VERSION "HNNBNNNYNNNNNNNNNNNNNNNNNNNNNNNNNNNNNNNNNN/4/%%%/4/'%**4NNN///"

NS_ :

BS_:

BU_: AFS_B8 Airbag_B8 Daempfer_B8 Gateway_B8 Getriebe_AL6000 Getriebe_DL5001 Getriebe_VL3002 LWR_B8 Motor_EDC17_003 Motor_EDC17_004 Motor_MED17_B8 Motor_MED9_B8 Motor_SIMOS8_B8 Motor_Slave_B8 Getriebe_AL1000 Motor_MED17_SIMOS8 Motor_EDC17 Gateway_Routing_PAG Gateway_VW EPB_D4 Motor_EDC17_D4 Motor_MED17_003 Hybrid_MSG Hybrid_DQ200 Motor_ME17_BY Motor_MED17_SIMOS8_D4 Motor_EDC17_B8 Getriebe_AL551_951_D4_C7 Getriebe_AL551_Hybrid_D4_C7 Getriebe_DL501_C7 Getriebe_VL381_C7 Motor_MED17_SIMOS8_D4_Hybrid SCU_D4 Gateway_D4C7 Motor_MED17_Q5_Hybrid Fahrwerk STH_D4 Airbag_D4 Gateway_PAG_002 Gateway_VW_T003 Gateway_D4 LEH_Hybrid SCR_C7 BMS_Hybrid Gateway_App_PAG Getriebe_AL1004 Motor_MED17_006 Getriebe_AL5000

BO_ 262 ESP_05: 8 Gateway_D4C7
 SG_ ESP_05_CHK : 0|8@1+ (1,0) [0|255] ""  EPB_D4,Getriebe_AL551_951_D4_C7,Getriebe_AL551_Hybrid_D4_C7,Getriebe_DL501_C7,Getriebe_VL381_C7,Motor_EDC17_D4,Motor_ME17_BY,Motor_MED17_SIMOS8_D4,Motor_MED17_SIMOS8_D4_Hybrid,SCU_D4
 SG_ ESP_05_BZ : 8|4@1+ (1,0) [0|15] ""  EPB_D4,Getriebe_AL551_951_D4_C7,Getriebe_AL551_Hybrid_D4_C7,Getriebe_DL501_C7,Getriebe_VL381_C7,Motor_EDC17_D4,Motor_ME17_BY,Motor_MED17_SIMOS8_D4,Motor_MED17_SIMOS8_D4_Hybrid,SCU_D4
 SG_ ESP_QBit_Bremsdruck : 12|1@1+ (1,0) [0|1] ""  EPB_D4,Getriebe_AL551_951_D4_C7,Getriebe_AL551_Hybrid_D4_C7,Getriebe_DL501_C7,Motor_EDC17_D4,Motor_ME17_BY,Motor_MED17_SIMOS8_D4,Motor_MED17_SIMOS8_D4_Hybrid
 SG_ ESP_QBit_Fahrer_bremst : 13|1@1+ (1,0) [0|1] ""  Motor_EDC17_D4,Motor_ME17_BY,Motor_MED17_SIMOS8_D4,Motor_MED17_SIMOS8_D4_Hybrid
 SG_ ESP_Schwelle_Unterdruck : 14|2@1+ (1,0) [0|3] "" Vector__XXX
 SG_ ESP_Bremsdruck : 16|10@1+ (0.3,-30) [-30|276.6] "Unit_Bar"  EPB_D4,Getriebe_AL551_951_D4_C7,Getriebe_AL551_Hybrid_D4_C7,Getriebe_DL501_C7,Motor_EDC17_D4,Motor_ME17_BY,Motor_MED17_SIMOS8_D4,Motor_MED17_SIMOS8_D4_Hybrid
 SG_ ESP_Fahrer_bremst : 26|1@1+ (1,0) [0|1] ""  Motor_EDC17_D4,Motor_ME17_BY,Motor_MED17_SIMOS8_D4,Motor_MED17_SIMOS8_D4_Hybrid
 SG_ ESP_Verz_TSK_aktiv : 27|1@1+ (1,0) [0|1] ""  Getriebe_AL551_951_D4_C7,Getriebe_AL551_Hybrid_D4_C7,Motor_EDC17_D4,Motor_ME17_BY,Motor_MED17_SIMOS8_D4,Motor_MED17_SIMOS8_D4_Hybrid
 SG_ ESP_Lenkeingriff_ADS : 28|1@1+ (1,0) [0|1] ""  Motor_EDC17_D4,Motor_ME17_BY,Motor_MED17_SIMOS8_D4,Motor_MED17_SIMOS8_D4_Hybrid,SCU_D4
 SG_ ESP_Konsistenz_TSK : 29|1@1+ (1,0) [0|1] ""  Motor_EDC17_D4,Motor_ME17_BY,Motor_MED17_SIMOS8_D4,Motor_MED17_SIMOS8_D4_Hybrid
 SG_ ESP_Bremsruck_AWV2 : 30|1@1+ (1,0) [0|1] "" Vector__XXX
 SG_ ESP_Konsistenz_AWV2 : 31|1@1+ (1,0) [0|1] "" Vector__XXX
 SG_ ECD_Fehler : 32|1@1+ (1,0) [0|1] ""  Motor_EDC17_D4,Motor_ME17_BY,Motor_MED17_SIMOS8_D4,Motor_MED17_SIMOS8_D4_Hybrid
 SG_ ECD_nicht_verfuegbar : 33|1@1+ (1,0) [0|1] ""  Motor_EDC17_D4,Motor_ME17_BY,Motor_MED17_SIMOS8_D4,Motor_MED17_SIMOS8_D4_Hybrid
 SG_ ESP_Status_Bremsentemp : 34|1@1+ (1,0) [0|1] ""  Motor_EDC17_D4,Motor_ME17_BY,Motor_MED17_SIMOS8_D4,Motor_MED17_SIMOS8_D4_Hybrid
 SG_ ESP_Autohold_Standby : 35|1@1+ (1,0) [0|1] ""  EPB_D4,Getriebe_AL551_951_D4_C7,Getriebe_AL551_Hybrid_D4_C7
 SG_ ESP_HDC_Standby : 36|1@1+ (1,0) [0|1] "" Vector__XXX
 SG_ ESP_HBA_aktiv : 37|1@1+ (1,0) [0|1] "" Vector__XXX
 SG_ ESP_Prefill_ausgeloest : 38|1@1+ (1,0) [0|1] "" Vector__XXX
 SG_ ESP_Rueckwaertsfahrt_erkannt : 39|1@1+ (1,0) [0|1] ""  Motor_EDC17_D4,Motor_ME17_BY,Motor_MED17_SIMOS8_D4,Motor_MED17_SIMOS8_D4_Hybrid
 SG_ ESP_Status_Anfahrhilfe : 40|1@1+ (1,0) [0|1] ""  Motor_EDC17_D4,Motor_MED17_SIMOS8_D4,Motor_MED17_SIMOS8_D4_Hybrid
 SG_ ESP_HDC_aktiv : 41|1@1+ (1,0) [0|1] "" Vector__XXX
 SG_ ESP_StartStopp_Info : 42|2@1+ (1,0) [0|3] ""  Motor_EDC17_D4,Motor_ME17_BY,Motor_MED17_SIMOS8_D4,Motor_MED17_SIMOS8_D4_Hybrid
 SG_ ESP_Eingr_HL : 44|1@1+ (1,0) [0|1] "" Vector__XXX
 SG_ ESP_Eingr_HR : 45|1@1+ (1,0) [0|1] "" Vector__XXX
 SG_ ESP_Eingr_VL : 46|1@1+ (1,0) [0|1] "" Vector__XXX
 SG_ ESP_Eingr_VR : 47|1@1+ (1,0) [0|1] "" Vector__XXX
 SG_ ESP_BKV_Unterdruck : 48|8@1+ (4,0) [0|1012] "Unit_MilliBar"  Motor_EDC17_D4,Motor_ME17_BY,Motor_MED17_SIMOS8_D4,Motor_MED17_SIMOS8_D4_Hybrid
 SG_ ESP_Autohold_aktiv : 56|1@1+ (1,0) [0|1] ""  EPB_D4,Getriebe_AL551_951_D4_C7,Getriebe_AL551_Hybrid_D4_C7,Getriebe_DL501_C7,Getriebe_VL381_C7,Motor_EDC17_D4,Motor_ME17_BY,Motor_MED17_SIMOS8_D4,Motor_MED17_SIMOS8_D4_Hybrid
 SG_ ESP_FStatus_Anfahrhilfe : 57|1@1+ (1,0) [0|1] "" Vector__XXX
 SG_ ESP_Verz_EPB_aktiv : 58|1@1+ (1,0) [0|1] ""  EPB_D4,Getriebe_AL551_951_D4_C7,Getriebe_AL551_Hybrid_D4_C7
 SG_ ECD_Bremslicht : 59|1@1+ (1,0) [0|1] ""  Motor_EDC17_D4,Motor_ME17_BY,Motor_MED17_SIMOS8_D4,Motor_MED17_SIMOS8_D4_Hybrid
 SG_ ESP_Verzoeg_EPB_verf : 60|1@1+ (1,0) [0|1] ""  EPB_D4
 SG_ ESP_Status_Bremsdruck : 61|1@1+ (1,0) [0|1] ""  EPB_D4,Motor_EDC17_D4,Motor_ME17_BY,Motor_MED17_SIMOS8_D4,Motor_MED17_SIMOS8_D4_Hybrid
 SG_ ESP_Anforderung_EPB : 62|2@1+ (1,0) [0|3] ""  EPB_D4

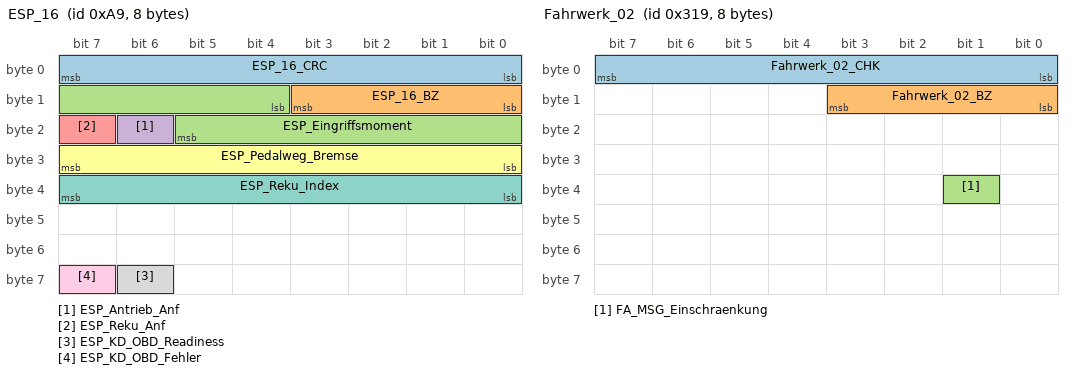
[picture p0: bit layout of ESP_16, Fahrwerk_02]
BO_ 169 ESP_16: 8 Gateway_B8
 SG_ ESP_16_CRC : 0|8@1+ (1,0) [0|255] ""  Motor_MED17_Q5_Hybrid
 SG_ ESP_16_BZ : 8|4@1+ (1,0) [0|15] ""  Motor_MED17_Q5_Hybrid
 SG_ ESP_Eingriffsmoment : 12|10@1+ (1,-509) [-509|509] "Unit_NewtoMeter"  Motor_MED17_Q5_Hybrid
 SG_ ESP_Antrieb_Anf : 22|1@1+ (1,0) [0|1] ""  Motor_MED17_Q5_Hybrid
 SG_ ESP_Reku_Anf : 23|1@1+ (1,0) [0|1] ""  Motor_MED17_Q5_Hybrid
 SG_ ESP_Pedalweg_Bremse : 24|8@1+ (0.2,0) [0|50] "Unit_DegreOfArc"  Motor_MED17_Q5_Hybrid
 SG_ ESP_Reku_Index : 32|8@1+ (0.0039526,0) [0|1] "-"  Motor_MED17_Q5_Hybrid
 SG_ ESP_KD_OBD_Readiness : 62|1@1+ (1,0) [0|1] ""  Motor_MED17_Q5_Hybrid
 SG_ ESP_KD_OBD_Fehler : 63|1@1+ (1,0) [0|1] ""  Motor_MED17_Q5_Hybrid

BO_ 914 ESP_07_FR: 8 Gateway_B8
 SG_ ESP_07_CHK : 0|8@1+ (1,0) [0|255] ""  Motor_MED17_Q5_Hybrid
 SG_ ESP_07_BZ : 8|4@1+ (1,0) [0|15] ""  Motor_MED17_Q5_Hybrid
 SG_ ESP_ACC_LDE : 12|1@1+ (1,0) [0|1] "" Vector__XXX
 SG_ ESP_Quattro_Antrieb : 13|1@1+ (1,0) [0|1] "" Vector__XXX
 SG_ ESP_Codierung_ADS : 14|2@1+ (1,0) [0|3] "" Vector__XXX
 SG_ ESP_RTA_HL : 16|8@1+ (0.048828125,-6.20117) [-6.20117|6.152345625] "Unit_PerCent" Vector__XXX
 SG_ ESP_RTA_HR : 24|8@1+ (0.048828125,-6.20117) [-6.20117|6.152345625] "Unit_PerCent" Vector__XXX
 SG_ ESP_RTA_VR : 32|8@1+ (0.048828125,-6.20117) [-6.20117|6.152345625] "Unit_PerCent" Vector__XXX
 SG_ OBD_Fehler_Radsensor_HL : 40|4@1+ (1,0) [0|15] ""  Motor_MED17_Q5_Hybrid
 SG_ OBD_Fehler_Radsensor_HR : 44|4@1+ (1,0) [0|15] ""  Motor_MED17_Q5_Hybrid
 SG_ OBD_Fehler_Radsensor_VL : 48|4@1+ (1,0) [0|15] ""  Motor_MED17_Q5_Hybrid
 SG_ OBD_Fehler_Radsensor_VR : 52|4@1+ (1,0) [0|15] ""  Motor_MED17_Q5_Hybrid
 SG_ ESP_Qualifizierung_Antriebsart : 56|1@1+ (1,0) [0|1] "" Vector__XXX
 SG_ ESP_Offroad_Modus : 57|1@1+ (1,0) [0|1] "" Vector__XXX
 SG_ ESP_MKB_ausloesbar : 58|1@1+ (1,0) [0|1] "" Vector__XXX
 SG_ ESP_MKB_Status : 59|1@1+ (1,0) [0|1] "" Vector__XXX
 SG_ ESP_CM_Variante : 60|1@1+ (1,0) [0|1] "" Vector__XXX
 SG_ ESP_OBD_Status : 61|1@1+ (1,0) [0|1] ""  Motor_MED17_Q5_Hybrid
 SG_ ESP_Rollenmodus_Deaktivieren : 62|1@1+ (1,0) [0|1] ""  Motor_MED17_Q5_Hybrid
 SG_ ESP_nachtr_Stopp_Anf : 63|1@1+ (1,0) [0|1] ""  Motor_MED17_Q5_Hybrid

BO_ 277 Allrad_02: 8 Gateway_Routing_PAG
 SG_ ALR_Sta_Laengssperre : 12|2@1+ (1,0) [0|3] "" Vector__XXX
 SG_ ALR_Sta_Quersperre : 14|2@1+ (1,0) [0|3] "" Vector__XXX
 SG_ ALR_Sta_Untersetzung : 16|3@1+ (1,0) [0|7] ""  Getriebe_AL1000,Motor_EDC17,Motor_MED17_SIMOS8
 SG_ ALR_Limiter : 20|1@1+ (1,0) [0|1] ""  Motor_EDC17,Motor_MED17_SIMOS8
 SG_ ALR_Schalten : 21|1@1+ (1,0) [0|1] ""  Getriebe_AL1000
 SG_ ALR_Vorwarnung : 22|1@1+ (1,0) [0|1] ""  Getriebe_AL1000
 SG_ ALR_ESP_akt : 23|1@1+ (1,0) [0|1] "" Vector__XXX
 SG_ ALR_Begrenzungsmoment : 24|10@1+ (1,0) [0|1021] ""  Motor_EDC17,Motor_MED17_SIMOS8
 SG_ ALR_Charisma_Umschaltung : 34|2@1+ (1,0) [0|3] "" Vector__XXX
 SG_ ALR_Temp_schutz : 36|1@1+ (1,0) [0|1] "" Vector__XXX
 SG_ ALR_Offroad : 37|1@1+ (1,0) [0|1] ""  Getriebe_AL1000,Motor_EDC17,Motor_MED17_SIMOS8
 SG_ ALR_Sta_Begrenzungsmom : 38|2@1+ (1,0) [0|3] "" Vector__XXX
 SG_ ALR_Charisma_FahrPr : 40|3@1+ (1,0) [0|7] "" Vector__XXX
 SG_ ALR_Charisma_Status : 43|2@1+ (1,0) [0|3] "" Vector__XXX
 SG_ ALR_Fahrerwunsch : 45|3@1+ (1,0) [0|7] "" Vector__XXX
 SG_ ALR_Symbol_Low : 48|1@1+ (1,0) [0|1] "" Vector__XXX
 SG_ ALR_Symbol_Lock : 49|1@1+ (1,0) [0|1] "" Vector__XXX
 SG_ ALR_Symbol_RearLock : 50|1@1+ (1,0) [0|1] "" Vector__XXX
 SG_ ALR_Texte : 51|5@1+ (1,0) [0|31] "" Vector__XXX
 SG_ ALR_Sta_PrioAnzeige : 56|1@1+ (1,0) [0|1] "" Vector__XXX
 SG_ ALR_LED_Auto_Diff : 58|1@1+ (1,0) [0|1] "" Vector__XXX
 SG_ ALR_LED_High : 59|1@1+ (1,0) [0|1] "" Vector__XXX
 SG_ ALR_LED_Low : 60|1@1+ (1,0) [0|1] "" Vector__XXX
 SG_ ALR_LED_Low_Lock : 61|1@1+ (1,0) [0|1] "" Vector__XXX
 SG_ ALR_LED_Rear_Lock : 62|1@1+ (1,0) [0|1] "" Vector__XXX
 SG_ ALR_KD_Fehler : 63|1@1+ (1,0) [0|1] "" Vector__XXX

BO_ 793 Fahrwerk_02: 8 Fahrwerk
 SG_ Fahrwerk_02_CHK : 0|8@1+ (1,0) [0|255] "" Vector__XXX
 SG_ Fahrwerk_02_BZ : 8|4@1+ (1,0) [0|15] "" Vector__XXX
 SG_ FA_MSG_Einschraenkung : 33|1@1+ (1,0) [0|1] "" Vector__XXX

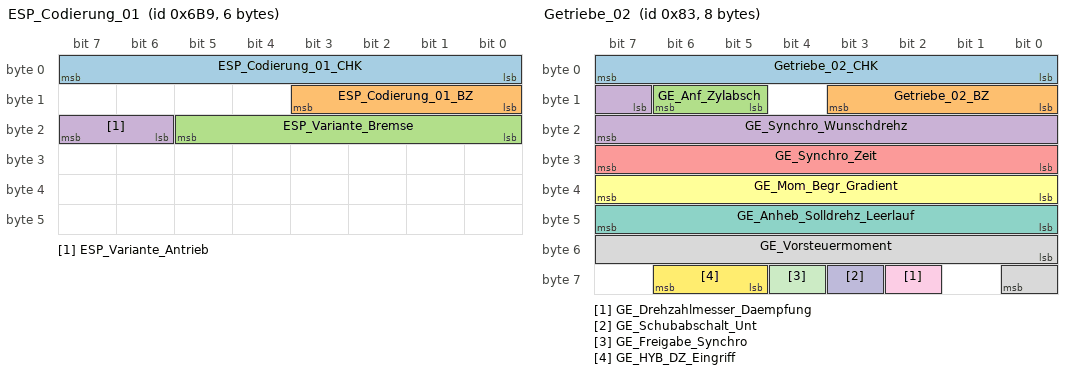
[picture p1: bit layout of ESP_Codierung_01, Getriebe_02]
BO_ 1721 ESP_Codierung_01: 6 Airbag_B8
 SG_ ESP_Codierung_01_CHK : 0|8@1+ (1,0) [0|255] ""  Gateway_B8
 SG_ ESP_Codierung_01_BZ : 8|4@1+ (1,0) [0|15] ""  Gateway_B8
 SG_ ESP_Variante_Bremse : 16|6@1+ (1,0) [0|63] ""  Gateway_B8
 SG_ ESP_Variante_Antrieb : 22|2@1+ (1,0) [0|3] ""  Gateway_B8

BO_ 264 Fahrwerk_01: 8 Daempfer_B8
 SG_ Fahrwerk_01_CHK : 0|8@1+ (1,0) [0|255] ""  Gateway_B8
 SG_ Fahrwerk_01_BZ : 8|4@1+ (1,0) [0|15] ""  Gateway_B8
 SG_ FA_Hoehenwerte_kalibriert M : 12|1@1+ (1,0) [0|1] ""  AFS_B8,Gateway_B8,LWR_B8
 SG_ FA_Hoehenwert_VL_00 m0 : 16|8@1+ (1,-127) [-127|126] "mm"  AFS_B8,Gateway_B8,LWR_B8
 SG_ FA_Hoehenwert_VL_01 m1 : 16|8@1+ (0.4,0) [0|100] "%"  AFS_B8,Gateway_B8,LWR_B8
 SG_ FA_Hoehenwert_VR_00 m0 : 24|8@1+ (1,-127) [-127|126] "mm"  AFS_B8,Gateway_B8,LWR_B8
 SG_ FA_Hoehenwert_VR_01 m1 : 24|8@1+ (0.4,0) [0|100] "%"  AFS_B8,Gateway_B8,LWR_B8
 SG_ FA_Hoehenwert_HL_00 m0 : 32|8@1+ (1,-127) [-127|126] "mm"  AFS_B8,Gateway_B8,LWR_B8
 SG_ FA_Hoehenwert_HL_01 m1 : 32|8@1+ (0.4,0) [0|100] "%"  AFS_B8,Gateway_B8,LWR_B8
 SG_ FA_Hoehenwert_HR_00 m0 : 40|8@1+ (1,-127) [-127|126] "mm"  AFS_B8,Gateway_B8,LWR_B8
 SG_ FA_Hoehenwert_HR_01 m1 : 40|8@1+ (0.4,0) [0|100] "%"  AFS_B8,Gateway_B8,LWR_B8

BO_ 924 Gateway_05: 8 Gateway_B8
 SG_ BCM1_Schalter_StartStopp : 55|1@1+ (1,0) [0|0] "" Vector__XXX
 SG_ PH_StartStopp_Info : 28|2@1+ (1,0) [0|0] "" Vector__XXX
 SG_ BCM1_02_alt : 0|1@1+ (1,0) [0|1] ""  Motor_EDC17_D4,Motor_MED17_003
 SG_ Wischer_01_alt : 1|1@1+ (1,0) [0|1] ""  Motor_EDC17_D4
 SG_ Klima_02_alt : 2|1@1+ (1,0) [0|1] ""  STH_D4
 SG_ BCM1_01_alt : 3|1@1+ (1,0) [0|1] ""  EPB_D4,Motor_EDC17_D4,Motor_MED17_003
 SG_ ESP_07_alt : 4|1@1+ (1,0) [0|1] ""  Airbag_D4,Motor_EDC17_D4,Motor_MED17_003
 SG_ TSG_BT_1_alt : 5|1@1+ (1,0) [0|1] "" Vector__XXX
 SG_ TSG_HL_1_alt : 6|1@1+ (1,0) [0|1] "" Vector__XXX
 SG_ TSG_HR_1_alt : 7|1@1+ (1,0) [0|1] "" Vector__XXX
 SG_ Motor_02_alt : 8|1@1+ (1,0) [0|1] ""  SCU_D4
 SG_ Klima_Sensor_02_alt : 9|1@1+ (1,0) [0|1] ""  Motor_EDC17_D4,Motor_MED17_003
 SG_ TSG_FT_1_alt : 10|1@1+ (1,0) [0|1] ""  Motor_EDC17_D4,Motor_MED17_003
 SG_ Motor_05_alt : 11|1@1+ (1,0) [0|1] ""  STH_D4
 SG_ QSP_01_alt : 12|1@1+ (1,0) [0|1] ""  Motor_EDC17_D4,Motor_MED17_003
 SG_ Parkhilfe_01_alt : 13|1@1+ (1,0) [0|1] ""  Motor_EDC17_D4,Motor_MED17_003
 SG_ Fahrwerk_02_alt : 14|1@1+ (1,0) [0|1] ""  Motor_EDC17_D4,Motor_MED17_003
 SG_ GW_05_va_27 : 15|1@1+ (1,0) [0|1] "" Vector__XXX
 SG_ BCM1_MH_WIV_Schalter : 16|1@1+ (1,0) [0|1] ""  Motor_EDC17_D4,Motor_MED17_003
 SG_ Wischer_vorne_aktiv : 17|1@1+ (1,0) [0|1] ""  Motor_EDC17_D4
 SG_ BCM1_Rueckfahrlicht_Schalter : 18|1@1+ (1,0) [0|1] ""  EPB_D4,Motor_EDC17_D4,Motor_MED17_003
 SG_ MO_Status_Normalbetrieb_01 : 19|1@1+ (1,0) [0|1] ""  SCU_D4
 SG_ KL_Zuheizer_Freigabe : 20|1@1+ (1,0) [0|1] ""  STH_D4
 SG_ BCM1_Vorwaertsgang_eingelegt : 21|1@1+ (1,0) [0|1] ""  EPB_D4
 SG_ ESP_Codierung_ADS : 22|2@1+ (1,0) [0|3] ""  Airbag_D4,Motor_EDC17_D4,Motor_MED17_003
 SG_ QSP_StartStopp_Info : 24|2@1+ (1,0) [0|3] ""  Motor_EDC17_D4,Motor_MED17_003
 SG_ FA_StartStopp_Info : 26|2@1+ (1,0) [0|3] ""  Motor_EDC17_D4,Motor_MED17_003
 SG_ PH_StartStopp_Info : 28|2@1+ (1,0) [0|3] ""  Motor_EDC17_D4,Motor_MED17_003
 SG_ BCM1_RFahrlicht_Fzg_Anf : 32|1@1+ (1,0) [0|1] "" Vector__XXX
 SG_ FT_Tuer_geoeffnet : 33|1@1+ (1,0) [0|1] ""  Motor_EDC17_D4,Motor_MED17_003
 SG_ MO_Handshake_STH : 34|1@1+ (1,0) [0|1] ""  STH_D4
 SG_ FT_Sperrklinke : 35|1@1+ (1,0) [0|1] "" Vector__XXX
 SG_ BCM1_OBD_FStatus_ATemp : 36|4@1+ (1,0) [0|15] ""  Airbag_D4,Motor_EDC17_D4,Motor_MED17_003
 SG_ BCM1_Aussen_Temp_ungef : 40|8@1+ (0.5,-50) [-50|76] "Unit_DegreCelsi"  Airbag_D4,Motor_EDC17_D4,Motor_MED17_003
 SG_ BCM1_Oeldruck_Schalter : 48|1@1+ (1,0) [0|1] ""  Motor_EDC17_D4,Motor_MED17_003
 SG_ BCM1_Oeldruck_Schalter_2 : 49|1@1+ (1,0) [0|1] "" Vector__XXX
 SG_ BT_Tuer_geoeffnet : 50|1@1+ (1,0) [0|1] "" Vector__XXX
 SG_ HL_Tuer_geoeffnet : 51|1@1+ (1,0) [0|1] "" Vector__XXX
 SG_ HR_Tuer_geoeffnet : 52|1@1+ (1,0) [0|1] "" Vector__XXX
 SG_ BCM1_Adaptive_Lichtvert_Anf : 53|1@1+ (1,0) [0|1] "" Vector__XXX
 SG_ BCM1_Gleitende_Leuchtw_Anf : 54|1@1+ (1,0) [0|1] "" Vector__XXX
 SG_ BCM1_Schalter_StartStopp : 55|1@1+ (1,0) [0|1] ""  Motor_EDC17_D4,Motor_MED17_003
 SG_ KL_HSH_ein_Soll : 59|1@1+ (1,0) [0|1] ""  Motor_EDC17_D4,Motor_MED17_003

BO_ 1604 Gateway_11: 8 Gateway_D4C7
 SG_ SMLS_01_alt : 0|1@1+ (1,0) [0|1] ""  Motor_EDC17_D4,Motor_ME17_BY,Motor_MED17_SIMOS8_D4
 SG_ HUD_01_alt : 1|1@1+ (1,0) [0|1] "" Vector__XXX
 SG_ BCM1_01_alt : 2|1@1+ (1,0) [0|1] "" Vector__XXX
 SG_ BCM1_02_alt : 3|1@1+ (1,0) [0|1] ""  Motor_EDC17_D4,Motor_ME17_BY,Motor_MED17_SIMOS8_D4
 SG_ BCM2_02_alt : 4|1@1+ (1,0) [0|1] ""  Getriebe_VL381_C7
 SG_ HYB_Anf_E_Mode_alt : 5|1@1+ (1,0) [0|1] "" Vector__XXX
 SG_ BCM1_04_alt : 6|1@1+ (1,0) [0|1] "" Vector__XXX
 SG_ ESP_04_alt : 7|1@1+ (1,0) [0|1] ""  SCU_D4
 SG_ GW_11_va_20 : 8|1@1+ (1,0) [0|1] "" Vector__XXX
 SG_ GW_11_va_21 : 9|1@1+ (1,0) [0|1] "" Vector__XXX
 SG_ GW_11_va_22 : 10|1@1+ (1,0) [0|1] "" Vector__XXX
 SG_ GW_11_va_23 : 11|1@1+ (1,0) [0|1] "" Vector__XXX
 SG_ GW_11_va_24 : 12|1@1+ (1,0) [0|1] "" Vector__XXX
 SG_ GW_11_va_25 : 13|1@1+ (1,0) [0|1] "" Vector__XXX
 SG_ GW_11_va_26 : 14|1@1+ (1,0) [0|1] "" Vector__XXX
 SG_ GW_11_va_27 : 15|1@1+ (1,0) [0|1] "" Vector__XXX
 SG_ BH_Blinker_li : 16|1@1+ (1,0) [0|1] ""  Motor_EDC17_D4,Motor_ME17_BY,Motor_MED17_SIMOS8_D4
 SG_ BH_Blinker_re : 17|1@1+ (1,0) [0|1] ""  Motor_EDC17_D4,Motor_ME17_BY,Motor_MED17_SIMOS8_D4
 SG_ BM_Autobahn : 18|1@1+ (1,0) [0|1] "" Vector__XXX
 SG_ BH_Fernlicht : 19|1@1+ (1,0) [0|1] "" Vector__XXX
 SG_ BH_Lichthupe : 20|1@1+ (1,0) [0|1] "" Vector__XXX
 SG_ BCM1_MH_Schalter : 21|1@1+ (1,0) [0|1] ""  Motor_EDC17_D4,Motor_ME17_BY,Motor_MED17_SIMOS8_D4
 SG_ HYB_Anf_E_Mode : 22|1@1+ (1,0) [0|1] "" Vector__XXX
 SG_ HUD_NV_in_Anzeige : 23|1@1+ (1,0) [0|1] "" Vector__XXX
 SG_ BCM1_Touristen_Licht_Anf : 24|1@1+ (1,0) [0|1] "" Vector__XXX
 SG_ LV_Abblendlicht_li_def : 25|1@1+ (1,0) [0|1] "" Vector__XXX
 SG_ LV_Abblendlicht_re_def : 26|1@1+ (1,0) [0|1] "" Vector__XXX
 SG_ LV_Abblendlicht_Anzeige : 27|1@1+ (1,0) [0|1] "" Vector__XXX
 SG_ LV_AFL_aktiv_Anzeige : 28|1@1+ (1,0) [0|1] "" Vector__XXX
 SG_ BCM1_Licht_Dunkelheit_aktiv : 29|1@1+ (1,0) [0|1] "" Vector__XXX
 SG_ LV_Nebelschlusslicht_Anzeige : 30|1@1+ (1,0) [0|1] "" Vector__XXX
 SG_ BCM1_Linksverkehr : 31|1@1+ (1,0) [0|1] "" Vector__XXX
 SG_ BCM2_P_verriegelt : 32|1@1+ (1,0) [0|1] ""  Getriebe_VL381_C7
 SG_ BCM1_LDS_Stellung : 33|3@1+ (1,0) [0|7] "" Vector__XXX
 SG_ BCM1_Allwetterlicht_Anf : 36|1@1+ (1,0) [0|1] "" Vector__XXX
 SG_ HUD_Anzeigefehler_NV : 37|1@1+ (1,0) [0|1] "" Vector__XXX
 SG_ ESP_Diagnose : 38|1@1+ (1,0) [0|1] ""  SCU_D4
 SG_ ZV_Tankklappenstatus : 39|1@1+ (1,0) [0|1] "" Vector__XXX
 SG_ BCM_Tankwunsch : 40|1@1+ (1,0) [0|1] "" Vector__XXX

BO_ 1138 Gateway_MED9_01: 8 Gateway_B8
 SG_ Anhaenger_01_alt : 0|1@1+ (1,0) [0|1] ""  Motor_MED9_B8
 SG_ GW_MED9_01_va_11 : 1|1@1+ (1,0) [0|1] "" Vector__XXX
 SG_ Kombi_01_alt : 2|1@1+ (1,0) [0|1] ""  Motor_MED9_B8
 SG_ STH_01_alt : 3|1@1+ (1,0) [0|1] ""  Motor_MED9_B8
 SG_ Licht_hinten_01_alt : 4|1@1+ (1,0) [0|1] ""  Motor_MED9_B8
 SG_ GW_MED9_01_va_15 : 5|1@1+ (1,0) [0|1] ""  Motor_MED9_B8
 SG_ GW_MED9_01_va_16 : 6|1@1+ (1,0) [0|1] ""  Motor_MED9_B8
 SG_ GW_MED9_01_va_17 : 7|1@1+ (1,0) [0|1] ""  Motor_MED9_B8
 SG_ AAG_BZ : 8|4@1+ (1,0) [0|15] ""  Motor_MED9_B8
 SG_ AAG_Bremsl_durch_ECD : 12|1@1+ (1,0) [0|1] ""  Motor_MED9_B8
 SG_ AAG_Anhaenger_erkannt : 13|1@1+ (1,0) [0|1] ""  Motor_MED9_B8
 SG_ AAG_Bremslicht_H_def : 14|1@1+ (1,0) [0|1] ""  Motor_MED9_B8
 SG_ KBI_Tankwarnung : 27|1@1+ (1,0) [0|1] ""  Motor_MED9_B8
 SG_ KBI_MFA_v_Einheit_01 : 28|1@1+ (1,0) [0|1] ""  Motor_MED9_B8
 SG_ KBI_Einheit_Tacho : 29|1@1+ (1,0) [0|1] ""  Motor_MED9_B8
 SG_ KBI_angez_Geschw : 30|10@1+ (0.32,0) [0|325.12] "km/h"  Motor_MED9_B8
 SG_ STH_Ventiloeffnungszeit : 40|6@1+ (1,0) [0|63] "min"  Motor_MED9_B8
 SG_ STH_EKP_Anst : 46|1@1+ (1,0) [0|1] ""  Motor_MED9_B8
 SG_ STH_Motorvorwaermung : 47|1@1+ (1,0) [0|1] ""  Motor_MED9_B8
 SG_ STH_Waermeeintrag : 48|6@1+ (1,0) [0|63] ""  Motor_MED9_B8
 SG_ STH_war_aktiv : 54|1@1+ (1,0) [0|1] ""  Motor_MED9_B8
 SG_ Licht_hinten_01_BZ : 56|4@1+ (1,0) [0|15] ""  Motor_MED9_B8
 SG_ BCM2_Bremsl_durch_ECD : 60|1@1+ (1,0) [0|1] ""  Motor_MED9_B8
 SG_ LH_3_Bremsl_def : 61|1@1+ (1,0) [0|1] ""  Motor_MED9_B8
 SG_ LH_Bremsl_li_ges_def : 62|1@1+ (1,0) [0|1] ""  Motor_MED9_B8
 SG_ LH_Bremsl_re_ges_def : 63|1@1+ (1,0) [0|1] ""  Motor_MED9_B8

BO_ 130 Getriebe_01: 8 Getriebe_AL6000
 SG_ Getriebe_01_CHK : 0|8@1+ (1,0) [0|255] ""  Gateway_B8,Motor_EDC17_003,Motor_EDC17_004,Motor_MED17_B8,Motor_MED9_B8,Motor_SIMOS8_B8
 SG_ Getriebe_01_BZ : 8|4@1+ (1,0) [0|15] ""  Gateway_B8,Motor_EDC17_003,Motor_EDC17_004,Motor_MED17_B8,Motor_MED9_B8,Motor_SIMOS8_B8
 SG_ GE_Schaltvorgang : 12|1@1+ (1,0) [0|1] ""  Gateway_B8,Motor_EDC17_003,Motor_EDC17_004,Motor_MED17_B8,Motor_MED9_B8,Motor_SIMOS8_B8
 SG_ GE_Status_Kupplung : 13|2@1+ (1,0) [0|3] ""  Gateway_B8,Motor_EDC17_003,Motor_EDC17_004,Motor_MED17_B8,Motor_MED9_B8,Motor_SIMOS8_B8
 SG_ GE_Verbot_Ausblendung : 15|1@1+ (1,0) [0|1] ""  Gateway_B8,Motor_EDC17_003,Motor_EDC17_004,Motor_MED17_B8,Motor_MED9_B8,Motor_SIMOS8_B8
 SG_ GE_MMom_Soll : 16|10@1+ (1,0) [0|1021] ""  Gateway_B8,Motor_EDC17_003,Motor_EDC17_004,Motor_MED17_B8,Motor_MED9_B8,Motor_SIMOS8_B8
 SG_ GE_MMom_Status : 26|2@1+ (1,0) [0|3] ""  Gateway_B8,Motor_EDC17_003,Motor_EDC17_004,Motor_MED17_B8,Motor_MED9_B8,Motor_SIMOS8_B8
 SG_ GE_Freig_Mmom_Soll : 28|1@1+ (1,0) [0|1] ""  Gateway_B8
 SG_ GE_Status_Schaltablauf : 29|3@1+ (1,0) [0|7] ""  Gateway_B8,Motor_EDC17_003,Motor_EDC17_004,Motor_MED17_B8,Motor_MED9_B8,Motor_SIMOS8_B8
 SG_ GE_Zeit_MZP : 32|8@1+ (10,0) [0|2550] "ms"  Gateway_B8,Motor_EDC17_003,Motor_EDC17_004,Motor_MED17_B8,Motor_MED9_B8,Motor_SIMOS8_B8
 SG_ GE_MMom_Vorhalt : 32|10@1+ (1,0) [0|1021] ""  Gateway_B8,Motor_EDC17_003,Motor_EDC17_004,Motor_MED17_B8,Motor_MED9_B8,Motor_SIMOS8_B8
 SG_ GE_Freig_MMom_Vorhalt : 42|1@1+ (1,0) [0|1] ""  Gateway_B8,Motor_EDC17_003,Motor_EDC17_004,Motor_MED17_B8,Motor_MED9_B8,Motor_SIMOS8_B8
 SG_ GE_Mom_MZP : 48|10@1+ (1,0) [0|1021] ""  Gateway_B8,Motor_EDC17_003,Motor_EDC17_004,Motor_MED17_B8,Motor_MED9_B8,Motor_SIMOS8_B8
 SG_ GE_Freig_Mom_Eingriff : 58|1@1+ (1,0) [0|1] ""  Gateway_B8,Motor_EDC17_003,Motor_EDC17_004,Motor_MED17_B8,Motor_MED9_B8,Motor_SIMOS8_B8
 SG_ GE_Mom_Ident : 59|4@1+ (1,0) [1|14] ""  Gateway_B8,Motor_EDC17_003,Motor_EDC17_004,Motor_MED17_B8,Motor_MED9_B8,Motor_SIMOS8_B8
 SG_ GE_KD_Fehler : 63|1@1+ (1,0) [0|1] ""  Gateway_B8

BO_ 131 Getriebe_02: 8 Getriebe_AL551_951_D4_C7
 SG_ Getriebe_02_CHK : 0|8@1+ (1,0) [0|255] ""  Motor_EDC17_D4,Motor_ME17_BY,Motor_MED17_SIMOS8_D4,Motor_MED17_SIMOS8_D4_Hybrid
 SG_ Getriebe_02_BZ : 8|4@1+ (1,0) [0|15] ""  Motor_EDC17_D4,Motor_ME17_BY,Motor_MED17_SIMOS8_D4,Motor_MED17_SIMOS8_D4_Hybrid
 SG_ GE_Anf_Zylabsch : 13|2@1+ (1,0) [0|3] ""  Motor_ME17_BY,Motor_MED17_SIMOS8_D4,Motor_MED17_SIMOS8_D4_Hybrid
 SG_ GE_Synchro_Wunschdrehz : 15|9@1+ (25,0) [0|12750] "Unit_MinutInver"  Motor_EDC17_D4,Motor_ME17_BY,Motor_MED17_SIMOS8_D4,Motor_MED17_SIMOS8_D4_Hybrid
 SG_ GE_Synchro_Zeit : 24|8@1+ (20,0) [0|5080] "Unit_MilliSecon"  Motor_EDC17_D4,Motor_ME17_BY,Motor_MED17_SIMOS8_D4,Motor_MED17_SIMOS8_D4_Hybrid
 SG_ GE_Mom_Begr_Gradient : 32|8@1+ (10,0) [0|2540] "Unit_NewtoMeterPerSecon"  Motor_EDC17_D4,Motor_ME17_BY,Motor_MED17_SIMOS8_D4,Motor_MED17_SIMOS8_D4_Hybrid
 SG_ GE_Anheb_Solldrehz_Leerlauf : 40|8@1+ (10,0) [0|2540] "Unit_MinutInver"  Motor_EDC17_D4,Motor_ME17_BY,Motor_MED17_SIMOS8_D4,Motor_MED17_SIMOS8_D4_Hybrid
 SG_ GE_Vorsteuermoment : 48|9@1+ (1,0) [0|509] ""  Motor_EDC17_D4,Motor_ME17_BY,Motor_MED17_SIMOS8_D4,Motor_MED17_SIMOS8_D4_Hybrid
 SG_ GE_Drehzahlmesser_Daempfung : 58|1@1+ (1,0) [0|1] ""  Motor_EDC17_D4,Motor_ME17_BY,Motor_MED17_SIMOS8_D4,Motor_MED17_SIMOS8_D4_Hybrid
 SG_ GE_Schubabschalt_Unt : 59|1@1+ (1,0) [0|1] ""  Motor_EDC17_D4,Motor_ME17_BY,Motor_MED17_SIMOS8_D4,Motor_MED17_SIMOS8_D4_Hybrid
 SG_ GE_Freigabe_Synchro : 60|1@1+ (1,0) [0|1] ""  Motor_EDC17_D4,Motor_ME17_BY,Motor_MED17_SIMOS8_D4,Motor_MED17_SIMOS8_D4_Hybrid
 SG_ GE_HYB_DZ_Eingriff : 61|2@1+ (1,0) [0|3] "" Vector__XXX

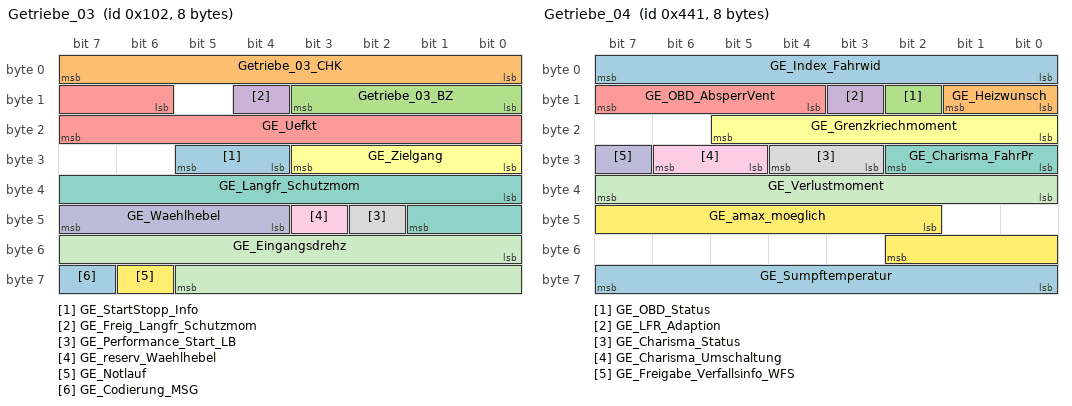
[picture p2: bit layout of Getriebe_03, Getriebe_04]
BO_ 258 Getriebe_03: 8 Getriebe_AL6000
 SG_ GE_StartStopp_Info : 28|2@1+ (1,0) [0|0] "" Vector__XXX
 SG_ Getriebe_03_CHK : 0|8@1+ (1,0) [0|255] ""  Gateway_B8,Motor_EDC17_003,Motor_EDC17_004,Motor_MED17_B8,Motor_MED9_B8,Motor_SIMOS8_B8
 SG_ Getriebe_03_BZ : 8|4@1+ (1,0) [0|15] ""  Gateway_B8,Motor_EDC17_003,Motor_EDC17_004,Motor_MED17_B8,Motor_MED9_B8,Motor_SIMOS8_B8
 SG_ GE_Freig_Langfr_Schutzmom : 12|1@1+ (1,0) [0|1] ""  Gateway_B8,Motor_EDC17_003,Motor_EDC17_004,Motor_MED17_B8,Motor_MED9_B8,Motor_SIMOS8_B8
 SG_ GE_Uefkt : 14|10@1+ (0.1,0) [0|102.2] ""  Gateway_B8,Motor_EDC17_003,Motor_EDC17_004,Motor_MED17_B8,Motor_MED9_B8,Motor_SIMOS8_B8
 SG_ GE_Zielgang : 24|4@1+ (1,0) [0|15] ""  Gateway_B8,Motor_EDC17_003,Motor_EDC17_004,Motor_MED17_B8,Motor_MED9_B8,Motor_SIMOS8_B8
 SG_ GE_Langfr_Schutzmom : 32|10@1+ (1,0) [0|1021] ""  Gateway_B8,Motor_EDC17_003,Motor_EDC17_004,Motor_MED17_B8,Motor_MED9_B8,Motor_SIMOS8_B8
 SG_ GE_Performance_Start_LB : 42|1@1+ (1,0) [0|1] ""  Gateway_B8
 SG_ GE_reserv_Waehlhebel : 43|1@1+ (1,0) [0|1] ""  Gateway_B8
 SG_ GE_Waehlhebel : 44|4@1+ (1,0) [0|15] ""  Gateway_B8,Motor_EDC17_003,Motor_EDC17_004,Motor_MED17_B8,Motor_MED9_B8,Motor_SIMOS8_B8
 SG_ GE_Eingangsdrehz : 48|14@1+ (1,0) [0|16381] "1/min"  Gateway_B8,Motor_EDC17_003,Motor_EDC17_004,Motor_MED17_B8,Motor_MED9_B8,Motor_SIMOS8_B8
 SG_ GE_Notlauf : 62|1@1+ (1,0) [0|1] ""  Gateway_B8,Motor_EDC17_003,Motor_EDC17_004,Motor_MED17_B8,Motor_MED9_B8,Motor_SIMOS8_B8
 SG_ GE_Codierung_MSG : 63|1@1+ (1,0) [0|1] ""  Gateway_B8

BO_ 1089 Getriebe_04: 8 Getriebe_AL551_951_D4_C7
 SG_ GE_Index_Fahrwid : 0|8@1+ (0.249,-31.623) [-31.623|31.623] ""  Gateway_D4C7,Motor_EDC17_D4,Motor_ME17_BY,Motor_MED17_SIMOS8_D4
 SG_ GE_Heizwunsch : 8|2@1+ (1,0) [0|3] ""  Gateway_D4C7,Motor_EDC17_D4,Motor_ME17_BY,Motor_MED17_SIMOS8_D4
 SG_ GE_OBD_Status : 10|1@1+ (1,0) [0|1] ""  Gateway_D4C7,Motor_EDC17_D4,Motor_ME17_BY,Motor_MED17_SIMOS8_D4
 SG_ GE_LFR_Adaption : 11|1@1+ (1,0) [0|1] ""  Gateway_D4C7,Motor_EDC17_D4,Motor_ME17_BY,Motor_MED17_SIMOS8_D4
 SG_ GE_OBD_AbsperrVent : 12|4@1+ (1,0) [0|15] ""  Gateway_D4C7
 SG_ GE_Grenzkriechmoment : 16|6@1+ (2,0) [0|122] ""  Gateway_D4C7
 SG_ GE_Charisma_FahrPr : 24|3@1+ (1,0) [0|7] ""  Gateway_D4C7
 SG_ GE_Charisma_Status : 27|2@1+ (1,0) [0|3] ""  Gateway_D4C7
 SG_ GE_Charisma_Umschaltung : 29|2@1+ (1,0) [0|3] ""  Gateway_D4C7
 SG_ GE_Freigabe_Verfallsinfo_WFS : 31|1@1+ (1,0) [0|1] ""  Gateway_D4C7,Motor_EDC17_D4,Motor_ME17_BY,Motor_MED17_SIMOS8_D4
 SG_ GE_Verlustmoment : 32|8@1+ (1,0) [0|254] ""  EPB_D4,Gateway_D4C7,Motor_EDC17_D4,Motor_ME17_BY,Motor_MED17_SIMOS8_D4
 SG_ GE_amax_moeglich : 42|9@1+ (0.024,-2.016) [-2.016|10.224] "Unit_MeterPerSeconSquar"  Gateway_D4C7,Motor_EDC17_D4,Motor_ME17_BY,Motor_MED17_SIMOS8_D4
 SG_ GE_Sumpftemperatur : 56|8@1+ (1,-58) [-58|196] "Unit_DegreCelsi"  Gateway_D4C7,Motor_EDC17_D4,Motor_ME17_BY,Motor_MED17_SIMOS8_D4

BO_ 1813 ISO_Airbag_01_Req: 8 Gateway_B8
 SG_ ISO_Airbag_01_Req_Data : 0|64@1+ (1,0) [0|1] ""  Airbag_B8

BO_ 1919 ISO_Airbag_01_Resp: 8 Airbag_B8
 SG_ ISO_Airbag_01_Resp_Data : 0|64@1+ (1,0) [0|1] ""  Gateway_B8

BO_ 2022 ISO_EMotor_01_Req: 8 Gateway_B8
 SG_ ISO_EMotor_01_Req_Data : 0|64@1+ (1,0) [0|1] "" Vector__XXX

BO_ 2030 ISO_EMotor_01_Resp: 8 Vector__XXX
 SG_ ISO_EMotor_01_Resp_Data : 0|64@1+ (1,0) [0|1] ""  Gateway_B8

BO_ 1792 ISO_Funktionaler_Req_All: 8 Gateway_B8
 SG_ ISO_ALL_01_Req_Data : 0|64@1+ (1,0) [0|1] ""  Airbag_B8,Getriebe_AL6000,Getriebe_DL5001,Getriebe_VL3002,Motor_EDC17_003,Motor_EDC17_004,Motor_MED17_B8,Motor_MED9_B8,Motor_SIMOS8_B8,Motor_Slave_B8

BO_ 2015 ISO_Funktionaler_Req_OBD: 8 Gateway_B8
 SG_ ISO_OBD_Funktionaler_Req_Data : 0|64@1+ (1,0) [0|1] ""  Airbag_B8,Getriebe_AL6000,Getriebe_DL5001,Getriebe_VL3002,Motor_EDC17_003,Motor_EDC17_004,Motor_MED17_B8,Motor_MED9_B8,Motor_SIMOS8_B8,Motor_Slave_B8

BO_ 2017 ISO_Getriebe_01_Req: 8 Gateway_B8
 SG_ ISO_Getriebe_01_Req_Data : 0|64@1+ (1,0) [0|1] ""  Getriebe_AL6000,Getriebe_DL5001,Getriebe_VL3002

BO_ 2025 ISO_Getriebe_01_Resp: 8 Getriebe_AL6000
 SG_ ISO_Getriebe_01_Resp_Data : 0|64@1+ (1,0) [0|1] ""  Gateway_B8

BO_ 2021 ISO_Hybrid_01_Req: 8 Gateway_B8
 SG_ ISO_Hybrid_01_Req_Data : 0|64@1+ (1,0) [0|1] "" Vector__XXX

BO_ 2029 ISO_Hybrid_01_Resp: 8 Vector__XXX
 SG_ ISO_Hybrid_01_Resp_Data : 0|64@1+ (1,0) [0|1] ""  Gateway_B8

BO_ 2016 ISO_MO_01_Req: 8 Gateway_B8
 SG_ ISO_MO_01_Req_Data : 0|64@1+ (1,0) [0|1] ""  Motor_EDC17_003,Motor_EDC17_004,Motor_MED17_B8,Motor_MED9_B8,Motor_SIMOS8_B8

BO_ 2024 ISO_MO_01_Resp: 8 Motor_EDC17_003
 SG_ ISO_MO_01_Resp_Data : 0|64@1+ (1,0) [0|1] ""  Gateway_B8

BO_ 2018 ISO_MOS_01_Req: 8 Gateway_B8
 SG_ ISO_MOS_01_Req_Data : 0|64@1+ (1,0) [0|1] ""  Motor_Slave_B8

BO_ 2026 ISO_MOS_01_Resp: 8 Motor_Slave_B8
 SG_ ISO_MOS_01_Resp_Data : 0|64@1+ (1,0) [0|1] ""  Gateway_B8

BO_ 2019 ISO_MOS_02_Req: 8 Gateway_B8
 SG_ ISO_MOS_02_Req_Data : 0|64@1+ (1,0) [0|1] "" Vector__XXX

BO_ 2027 ISO_MOS_02_Resp: 8 Vector__XXX
 SG_ ISO_MOS_02_Resp_Data : 0|64@1+ (1,0) [0|1] ""  Gateway_B8

BO_ 2023 ISO_OBD_reserv3_Req: 8 Gateway_B8
 SG_ ISO_OBD_reserv3_Req_Data : 0|64@1+ (1,0) [0|1] "" Vector__XXX

BO_ 2031 ISO_OBD_reserv3_Resp: 8 Vector__XXX
 SG_ ISO_OBD_reserv3_Resp_Data : 0|64@1+ (1,0) [0|1] ""  Gateway_B8

BO_ 2020 ISO_OBD_reserv4_Req: 8 Gateway_B8
 SG_ ISO_OBD_reserv4_Req_Data : 0|64@1+ (1,0) [0|1] "" Vector__XXX

BO_ 2028 ISO_OBD_reserv4_Resp: 8 Vector__XXX
 SG_ ISO_OBD_reserv4_Resp_Data : 0|64@1+ (1,0) [0|1] ""  Gateway_B8

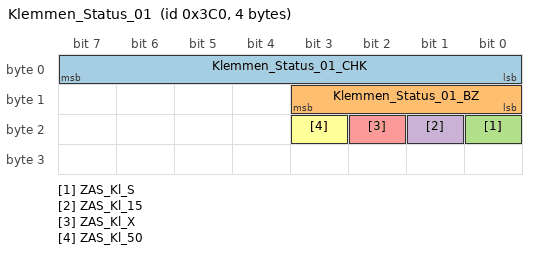
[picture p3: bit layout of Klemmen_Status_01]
BO_ 960 Klemmen_Status_01: 4 Gateway_B8
 SG_ Klemmen_Status_01_CHK : 0|8@1+ (1,0) [0|255] ""  Daempfer_B8,Getriebe_AL6000,Motor_EDC17_003,Motor_EDC17_004,Motor_MED17_B8,Motor_MED9_B8,Motor_SIMOS8_B8
 SG_ Klemmen_Status_01_BZ : 8|4@1+ (1,0) [0|15] ""  Daempfer_B8,Getriebe_AL6000,Motor_EDC17_003,Motor_EDC17_004,Motor_MED17_B8,Motor_MED9_B8,Motor_SIMOS8_B8
 SG_ ZAS_Kl_S : 16|1@1+ (1,0) [0|1] "" Vector__XXX
 SG_ ZAS_Kl_15 : 17|1@1+ (1,0) [0|1] ""  Daempfer_B8,Getriebe_AL6000,Getriebe_DL5001,Motor_EDC17_003,Motor_EDC17_004,Motor_MED17_B8,Motor_MED9_B8,Motor_SIMOS8_B8
 SG_ ZAS_Kl_X : 18|1@1+ (1,0) [0|1] ""  AFS_B8,Daempfer_B8
 SG_ ZAS_Kl_50 : 19|1@1+ (1,0) [0|1] ""  AFS_B8,Daempfer_B8,Motor_EDC17_003,Motor_EDC17_004,Motor_MED17_B8,Motor_MED9_B8,Motor_SIMOS8_B8

BO_ 959 Klima_01: 8 Gateway_D4C7
 SG_ KL_Drehz_Anh : 0|1@1+ (1,0) [0|1] ""  Motor_EDC17_D4,Motor_ME17_BY,Motor_MED17_SIMOS8_D4
 SG_ KL_Vorwarn_Komp_ein : 1|1@1+ (1,0) [0|1] ""  Motor_EDC17_D4,Motor_ME17_BY,Motor_MED17_SIMOS8_D4
 SG_ KL_Handshake_BEM : 2|1@1+ (1,0) [0|1] "" Vector__XXX
 SG_ KL_Komp_Moment_alt : 3|1@1+ (1,0) [0|1] "" Vector__XXX
 SG_ KL_Vorwarn_HHS_ein : 4|1@1+ (1,0) [0|1] ""  Motor_EDC17_D4,Motor_ME17_BY,Motor_MED17_SIMOS8_D4
 SG_ KL_Vorwarn_HFS_ein : 5|1@1+ (1,0) [0|1] ""  Motor_EDC17_D4,Motor_ME17_BY,Motor_MED17_SIMOS8_D4
 SG_ KL_Vorwarn_Zuheizer_ein : 6|1@1+ (1,0) [0|1] "" Vector__XXX
 SG_ KL_KD_Fehler : 7|1@1+ (1,0) [0|1] "" Vector__XXX
 SG_ KL_Comp_rev_rq : 8|8@1+ (50,0) [0|8600] "Unit_MinutInver" Vector__XXX
 SG_ KL_Charisma_FahrPr : 16|3@1+ (1,0) [0|7] "" Vector__XXX
 SG_ KL_Charisma_Status : 19|2@1+ (1,0) [0|3] "" Vector__XXX
 SG_ KL_Charisma_Umschaltung : 21|2@1+ (1,0) [0|3] "" Vector__XXX
 SG_ KL_Last_Kompr : 24|8@1+ (0.25,0) [0|63.5] "Unit_NewtoMeter"  Motor_EDC17_D4,Motor_ME17_BY,Motor_MED17_SIMOS8_D4
 SG_ KL_Leistung_Hzg_Soll : 32|8@1+ (11,0) [0|2805] "Unit_Watt" Vector__XXX
 SG_ KL_Anf_KL : 40|8@1+ (0.4,0) [0|101.6] "Unit_PerCent"  Motor_EDC17_D4,Motor_ME17_BY,Motor_MED17_SIMOS8_D4
 SG_ KL_4_Zonen : 48|1@1+ (1,0) [0|1] ""  Motor_EDC17_D4,Motor_ME17_BY,Motor_MED17_SIMOS8_D4
 SG_ KL_AC_Schalter : 49|1@1+ (1,0) [0|1] ""  Getriebe_AL551_951_D4_C7
 SG_ KL_Zustand : 50|1@1+ (1,0) [0|1] ""  Getriebe_AL551_951_D4_C7,Motor_EDC17_D4,Motor_ME17_BY,Motor_MED17_SIMOS8_D4
 SG_ KL_Thermomanagement : 51|2@1+ (1,0) [0|3] ""  Motor_EDC17_D4,Motor_ME17_BY,Motor_MED17_SIMOS8_D4
 SG_ KL_Comp_enable : 53|1@1+ (1,0) [0|1] "" Vector__XXX
 SG_ KL_StartStopp_Info : 54|2@1+ (1,0) [0|3] ""  Motor_EDC17_D4,Motor_ME17_BY,Motor_MED17_SIMOS8_D4
 SG_ KL_el_Zuheizer_Stufe : 56|3@1+ (1,0) [0|7] ""  Motor_EDC17_D4
 SG_ KL_Diag_Absperrvent : 59|4@1+ (1,0) [0|15] "" Vector__XXX

BO_TX_BU_ 130 : Getriebe_AL6000,Getriebe_DL5001,Getriebe_VL3002;
BO_TX_BU_ 131 : Getriebe_AL6000,Getriebe_DL5001,Getriebe_VL3002;
BO_TX_BU_ 258 : Getriebe_AL6000,Getriebe_DL5001,Getriebe_VL3002;
BO_TX_BU_ 1089 : Getriebe_AL6000,Getriebe_DL5001,Getriebe_VL3002;
BO_TX_BU_ 2025 : Getriebe_AL6000,Getriebe_DL5001,Getriebe_VL3002;
BO_TX_BU_ 2024 : Motor_EDC17_003,Motor_EDC17_004,Motor_MED17_B8,Motor_MED9_B8,Motor_SIMOS8_B8;
CM_ SG_ 262 ESP_05_CHK "Bildung der CHK:

XOR Byte2 XOR Byte 3 ... XOR Byte n  XOR CHK-Endwert  = CHK

Ab B8 ist CHK-Endwert abhängig vom CAN-ID: CHK-Endwert = MSB XOR LSB
MSB: High-Byte des Identifiers der CAN-Botschaft
LSB: Low-Byte des Identifiers der CAN-Botschaft";
CM_ SG_ 262 ESP_QBit_Bremsdruck "QBit des Bremsdrucks";
CM_ SG_ 262 ESP_QBit_Fahrer_bremst "Gültigkeit der redundanten Bremspedalinformation vom ESP SG

0x1 = eingeschränkte Signalgüte

Im B8 gilt die Signalspezifikation LAH8K0907AF: 05-08-23_Lastenheft_Bremslichtinfo_B8_V6.4_yellow.pdf - Bremslichtinfo";
CM_ SG_ 262 ESP_Schwelle_Unterdruck "Vorhalt VW für HBV-Projekte";
CM_ SG_ 262 ESP_Bremsdruck "Bremsdruck / Vordruck durch Fahrervorgabe (Pvor). Bei aktivem Druckaufbau (Stabilisierungseingriffe) kein Pvor
";
CM_ SG_ 262 ESP_Fahrer_bremst "Bit gibt die Information aus, ob der Fahrer gebremst hat oder nicht. Redundante Bremsinformation vom ESP, wird bei Audi im B8 bedient!

Schwelle außerhalb Regelung 12bar, in Regelung 30bar

Im B8 gilt die Signalspezifikation LAH8K0907AF: 05-08-23_Last";
CM_ SG_ 262 ESP_Verz_TSK_aktiv "Rückmeldeinformation an den Triebsstrangkoordinator, dass die Verzögerungsanforderung aktuell umgesetzt wird";
CM_ SG_ 262 ESP_Lenkeingriff_ADS "Im Falle eines fahrzeugstabilisierenden Lenkeingriffs des ADS-Systems soll ACC/GRA deaktiviert werden.";
CM_ SG_ 262 ESP_Konsistenz_TSK "Rückmeldung zum Sender einer Verzögerungsanforderung (Triebstrangskoordinator) bezüglich Prüfung der Checksumme, des Botschaftszählers, des langen Timeout und DLC. Wird auch gesetzt bei Verzögerungsanforderung größer einer applizierbaren Schwelle.
";
CM_ SG_ 262 ESP_Bremsruck_AWV2 "Das Signal dient als Rückmeldung zum ACC, dass ein angeforderter AWV2-Bremsruck durchgeführt wird. Die positive Rückmeldung löst u.a. eine entsprechende Fahrerinformation im Kombiinstrument aus";
CM_ SG_ 262 ESP_Konsistenz_AWV2 "Rückmeldung zum Sender einer AWV-Anforderung (ACC-Steuergerät) bezüglich Prüfung der Checksumme, des Botschaftszählers, des langen Timeout und DLC.
";
CM_ SG_ 262 ECD_Fehler "ESP kann die Verzögerungsregelung/Bremsenregelung aufgrund eines internen Fehlers nicht ausführen, mit Fehlereintrag im ESP.
";
CM_ SG_ 262 ECD_nicht_verfuegbar "ESP kann die Verzögerungsregelung/Bremsenregelung temporär nicht ausführen (z.B. Netzwerkmanagement-Betriebe - KL15 Aus; v<18km/h; ESP in Diagnose, ...), ohne Fehlereintrag im ESP.

";
CM_ SG_ 262 ESP_Status_Bremsentemp "ECD-Bremsscheibentemperaturmodell. Rückmeldung für Sender einer ECD Verzögerungsanforderung, ohne Fehlereintrag im ESP";
CM_ SG_ 262 ESP_Autohold_Standby "Rückmeldung an EPB, dass der Fahrer die Funktion Autohold mindestens einmal angefordert hat. Im Fall eines ESP-Ausfalles oder einer Übernahmeaufforderung erfolgt die EPB-Zuschaltung nur nach Setzen dieses Bits. Bit wird gesetzt nach Betätigung des Autohol";
CM_ SG_ 262 ESP_HDC_Standby "Vorhalt AUDI Q5:
Flag wird vom ESP gesetzt, wenn über den HDC-Taster die HDC-Funktion eingeschalten wurde";
CM_ SG_ 262 ESP_Eingr_HL "Flag wird vom ESP gesetzt, sobald aufgrund eines ESP-Eingriffs am Rad aktiv Druck aufgebaut wird.
Frühestens mit öffnen des Ventils und spätestens bei einem Bremsmoment von 100Nm. Flag bleibt solange gesetzt wie ein Bremsmoment von mehr als 100Nm anliegt";
CM_ SG_ 262 ESP_Eingr_HR "Flag wird vom ESP gesetzt, sobald aufgrund eines ESP-Eingriffs am Rad aktiv Druck aufgebaut wird.
Frühestens mit öffnen des Ventils und spätestens bei einem Bremsmoment von 100Nm. Flag bleibt solange gesetzt wie ein Bremsmoment von mehr als 100Nm anliegt";
CM_ SG_ 262 ESP_Eingr_VL "Flag wird vom ESP gesetzt, sobald aufgrund eines ESP-Eingriffs am Rad aktiv Druck aufgebaut wird.
Frühestens mit öffnen des Ventils und spätestens bei einem Bremsmoment von 100Nm. Flag bleibt solange gesetzt wie ein Bremsmoment von mehr als 100Nm anliegt";
CM_ SG_ 262 ESP_Eingr_VR "Flag wird vom ESP gesetzt, sobald aufgrund eines ESP-Eingriffs am Rad aktiv Druck aufgebaut wird.
Frühestens mit öffnen des Ventils und spätestens bei einem Bremsmoment von 100Nm. Flag bleibt solange gesetzt wie ein Bremsmoment von mehr als 100Nm anliegt";
CM_ SG_ 262 ESP_BKV_Unterdruck "Der maximale Wert wird auf 1016 mbar begrenzr (Vorhalt für HBV-Projekte VW)";
CM_ SG_ 262 ESP_Autohold_aktiv "Rückmeldung an EPB, dass Autohold aktiv ist. Einführung mit Hillholder-Konzept im B8.";
CM_ SG_ 262 ESP_FStatus_Anfahrhilfe "Bei gesetztem Fehler steht die Hillhold-Funktion nicht zur Verfügung
Bit wird nur im Fehlerfall HHC in VL300-Fzg. gesetzt";
CM_ SG_ 262 ESP_Verz_EPB_aktiv "Bei gesetztem Bit wird die Verzögerungsanforderung von EPB umgesetzt.";
CM_ SG_ 262 ECD_Bremslicht "Bremslichtansteuerung durch ECD-Funktion.

Im B8 gilt die Signalspezifikation LAH8K0907AF: 05-08-23_Lastenheft_Bremslichtinfo_B8_V6.4_yellow.pdf - Bremslichtinfo";
CM_ SG_ 262 ESP_Verzoeg_EPB_verf "Bei gesetztem Bit ist der Verzögerungsregeler für EPB verfügbar.";
CM_ SG_ 262 ESP_Status_Bremsdruck "Bei gesetztem Bit liegt p > ca. 2 bar an, hervorgerufen durch Fahrer, ASR, FZR, ECD, Bremsregler ... bei Abfall des Bits ist p < X bar, bei aktivem ECD-Eingriff Ende des Eingriffs
";
CM_ SG_ 262 ESP_Anforderung_EPB "ESP fordert von der EPB Öffnen bzw. Schliessen an. Notwendig wegen Hillholder-Funktion im ESP.
";
CM_ SG_ 1721 ESP_Codierung_01_CHK "Bildung der CHK:

XOR Byte2 XOR Byte 3 ... XOR Byte n  XOR CHK-Endwert  = CHK

Ab B8 ist CHK-Endwert abhängig vom CAN-ID: CHK-Endwert = MSB XOR LSB
MSB: High-Byte des Identifiers der CAN-Botschaft
LSB: Low-Byte des Identifiers der CAN-Botschaft";
CM_ SG_ 264 Fahrwerk_01_CHK "Bildung der CHK:

XOR Byte2 XOR Byte 3 ... XOR Byte n  XOR CHK-Endwert  = CHK

Ab B8 ist CHK-Endwert abhängig vom CAN-ID: CHK-Endwert = MSB XOR LSB
MSB: High-Byte des Identifiers der CAN-Botschaft
LSB: Low-Byte des Identifiers der CAN-Botschaft";
CM_ SG_ 264 FA_Hoehenwerte_kalibriert "Legt fest, wie die Höhensensorwerte interpretiert werden müssen. Umschaltung kalibrierte Höhenwerte / Rohsignale in Byte 3-6

Achtung:
Im AUDI B8 Konstante: 0x1. D.h. es werden nur Rohwerte bient!";
CM_ SG_ 264 FA_Hoehenwert_VL_00 "Aktueller Höhenwert (kalibriert) Vorne Links; ungefiltertes Signal
Einheit, Offset und Faktor sind abhänig von 'FA_Hoehenwert_kalibriert'

Achtung:
Wird im AUDI B8 nicht bedient";
CM_ SG_ 264 FA_Hoehenwert_VL_01 "Aktueller Höhenwert (Rohwerte) Vorne Links; ungefiltertes Signal
Einheit, Offset und Faktor sind abhänig von 'FA_Hoehenwert_kalibriert'";
CM_ SG_ 264 FA_Hoehenwert_VR_00 "Aktueller Höhenwert (kalibriert) Vorne Rechts; ungefiltertes Signal
Einheit, Offset und Faktor sind abhänig von 'FA_Hoehenwert_kalibriert'

Achtung:
Wird im AUDI B8 nicht bedient";
CM_ SG_ 264 FA_Hoehenwert_VR_01 "Aktueller Höhenwert (Rohwerte) Vorne Rechts; ungefiltertes Signal
Einheit, Offset und Faktor sind abhänig von 'FA_Hoehenwert_kalibriert'";
CM_ SG_ 264 FA_Hoehenwert_HL_00 "Aktueller Höhenwert (kalibriert) Hinten Links; ungefiltertes Signal
Einheit, Offset und Faktor sind abhänig von 'FA_Hoehenwert_kalibriert'

Achtung:
Wird im AUDI B8 nicht bedient";
CM_ SG_ 264 FA_Hoehenwert_HL_01 "Aktueller Höhenwert (Rohwerte) Hinten Links; ungefiltertes Signal
Einheit, Offset und Faktor sind abhänig von 'FA_Hoehenwert_kalibriert'";
CM_ SG_ 264 FA_Hoehenwert_HR_00 "Aktueller Höhenwert (kalibriert) Hinten Rechts; ungefiltertes Signal
Einheit, Offset und Faktor sind abhänig von 'FA_Hoehenwert_kalibriert'

Achtung:
Wird im AUDI B8 nicht bedient";
CM_ SG_ 264 FA_Hoehenwert_HR_01 "Aktueller Höhenwert (Rohwerte) Hinten Rechts; ungefiltertes Signal
Einheit, Offset und Faktor sind abhänig von 'FA_Hoehenwert_kalibriert'";
CM_ BO_ 924 "
Botschaft für Antriebs- und Fahrwerks-/Kombi-CAN";
CM_ SG_ 924 BCM1_02_alt "Veraltet Bit für die Signale:

Botschaft Gateway_05:
BCM1_MH_WIV_Schalter
BCM1_Oeldruck_Schalter
BCM1_Oeldruck_Schalter_2

Botschaft Gateway_11:
LV_Abblendlicht_Anzeige
LV_Abblendlicht_li_def
LV_Abblendlicht_re_def

Botschaft Gateway_07:
LV_F";
CM_ SG_ 924 Wischer_01_alt "Veraltet Bit für die Signale:

Botschaft Gateway_04:
Wischer_vorne_defekt

Botschaft Gateway_05:
Wischer_vorne_aktiv

Botschaft Gateway_07:
Wischer_vorne_aktiv";
CM_ SG_ 924 Klima_02_alt "Veraltet Bit für die Signale:

Botschaft Gateway_05:
KL_Zuheizer_Freigabe

Botschaft Gateway_09:
KL_I_Geblaese";
CM_ SG_ 924 BCM1_01_alt "Veraltet Bit für die Signale:

Botschaft Gateway_04:
BCM1_Charisma_Text_1
BCM1_Charisma_Text_2

Botschaft Gateway_05:
BCM1_Rueckfahrlicht_Schalter
BCM1_Vorwaertsgang_eingelegt
BCM1_RFahrlicht_Fzg_Anf

Botschaft Gateway_07:
BCM1_Rueckfahrlicht_";
CM_ SG_ 924 ESP_07_alt "Veraltet Bit für die Signale:

Botschaft Gateway_05:
ESP_Codierung_ADS

Botschaft Gateway_06:
ESP_Codierung_ADS
";
CM_ SG_ 924 TSG_BT_1_alt "
Platzhalter für veraltet Bit in Gatewaybotschaften

GWxx_va_yz

xx: Index der Gatewaybotschaft
y: Byteposition des veraltet Bits
z: Bitposition des veraltet Bits";
CM_ SG_ 924 TSG_HL_1_alt "
Platzhalter für veraltet Bit in Gatewaybotschaften

GWxx_va_yz

xx: Index der Gatewaybotschaft
y: Byteposition des veraltet Bits
z: Bitposition des veraltet Bits";
CM_ SG_ 924 TSG_HR_1_alt "
Platzhalter für veraltet Bit in Gatewaybotschaften

GWxx_va_yz

xx: Index der Gatewaybotschaft
y: Byteposition des veraltet Bits
z: Bitposition des veraltet Bits";
CM_ SG_ 924 Motor_02_alt "
Platzhalter für veraltet Bit in Gatewaybotschaften

GWxx_va_yz

xx: Index der Gatewaybotschaft
y: Byteposition des veraltet Bits
z: Bitposition des veraltet Bits";
CM_ SG_ 924 Klima_Sensor_02_alt "Veraltet Bit für die Signale:

Botschaft Gateway_04:
BCM1_FStatus_Aussentemp_ungef
BCM1_Aussen_Temp_ungef

Botschaft Gateway_05:
BCM1_OBD_FStatus_ATemp
BCM1_Aussen_Temp_ungef

Botschaft Gateway_07:
BCM1_Aussen_Temp_ungef
BCM1_FStatus_Aussentem";
CM_ SG_ 924 TSG_FT_1_alt "Veraltet Bit für die Signale:

Botschaft Gateway_04:
FT_Kisi_Fehler

Botschaft Gateway_05:
FT_Tuer_geoeffnet

Botschaft Gateway_09:
FT_Tuer_geoeffnet";
CM_ SG_ 924 Motor_05_alt "Veraltet-Bit für die Signale:

Botschaft Gateway_01:
MO_Anf_KL75
MO_Verbot_EKP
MO_Anf_Pruefimpuls
MO_Klima_Eingr
MO_Aussp_Anlass
MO_Freig_Anlass

Botschaft Gateway_05:
MO_Handshake_STH

Botschaft Charisma_02:
MO_Charisma_FahrPr
MO_Charisma_";
CM_ SG_ 924 QSP_01_alt "
Platzhalter für veraltet Bit in Gatewaybotschaften

GWxx_va_yz

xx: Index der Gatewaybotschaft
y: Byteposition des veraltet Bits
z: Bitposition des veraltet Bits";
CM_ SG_ 924 Parkhilfe_01_alt "
Platzhalter für veraltet Bit in Gatewaybotschaften

GWxx_va_yz

xx: Index der Gatewaybotschaft
y: Byteposition des veraltet Bits
z: Bitposition des veraltet Bits";
CM_ SG_ 924 Fahrwerk_02_alt "
Platzhalter für veraltet Bit in Gatewaybotschaften

GWxx_va_yz

xx: Index der Gatewaybotschaft
y: Byteposition des veraltet Bits
z: Bitposition des veraltet Bits";
CM_ SG_ 924 GW_05_va_27 "
Platzhalter für veraltet Bit in Gatewaybotschaften

GWxx_va_yz

xx: Index der Gatewaybotschaft
y: Byteposition des veraltet Bits
z: Bitposition des veraltet Bits";
CM_ SG_ 924 BCM1_MH_WIV_Schalter "Bewerteter Motorhaubenkontakt fuer WIV";
CM_ SG_ 924 Wischer_vorne_aktiv "Status: Wischer vorne ";
CM_ SG_ 924 BCM1_Rueckfahrlicht_Schalter "Rückfahrlichtschalter
";
CM_ SG_ 924 KL_Zuheizer_Freigabe "Freigabe Zuheizer
";
CM_ SG_ 924 BCM1_Vorwaertsgang_eingelegt "Erkennung Vorwärtsgang eingelegt (1. / 2. Gang)";
CM_ SG_ 924 ESP_Codierung_ADS "ESP gibt für Empfänger im Fahrzeug aus, ob ADS verbaut/nicht verbaut ist.
";
CM_ SG_ 924 BCM1_RFahrlicht_Fzg_Anf "Anforderung: Rückfahrlicht Fahrzeug (Sollzustand)";
CM_ SG_ 924 MO_Handshake_STH "Es gilt: Signalspec MO_Handshake v1.0

Handshake zwischen MSG und STH. Wenn das MSG die EKP aufgrund einer STH-Anforderung ansteuert und kein Fehlereintrag bzgl. EKP/KPE/NDR vorliegt, wird das Bit gesetzt.";
CM_ SG_ 924 BCM1_OBD_FStatus_ATemp "Fehlerstatus Umgebungstemperatursensor (OBD relevanter Sensor)
";
CM_ SG_ 924 BCM1_Aussen_Temp_ungef "ungefilterter Wert des Aussentemperatursensors
";
CM_ SG_ 924 BCM1_Oeldruck_Schalter "Schalter Oeldruck vorhanden


";
CM_ SG_ 924 BCM1_Oeldruck_Schalter_2 "Schalter Oeldruck vorhanden


";
CM_ BO_ 1604 "
langsame Gatewaybotschaft für den ACAN";
CM_ SG_ 1604 SMLS_01_alt "Veraltet Bit für die Signale:

Botschaft Gateway_07:
BH_Blinker_li
BH_Blinker_re
LDW_Taster
LDW_Taster_Fehler
LDW_Vib_Lenkrad_Fehler
BH_Fernlicht

Botschaft Gateway_11:
BH_Blinker_li
BH_Blinker_re
";
CM_ SG_ 1604 BCM1_01_alt "Veraltet Bit für die Signale:

Botschaft Gateway_04:
BCM1_Charisma_Text_1
BCM1_Charisma_Text_2

Botschaft Gateway_05:
BCM1_Rueckfahrlicht_Schalter
BCM1_Vorwaertsgang_eingelegt
BCM1_RFahrlicht_Fzg_Anf

Botschaft Gateway_07:
BCM1_Rueckfahrlicht_";
CM_ SG_ 1604 BCM1_02_alt "Veraltet Bit für die Signale:

Botschaft Gateway_05:
BCM1_MH_WIV_Schalter
BCM1_Oeldruck_Schalter
BCM1_Oeldruck_Schalter_2

Botschaft Gateway_11:
LV_Abblendlicht_Anzeige
LV_Abblendlicht_li_def
LV_Abblendlicht_re_def

Botschaft Gateway_07:
LV_F";
CM_ SG_ 1604 BCM2_02_alt "Veraltet Bit für die Signale:

Botschaft Gateway_11:
BCM2_P_verriegelt";
CM_ SG_ 1604 HYB_Anf_E_Mode_alt "
Platzhalter für veraltet Bit in Gatewaybotschaften

GWxx_va_yz

xx: Index der Gatewaybotschaft
y: Byteposition des veraltet Bits
z: Bitposition des veraltet Bits";
CM_ SG_ 1604 GW_11_va_20 "
Platzhalter für veraltet Bit in Gatewaybotschaften

GWxx_va_yz

xx: Index der Gatewaybotschaft
y: Byteposition des veraltet Bits
z: Bitposition des veraltet Bits";
CM_ SG_ 1604 GW_11_va_21 "
Platzhalter für veraltet Bit in Gatewaybotschaften

GWxx_va_yz

xx: Index der Gatewaybotschaft
y: Byteposition des veraltet Bits
z: Bitposition des veraltet Bits";
CM_ SG_ 1604 GW_11_va_22 "
Platzhalter für veraltet Bit in Gatewaybotschaften

GWxx_va_yz

xx: Index der Gatewaybotschaft
y: Byteposition des veraltet Bits
z: Bitposition des veraltet Bits";
CM_ SG_ 1604 GW_11_va_23 "
Platzhalter für veraltet Bit in Gatewaybotschaften

GWxx_va_yz

xx: Index der Gatewaybotschaft
y: Byteposition des veraltet Bits
z: Bitposition des veraltet Bits";
CM_ SG_ 1604 GW_11_va_24 "
Platzhalter für veraltet Bit in Gatewaybotschaften

GWxx_va_yz

xx: Index der Gatewaybotschaft
y: Byteposition des veraltet Bits
z: Bitposition des veraltet Bits";
CM_ SG_ 1604 GW_11_va_25 "
Platzhalter für veraltet Bit in Gatewaybotschaften

GWxx_va_yz

xx: Index der Gatewaybotschaft
y: Byteposition des veraltet Bits
z: Bitposition des veraltet Bits";
CM_ SG_ 1604 GW_11_va_26 "
Platzhalter für veraltet Bit in Gatewaybotschaften

GWxx_va_yz

xx: Index der Gatewaybotschaft
y: Byteposition des veraltet Bits
z: Bitposition des veraltet Bits";
CM_ SG_ 1604 GW_11_va_27 "
Platzhalter für veraltet Bit in Gatewaybotschaften

GWxx_va_yz

xx: Index der Gatewaybotschaft
y: Byteposition des veraltet Bits
z: Bitposition des veraltet Bits";
CM_ SG_ 1604 BH_Blinker_li "Blinkerhebel Richtung links
";
CM_ SG_ 1604 BH_Blinker_re "Blinkerhebel Richtung rechts
";
CM_ SG_ 1604 BM_Autobahn "Status Autobahnblinken
";
CM_ SG_ 1604 BCM1_Touristen_Licht_Anf "Anforderung: Touristenlicht (Sollzustand)";
CM_ SG_ 1604 LV_Abblendlicht_li_def "Fehlerstatus Abblendlicht vorne links
";
CM_ SG_ 1604 LV_Abblendlicht_re_def "Fehlerstatus Abblendlicht vorne rechts
";
CM_ SG_ 1604 LV_Abblendlicht_Anzeige "Abblendlicht aktiv";
CM_ SG_ 1604 BCM2_P_verriegelt "Nicht plausibilisiertes Rohsignal des P-Verriegeltschalters vom Wählhebel zur exklusiven Nutzung für Getriebesteuergeräte:
";
CM_ BO_ 1138 "Gatewaybotschaft ausschließlich für Anlaufmotorisierung B8 (MED9)";
CM_ SG_ 1138 Anhaenger_01_alt "Veraltet Bit für die Signale:

Botschaft Gateway_MED9_01:
AAG_Botschaftszaehler
AAG_Bremsl_durch_ECD
AAG_Bremslicht_H_def

MOST Botschaft K_Gateway_01:
AAG_Anhaenger_erkannt";
CM_ SG_ 1138 GW_MED9_01_va_11 "
Platzhalter für veraltet Bit in Gatewaybotschaften

GWxx_va_yz

xx: Index der Gatewaybotschaft
y: Byteposition des veraltet Bits
z: Bitposition des veraltet ";
CM_ SG_ 1138 Kombi_01_alt "Veraltet Bit für die Signale:

Botschaft Gateway_MED9_01:
KBI_Tankwarnung
KBI_MFA_v_Einheit_01
KBI_angez_Geschw
KBI_Einheit_Tacho";
CM_ SG_ 1138 STH_01_alt "Veraltet Bit für die Signale:

Botschaft Gateway_MED9_01:
STH_EKP_Anst
STH_Ventiloeffnungszeit
STH_Waermeeintrag
STH_Motorvorwaermung
STH_war_aktiv";
CM_ SG_ 1138 Licht_hinten_01_alt "Veraltet Bit für die Signale:

Botschaft Gateway_05:
LH_Rueckfahrlicht_aktiv

Gateway_MED9_01:
Licht_hinten_01_BZ
BCM2_Bremsl_durch_ECD
LH_3_Bremsl_def
LH_Bremsl_li_ges_def
LH_Bremsl_re_ges_def
";
CM_ SG_ 1138 GW_MED9_01_va_15 "
Platzhalter für veraltet Bit in Gatewaybotschaften

GWxx_va_yz

xx: Index der Gatewaybotschaft
y: Byteposition des veraltet Bits
z: Bitposition des veraltet ";
CM_ SG_ 1138 GW_MED9_01_va_16 "
Platzhalter für veraltet Bit in Gatewaybotschaften

GWxx_va_yz

xx: Index der Gatewaybotschaft
y: Byteposition des veraltet Bits
z: Bitposition des veraltet ";
CM_ SG_ 1138 GW_MED9_01_va_17 "
Platzhalter für veraltet Bit in Gatewaybotschaften

GWxx_va_yz

xx: Index der Gatewaybotschaft
y: Byteposition des veraltet Bits
z: Bitposition des veraltet ";
CM_ SG_ 1138 AAG_BZ "4bit-Botschaftszaehler, wird in jeder Sendebotschaft inkrementiert

";
CM_ SG_ 1138 AAG_Bremsl_durch_ECD "Bremslicht durch ECD aktiv";
CM_ SG_ 1138 AAG_Anhaenger_erkannt "Erkennung Anhaenger ";
CM_ SG_ 1138 AAG_Bremslicht_H_def "Anhaenger Bremslicht defekt";
CM_ SG_ 1138 KBI_Tankwarnung "Fahrer wird gewarnt, z.Zt. liegt die Warnschwelle bei 7 Liter.";
CM_ SG_ 1138 KBI_MFA_v_Einheit_01 "Einheit der Geschwindigkeit, die vom Fahrer im Car-Menü gewählt wurde. Veränderliche Grösse, im Gegensatz zur Einheit des Tachokranzes.";
CM_ SG_ 1138 KBI_Einheit_Tacho "Information, ob es sich um Meilen- oder Kmh-Kombi handelt, Einheit des Tachos entspricht dem Zifferblatt, Grösse ist nicht veränderlich";
CM_ SG_ 1138 KBI_angez_Geschw "Im Tacho angezeigte Geschwindigkeit inklusive der Voreilung

";
CM_ SG_ 1138 STH_Ventiloeffnungszeit "Die Standheizung sendet an den Motor die Information darüber wie lange das Magnetventil die Wasserkreisläufe von 'klein' aus 'gross' geschaltet hat. ";
CM_ SG_ 1138 STH_EKP_Anst "STH sendet die Anforderung zur Ansteuerung der EKP an den Motor, um Kraftstoffbehälter der STH zu befüllen.";
CM_ SG_ 1138 STH_Motorvorwaermung "Info an der Motor, dass der Aufheizvorgang mit Motorvorwärmung erfolgt ist";
CM_ SG_ 1138 STH_Waermeeintrag "Signal enthält die Brenndauer in 1min-Schritten, über welche die Standheizung gelaufen ist";
CM_ SG_ 1138 STH_war_aktiv "Bit beeinhaltet die Info, dass die Standheizung während der letzten halbe Stunde aktiv war.";
CM_ SG_ 1138 Licht_hinten_01_BZ "überlaufender 4bit Botschaftszaehler; wird in jeder Sendebotschaft inkrementiert";
CM_ SG_ 1138 BCM2_Bremsl_durch_ECD "Bremslicht (ECD-Bremsung)
";
CM_ SG_ 1138 LH_3_Bremsl_def "Fehlerstatus 3. Bremsleuchte
";
CM_ SG_ 1138 LH_Bremsl_li_ges_def "Fehlerstatus Bremslicht hinten links (Detektion Totalausfall)
";
CM_ SG_ 1138 LH_Bremsl_re_ges_def "Fehlerstatus Bremslicht hinten links (Detektion Totalausfall)
";
CM_ SG_ 130 Getriebe_01_CHK "Bildung der CHK:

XOR Byte2 XOR Byte 3 ... XOR Byte n  XOR CHK-Endwert  = CHK

Ab B8 ist CHK-Endwert abhängig vom CAN-ID: CHK-Endwert = MSB XOR LSB
MSB: High-Byte des Identifiers der CAN-Botschaft
LSB: Low-Byte des Identifiers der CAN-Botschaft";
CM_ SG_ 130 GE_Status_Kupplung "Auch für Anfahrkupplung beim VL30 und Kupplung beim Ecodrive (geregelt bedeutet in diesem Fall die Kupplung ist nicht vollständig getrennt bzw. hat Schlupf) genutzt; bei starken Verstellwegen wird 'geöffnet' gesendet (VQ250)";
CM_ SG_ 130 GE_MMom_Soll "Achtung:
Einheitenloser CAN-Wert.
Faktor in MO_Faktor_Momente in Motor_Code_01 beachten!

Getriebeeingriff an den Motor. Indiziertes Moment.";
CM_ SG_ 130 GE_MMom_Status "Qualifiziert GE_MMom_Soll";
CM_ SG_ 130 GE_Freig_Mmom_Soll "Entfall des Signals in v698, da nicht mehr benötigt";
CM_ SG_ 130 GE_Zeit_MZP "Zeit des Momenten-Zeit-Paares (ehemals Getriebe_3_Momente)";
CM_ SG_ 130 GE_Mom_MZP "Achtung:
Einheitenloser CAN-Wert.
Faktor in MO_Faktor_Momente in Motor_Code_01 beachten!

Moment des Momenten-Zeit-Paares (ehemals Getriebe_3_Momente)";
CM_ SG_ 130 GE_Mom_Ident "Momenten Identifier (ehemals Getriebe_3_Momente)";
CM_ SG_ 131 Getriebe_02_CHK "Bildung der CHK:

XOR Byte2 XOR Byte 3 ... XOR Byte n  XOR CHK-Endwert  = CHK

Ab B8 ist CHK-Endwert abhängig vom CAN-ID: CHK-Endwert = MSB XOR LSB
MSB: High-Byte des Identifiers der CAN-Botschaft
LSB: Low-Byte des Identifiers der CAN-Botschaft";
CM_ SG_ 131 GE_Mom_Begr_Gradient "Drehmomenten-Gradientenbegrenzung für Teillastanfahrten mit dem VL30-Getriebe und Standabkopplung beim 5HPx, 6HPx. Wird auch während Schaltungen verwendet.";
CM_ SG_ 131 GE_Anheb_Solldrehz_Leerlauf "Wunschvorgabewert des Getriebes an den Motor, die Leerlaufdrehzahl auf den gesendeten Betrag x anzuheben (Vorgabe des Absolutwertes)";
CM_ SG_ 131 GE_Vorsteuermoment "Achtung:
Einheitenloser CAN-Wert.
Faktor in MO_Faktor_Momente in Motor_Code_01 beachten!

Vorsteuermoment für Leerlaufdrehzahlregler im Motor";
CM_ SG_ 131 GE_Drehzahlmesser_Daempfung "Beim DQ-Getriebe kann die Anzeigedämpfung des Drehzahlmessers beim Schalten geändert werden.

Entfall zur nächsten K-Matrix. Neu: GE_Anzeigedrehz in Getriebe_05";
CM_ SG_ 131 GE_Schubabschalt_Unt "Wenn die Schubabschalt-Unterstützung aktiv ist, wird vom VL300-Steuergerät sichergestellt, daß die Kupplung nicht schlagartig geöffnet wird.";
CM_ SG_ 131 GE_Freigabe_Synchro "Freigabe Synchronisations-Wunschdrehzahl und Synchronisationszeit";
CM_ SG_ 258 Getriebe_03_CHK "Bildung der CHK:

XOR Byte2 XOR Byte 3 ... XOR Byte n  XOR CHK-Endwert  = CHK

Ab B8 ist CHK-Endwert abhängig vom CAN-ID: CHK-Endwert = MSB XOR LSB
MSB: High-Byte des Identifiers der CAN-Botschaft
LSB: Low-Byte des Identifiers der CAN-Botschaft";
CM_ SG_ 258 GE_Freig_Langfr_Schutzmom "Freigabeflag für das langfristige Schutzmoment";
CM_ SG_ 258 GE_Uefkt "Übertragungsfunktion vom Getriebe

Wandlerverstärkung x Drehzahlverhältnis

Beim Kupplungsautomat (VL, DL) ist der Faktor 1";
CM_ SG_ 258 GE_Zielgang "Zielgang, wenn Schaltung aktiv ist. Ansonsten wird der aktuell eingelegte Gang ausgegeben.

0x9 - 0xA = tbd
0xD = tbd.

Weiter sind Empfängerseitig mit nächstem SW-Release zu bedienen:
0xB = Gang 8
0xC = Gang 9
Der Sender stellt noch nicht um.
";
CM_ SG_ 258 GE_Langfr_Schutzmom "Achtung:
Einheitenloser CAN-Wert.
Faktor in MO_Faktor_Momente in Motor_Code_01 beachten!

geführter Getriebeschutz";
CM_ SG_ 258 GE_reserv_Waehlhebel "reserviert falls künftig Erweiterung von GE_Waehlhebel nötig";
CM_ SG_ 258 GE_Waehlhebel "0x2 - 0x4 = tbd.
0xA - 0xD = tbd.";
CM_ SG_ 258 GE_Eingangsdrehz "Wird gesendet, um das Lastschlagverhalten bei Schaltvorgängen zu verbessern.";
CM_ SG_ 258 GE_Codierung_MSG "Wenn das Getriebe bei der Codierplausibilisierung zum Motor einen Fehler erkennt wird das Bit auf 0x1 gesetzt. ESP wirft daraufhin die Funktion ab.";
CM_ SG_ 1089 GE_Index_Fahrwid "Auf % Steigung am Berg normiert";
CM_ SG_ 1089 GE_OBD_Status "Dieses Bit steuert die MIL-Lampe an (Motorsteuergerät reicht diese Info an Kombi weiter).";
CM_ SG_ 1089 GE_LFR_Adaption "Da das VL30-Getriebe im Stillstand unter gewissen Randbedingungen wechselnde Kupplungsmomente einstellt (z.B. Hillholder), sollte die Leerlaufauffüllungsadaption im Motorsteuergerät für diese Zustände gesperrt werden.

";
CM_ SG_ 1089 GE_Grenzkriechmoment "Achtung:
Einheitenloser CAN-Wert.
Faktor in MO_Faktor_Momente in Motor_Code_01 beachten!

Es gilt: Signalspec GE_Grenzkriechmoment v1.0

Maximales Kupplungs-/Wandlermoment im Leerlauf. Darin sind motorische Umwelteinflüsse enthalten. CAN-Wert = 0,5 ";
CM_ SG_ 1089 GE_Charisma_FahrPr "Aktuelles Fahrprogramm des Charisma-Teilnehmers";
CM_ SG_ 1089 GE_Charisma_Status "Charisma Systemstatus des Charisma-Teilnehmers";
CM_ SG_ 1089 GE_Charisma_Umschaltung "Erkennung  Umschaltaufforderung des Charisma-Teilnehmers";
CM_ SG_ 1089 GE_Verlustmoment "Achtung:
Einheitenloser CAN-Wert.
Faktor in MO_Faktor_Momente in Motor_Code_01 beachten!

Es gilt: Signalspec GE_Verlustmoment v1.0

Verlustmoment inklusive Pumpenaufnahmemoment (Rechenwert aus CAN-Werten und Kennfeldern ermittelt). Inhalt wird alle";
CM_ SG_ 1089 GE_amax_moeglich "Fzg mit Stufenautomat: Maximale mögliche Beschleunigung bei der jetzigen Übersetzung (Übertragungsfunktion), bezogen auf Begrenzungsmoment, Fahrzeugmasse, Fahrwiderstandsindex und Motor Stressfaktor

Fzg mit stufenlosem Getriebe: Maximale mögliche Besch";
CM_ SG_ 1089 GE_Sumpftemperatur "Getriebesumpftemperatur wird über den Temperatursensor auf der Getriebeplatine ermittelt. Die absolute Sumpftemperatur wird vom Motor empfangen, um entsprechende Kühlleistung für das Getriebe einzustellen.";
CM_ SG_ 960 Klemmen_Status_01_CHK "XOR-Checksumme
Bildung der CHK: XOR Byte2 XOR Byte 3 ... XOR Byte n  XOR CHK-Endwert  = CHK

Ab B8 ist CHK-Endwert abhängig vom CAN-ID: CHK-Endwert = MSB XOR LSB
MSB: High-Byte des Identifiers der CAN-Botschaft
LSB: Low-Byte des Identifiers der CAN-B";
CM_ SG_ 960 Klemmen_Status_01_BZ "4bit Botschaftszaehler; wird in jeder Sendebotschaft inkrementiert";
CM_ SG_ 960 ZAS_Kl_S "Klemme S: S-Kontakt (Schluessel steckt)
";
CM_ SG_ 960 ZAS_Kl_15 "Klemme 15: Zuendung (SW-Kl.15)
";
CM_ SG_ 960 ZAS_Kl_X "Klemme 75
";
CM_ SG_ 960 ZAS_Kl_50 "Klemme 50: Startwunsch Fahrer
";
CM_ SG_ 959 KL_Drehz_Anh "Drehzahlanhebung vom Motor angefordert

";
CM_ SG_ 959 KL_Vorwarn_Komp_ein "Vorwarnung Kompressor ein; 140ms vorher; Information für Motor zum Aufbau Momentenreserve";
CM_ SG_ 959 KL_Handshake_BEM "Handshake Klima / BEM (Heizleistungsänderung)
";
CM_ SG_ 959 KL_Komp_Moment_alt "Veraltet-Bit für Kompressor-Moment
";
CM_ SG_ 959 KL_Vorwarn_HHS_ein "Vorwarnung Heckscheibenheizung ein; Information für Motor zum Aufbau Momentenreserve";
CM_ SG_ 959 KL_Vorwarn_HFS_ein "Vorwarnung Frontscheibenheizung ein (Info für Motor zum Aufbau Momentenreserve), aktuell keine HFS für B8 geplant
";
CM_ SG_ 959 KL_Vorwarn_Zuheizer_ein "Vorwarnung Zuheizerbetrieb
";
CM_ SG_ 959 KL_KD_Fehler "Status Kundendienstfehlerspeichereinträge

";
CM_ SG_ 959 KL_Last_Kompr "Verlustmoment der Klimaanlage

";
CM_ SG_ 959 KL_Leistung_Hzg_Soll "Ansteuerung intelligentes 1600 W PTC oder Schnellheizung
";
CM_ SG_ 959 KL_Anf_KL "Anforderung Kühlerlüfter der Klimaanlage in Prozent

";
CM_ SG_ 959 KL_4_Zonen "Vorhalt für D4:
Information, ob 4-Zonen-Klimaanlage verbaut

";
CM_ SG_ 959 KL_AC_Schalter "AC Schalter
";
CM_ SG_ 959 KL_Zustand "Betrieb Klimaanlage
";
CM_ SG_ 959 KL_el_Zuheizer_Stufe "Vorgabe für Motorsteuergeraet PTC-Stufe; im B8 nur Stufe 0...3
";
BA_DEF_ BO_  "GenMsgAutoGenDsp" ENUM  "No","Yes";
BA_DEF_ BO_  "GenMsgAutoGenSnd" ENUM  "No","Yes";
BA_DEF_ BO_  "GenMsgCycleTime" INT 0 65535;
BA_DEF_ BO_  "GenMsgCycleTimeFast" INT 0 65535;
BA_DEF_ BO_  "GenMsgDelayTime" INT 0 100000;
BA_DEF_ BO_  "GenMsgILSupport" ENUM  "No","Yes";
BA_DEF_ BO_  "GenMsgNrOfRepetition" INT 0 100;
BA_DEF_ BO_  "GenMsgSendType" ENUM  "cyclicX","spontanX","cyclicIfActiveX","spontanWithDelay","cyclicAndSpontanX","cyclicAndSpontanWithDelay","spontanWithRepetition","cyclicIfActiveAndSpontanWD","cyclicIfActiveFast","cyclicWithRepeatOnDemand";
BA_DEF_ BO_  "GenMsgStartDelayTime" INT 0 100000;
BA_DEF_ BO_  "NmMessage" ENUM  "No","Yes";
BA_DEF_ BO_  "NmhMessage" ENUM  "No","Yes";
BA_DEF_ BO_  "NWM-Botschaft" ENUM  "No","Yes";
BA_DEF_ BO_  "VAGTP20_API" HEX 0 255;
BA_DEF_ BO_  "VAGTP20_DynConnection" ENUM  "No","Yes";
BA_DEF_ BO_  "VAGTP20_DynSetup" ENUM  "No","Yes";
BA_DEF_ BO_  "VAGTP20_StatConnection" ENUM  "No","Yes";
BA_DEF_ BO_  "Timeoutzeit" INT 0 1000000;
BA_DEF_ BO_  "akt_Dateninh_NM_Betr" ENUM  "No","Yes";
BA_DEF_ SG_  "GenSigAltSetting" STRING ;
BA_DEF_ SG_  "GenSigAssignSetting" STRING ;
BA_DEF_ SG_  "GenSigAutoGenDsp" ENUM  "No","Yes";
BA_DEF_ SG_  "GenSigAutoGenSnd" ENUM  "No","Yes";
BA_DEF_ SG_  "GenSigConditionalSend" STRING ;
BA_DEF_ SG_  "GenSigEnvVarType" ENUM  "int","float","undef";
BA_DEF_ SG_  "GenSigEVName" STRING ;
BA_DEF_ SG_  "GenSigInactiveValue" INT -2147483648 2147483647;
BA_DEF_ SG_  "GenSigPostIfSetting" STRING ;
BA_DEF_ SG_  "GenSigPostSetting" STRING ;
BA_DEF_ SG_  "GenSigPreIfSetting" STRING ;
BA_DEF_ SG_  "GenSigPreSetting" STRING ;
BA_DEF_ SG_  "GenSigSendType" ENUM  "Cyclic","OnWrite","OnWriteWithRepetition","OnChange","OnChangeWithRepetition","IfActive","IfActiveWithRepetition","NoSigSendType";
BA_DEF_ SG_  "GenSigStartValue" INT -2147483648 2147483647;
BA_DEF_ SG_  "NWM-WakeupAllowed" ENUM  "No","Yes";
BA_DEF_ SG_  "NMH-WakeupAllowed" ENUM  "No","Yes";
BA_DEF_ SG_  "GenSigTimeoutMsg_Motor_EDC17_003" HEX 0 2047;
BA_DEF_ SG_  "GenSigTimeoutMsg_Motor_EDC17_004" HEX 0 2047;
BA_DEF_ SG_  "GenSigTimeoutMsg_Motor_MED17_B8" HEX 0 2047;
BA_DEF_ SG_  "GenSigTimeoutMsg_Motor_MED9_B8" HEX 0 2047;
BA_DEF_ SG_  "GenSigTimeoutMsg_Motor_SIMOS8_B8" HEX 0 2047;
BA_DEF_ SG_  "GenSigTimeoutMsg_Daempfer_B8" HEX 0 2047;
BA_DEF_ SG_  "GenSigTimeoutMsg_Gateway_B8" HEX 0 2047;
BA_DEF_ SG_  "GenSigTimeoutMsg_Getriebe_AL6000" HEX 0 2047;
BA_DEF_ SG_  "GenSigTimeoutMsg_Getriebe_DL5001" HEX 0 2047;
BA_DEF_ SG_  "GenSigTimeoutMsg_Getriebe_VL3002" HEX 0 2047;
BA_DEF_ SG_  "GenSigTimeoutMsg_AFS_B8" HEX 0 2047;
BA_DEF_ SG_  "GenSigTimeoutMsg_Motor_Slave_B8" HEX 0 2047;
BA_DEF_ SG_  "GenSigTimeoutMsg_Airbag_B8" HEX 0 2047;
BA_DEF_ SG_  "GenSigTimeoutMsg_LWR_B8" HEX 0 2047;
BA_DEF_ SG_  "GenSigFuncType" ENUM  "NoFunction","MsgCounter","CRC-8","XOR","XOR-2","DatedBit","SW-Kl15","CHK","Constant","Protocol";
BA_DEF_ SG_  "GenSigSwitchedByIgnition" ENUM  "No","Yes";
BA_DEF_ SG_  "Fehlerwert" HEX 0 2147483647;
BA_DEF_ SG_  "GenSigMissingSourceValue" HEX 0 2147483647;
BA_DEF_ SG_  "SystemSignalLongSymbol" STRING ;
BA_DEF_DEF_  "GenMsgAutoGenDsp" "Yes";
BA_DEF_DEF_  "GenMsgAutoGenSnd" "Yes";
BA_DEF_DEF_  "GenMsgCycleTime" 0;
BA_DEF_DEF_  "GenMsgCycleTimeFast" 0;
BA_DEF_DEF_  "GenMsgDelayTime" 0;
BA_DEF_DEF_  "GenMsgILSupport" "";
BA_DEF_DEF_  "GenMsgNrOfRepetition" 0;
BA_DEF_DEF_  "GenMsgSendType" "cyclicX";
BA_DEF_DEF_  "GenMsgStartDelayTime" 0;
BA_DEF_DEF_  "NmMessage" "No";
BA_DEF_DEF_  "NmhMessage" "No";
BA_DEF_DEF_  "NWM-Botschaft" "No";
BA_DEF_DEF_  "VAGTP20_API" 0;
BA_DEF_DEF_  "VAGTP20_DynConnection" "No";
BA_DEF_DEF_  "VAGTP20_DynSetup" "No";
BA_DEF_DEF_  "VAGTP20_StatConnection" "No";
BA_DEF_DEF_  "Timeoutzeit" 0;
BA_DEF_DEF_  "akt_Dateninh_NM_Betr" "";
BA_DEF_DEF_  "GenSigAltSetting" "";
BA_DEF_DEF_  "GenSigAssignSetting" "";
BA_DEF_DEF_  "GenSigAutoGenDsp" "";
BA_DEF_DEF_  "GenSigAutoGenSnd" "";
BA_DEF_DEF_  "GenSigConditionalSend" "";
BA_DEF_DEF_  "GenSigEnvVarType" "undef";
BA_DEF_DEF_  "GenSigEVName" "";
BA_DEF_DEF_  "GenSigInactiveValue" 0;
BA_DEF_DEF_  "GenSigPostIfSetting" "";
BA_DEF_DEF_  "GenSigPostSetting" "";
BA_DEF_DEF_  "GenSigPreIfSetting" "";
BA_DEF_DEF_  "GenSigPreSetting" "";
BA_DEF_DEF_  "GenSigSendType" "Cyclic";
BA_DEF_DEF_  "GenSigStartValue" 0;
BA_DEF_DEF_  "NWM-WakeupAllowed" "";
BA_DEF_DEF_  "NMH-WakeupAllowed" "";
BA_DEF_DEF_  "GenSigTimeoutMsg_Motor_EDC17_003" 0;
BA_DEF_DEF_  "GenSigTimeoutMsg_Motor_EDC17_004" 0;
BA_DEF_DEF_  "GenSigTimeoutMsg_Motor_MED17_B8" 0;
BA_DEF_DEF_  "GenSigTimeoutMsg_Motor_MED9_B8" 0;
BA_DEF_DEF_  "GenSigTimeoutMsg_Motor_SIMOS8_B8" 0;
BA_DEF_DEF_  "GenSigTimeoutMsg_Daempfer_B8" 0;
BA_DEF_DEF_  "GenSigTimeoutMsg_Gateway_B8" 0;
BA_DEF_DEF_  "GenSigTimeoutMsg_Getriebe_AL6000" 0;
BA_DEF_DEF_  "GenSigTimeoutMsg_Getriebe_DL5001" 0;
BA_DEF_DEF_  "GenSigTimeoutMsg_Getriebe_VL3002" 0;
BA_DEF_DEF_  "GenSigTimeoutMsg_AFS_B8" 0;
BA_DEF_DEF_  "GenSigTimeoutMsg_Motor_Slave_B8" 0;
BA_DEF_DEF_  "GenSigTimeoutMsg_Airbag_B8" 0;
BA_DEF_DEF_  "GenSigTimeoutMsg_LWR_B8" 0;
BA_DEF_DEF_  "GenSigFuncType" "";
BA_DEF_DEF_  "GenSigSwitchedByIgnition" "";
BA_DEF_DEF_  "Fehlerwert" 0;
BA_DEF_DEF_  "GenSigMissingSourceValue" 0;
BA_DEF_DEF_  "SystemSignalLongSymbol" "";
BA_ "GenMsgCycleTime" BO_ 262 20;
BA_ "GenMsgILSupport" BO_ 262 1;
BA_ "akt_Dateninh_NM_Betr" BO_ 262 1;
BA_ "GenMsgCycleTime" BO_ 1721 2000;
BA_ "GenMsgILSupport" BO_ 1721 1;
BA_ "akt_Dateninh_NM_Betr" BO_ 1721 0;
BA_ "GenMsgCycleTime" BO_ 264 25;
BA_ "GenMsgILSupport" BO_ 264 1;
BA_ "akt_Dateninh_NM_Betr" BO_ 264 1;
BA_ "GenMsgCycleTime" BO_ 924 100;
BA_ "GenMsgILSupport" BO_ 924 1;
BA_ "akt_Dateninh_NM_Betr" BO_ 924 1;
BA_ "GenMsgCycleTime" BO_ 1604 500;
BA_ "GenMsgILSupport" BO_ 1604 1;
BA_ "GenMsgSendType" BO_ 1604 5;
BA_ "akt_Dateninh_NM_Betr" BO_ 1604 1;
BA_ "GenMsgCycleTime" BO_ 1138 100;
BA_ "GenMsgILSupport" BO_ 1138 1;
BA_ "akt_Dateninh_NM_Betr" BO_ 1138 1;
BA_ "GenMsgCycleTime" BO_ 130 10;
BA_ "GenMsgILSupport" BO_ 130 1;
BA_ "akt_Dateninh_NM_Betr" BO_ 130 1;
BA_ "GenMsgCycleTime" BO_ 131 10;
BA_ "GenMsgILSupport" BO_ 131 1;
BA_ "akt_Dateninh_NM_Betr" BO_ 131 1;
BA_ "GenMsgCycleTime" BO_ 258 20;
BA_ "GenMsgILSupport" BO_ 258 1;
BA_ "akt_Dateninh_NM_Betr" BO_ 258 1;
BA_ "GenMsgCycleTime" BO_ 1089 100;
BA_ "GenMsgILSupport" BO_ 1089 1;
BA_ "akt_Dateninh_NM_Betr" BO_ 1089 1;
BA_ "GenMsgILSupport" BO_ 1813 0;
BA_ "GenMsgSendType" BO_ 1813 2;
BA_ "akt_Dateninh_NM_Betr" BO_ 1813 1;
BA_ "GenMsgILSupport" BO_ 1919 0;
BA_ "GenMsgSendType" BO_ 1919 2;
BA_ "akt_Dateninh_NM_Betr" BO_ 1919 1;
BA_ "GenMsgILSupport" BO_ 2022 0;
BA_ "GenMsgSendType" BO_ 2022 2;
BA_ "akt_Dateninh_NM_Betr" BO_ 2022 1;
BA_ "GenMsgILSupport" BO_ 2030 0;
BA_ "GenMsgSendType" BO_ 2030 2;
BA_ "akt_Dateninh_NM_Betr" BO_ 2030 1;
BA_ "GenMsgILSupport" BO_ 1792 0;
BA_ "GenMsgSendType" BO_ 1792 2;
BA_ "akt_Dateninh_NM_Betr" BO_ 1792 1;
BA_ "GenMsgILSupport" BO_ 2015 0;
BA_ "GenMsgSendType" BO_ 2015 2;
BA_ "akt_Dateninh_NM_Betr" BO_ 2015 1;
BA_ "GenMsgILSupport" BO_ 2017 0;
BA_ "GenMsgSendType" BO_ 2017 2;
BA_ "akt_Dateninh_NM_Betr" BO_ 2017 1;
BA_ "GenMsgILSupport" BO_ 2025 0;
BA_ "GenMsgSendType" BO_ 2025 2;
BA_ "akt_Dateninh_NM_Betr" BO_ 2025 1;
BA_ "GenMsgILSupport" BO_ 2021 0;
BA_ "GenMsgSendType" BO_ 2021 2;
BA_ "akt_Dateninh_NM_Betr" BO_ 2021 1;
BA_ "GenMsgILSupport" BO_ 2029 0;
BA_ "GenMsgSendType" BO_ 2029 2;
BA_ "akt_Dateninh_NM_Betr" BO_ 2029 1;
BA_ "GenMsgILSupport" BO_ 2016 0;
BA_ "GenMsgSendType" BO_ 2016 2;
BA_ "akt_Dateninh_NM_Betr" BO_ 2016 1;
BA_ "GenMsgILSupport" BO_ 2024 0;
BA_ "GenMsgSendType" BO_ 2024 2;
BA_ "akt_Dateninh_NM_Betr" BO_ 2024 1;
BA_ "GenMsgILSupport" BO_ 2018 0;
BA_ "GenMsgSendType" BO_ 2018 2;
BA_ "akt_Dateninh_NM_Betr" BO_ 2018 1;
BA_ "GenMsgILSupport" BO_ 2026 0;
BA_ "GenMsgSendType" BO_ 2026 2;
BA_ "akt_Dateninh_NM_Betr" BO_ 2026 1;
BA_ "GenMsgILSupport" BO_ 2019 0;
BA_ "GenMsgSendType" BO_ 2019 2;
BA_ "akt_Dateninh_NM_Betr" BO_ 2019 1;
BA_ "GenMsgILSupport" BO_ 2027 0;
BA_ "GenMsgSendType" BO_ 2027 2;
BA_ "akt_Dateninh_NM_Betr" BO_ 2027 1;
BA_ "GenMsgILSupport" BO_ 2023 0;
BA_ "GenMsgSendType" BO_ 2023 2;
BA_ "akt_Dateninh_NM_Betr" BO_ 2023 1;
BA_ "GenMsgILSupport" BO_ 2031 0;
BA_ "GenMsgSendType" BO_ 2031 2;
BA_ "akt_Dateninh_NM_Betr" BO_ 2031 1;
BA_ "GenMsgILSupport" BO_ 2020 0;
BA_ "GenMsgSendType" BO_ 2020 2;
BA_ "akt_Dateninh_NM_Betr" BO_ 2020 1;
BA_ "GenMsgILSupport" BO_ 2028 0;
BA_ "GenMsgSendType" BO_ 2028 2;
BA_ "akt_Dateninh_NM_Betr" BO_ 2028 1;
BA_ "GenMsgCycleTime" BO_ 960 100;
BA_ "GenMsgDelayTime" BO_ 960 10;
BA_ "GenMsgILSupport" BO_ 960 1;
BA_ "GenMsgSendType" BO_ 960 5;
BA_ "akt_Dateninh_NM_Betr" BO_ 960 1;
BA_ "GenMsgCycleTime" BO_ 959 100;
BA_ "GenMsgILSupport" BO_ 959 1;
BA_ "akt_Dateninh_NM_Betr" BO_ 959 1;
BA_ "GenSigAutoGenDsp" SG_ 262 ESP_05_CHK 1;
BA_ "GenSigAutoGenSnd" SG_ 262 ESP_05_CHK 1;
BA_ "GenSigEnvVarType" SG_ 262 ESP_05_CHK 0;
BA_ "GenSigSendType" SG_ 262 ESP_05_CHK 7;
BA_ "NWM-WakeupAllowed" SG_ 262 ESP_05_CHK 0;
BA_ "NMH-WakeupAllowed" SG_ 262 ESP_05_CHK 0;
BA_ "GenSigTimeoutMsg_Daempfer_B8" SG_ 262 ESP_05_CHK 262;
BA_ "GenSigTimeoutMsg_Getriebe_AL6000" SG_ 262 ESP_05_CHK 262;
BA_ "GenSigTimeoutMsg_Getriebe_DL5001" SG_ 262 ESP_05_CHK 262;
BA_ "GenSigTimeoutMsg_Getriebe_VL3002" SG_ 262 ESP_05_CHK 262;
BA_ "GenSigTimeoutMsg_Motor_EDC17_003" SG_ 262 ESP_05_CHK 262;
BA_ "GenSigTimeoutMsg_Motor_EDC17_004" SG_ 262 ESP_05_CHK 262;
BA_ "GenSigTimeoutMsg_Motor_MED17_B8" SG_ 262 ESP_05_CHK 262;
BA_ "GenSigTimeoutMsg_Motor_MED9_B8" SG_ 262 ESP_05_CHK 262;
BA_ "GenSigTimeoutMsg_Motor_SIMOS8_B8" SG_ 262 ESP_05_CHK 262;
BA_ "GenSigAutoGenDsp" SG_ 262 ESP_05_BZ 1;
BA_ "GenSigAutoGenSnd" SG_ 262 ESP_05_BZ 1;
BA_ "GenSigEnvVarType" SG_ 262 ESP_05_BZ 0;
BA_ "GenSigSendType" SG_ 262 ESP_05_BZ 7;
BA_ "NWM-WakeupAllowed" SG_ 262 ESP_05_BZ 0;
BA_ "NMH-WakeupAllowed" SG_ 262 ESP_05_BZ 0;
BA_ "GenSigTimeoutMsg_Daempfer_B8" SG_ 262 ESP_05_BZ 262;
BA_ "GenSigTimeoutMsg_Getriebe_AL6000" SG_ 262 ESP_05_BZ 262;
BA_ "GenSigTimeoutMsg_Getriebe_DL5001" SG_ 262 ESP_05_BZ 262;
BA_ "GenSigTimeoutMsg_Getriebe_VL3002" SG_ 262 ESP_05_BZ 262;
BA_ "GenSigTimeoutMsg_Motor_EDC17_003" SG_ 262 ESP_05_BZ 262;
BA_ "GenSigTimeoutMsg_Motor_EDC17_004" SG_ 262 ESP_05_BZ 262;
BA_ "GenSigTimeoutMsg_Motor_MED17_B8" SG_ 262 ESP_05_BZ 262;
BA_ "GenSigTimeoutMsg_Motor_MED9_B8" SG_ 262 ESP_05_BZ 262;
BA_ "GenSigTimeoutMsg_Motor_SIMOS8_B8" SG_ 262 ESP_05_BZ 262;
BA_ "GenSigAutoGenDsp" SG_ 262 ESP_QBit_Bremsdruck 1;
BA_ "GenSigAutoGenSnd" SG_ 262 ESP_QBit_Bremsdruck 1;
BA_ "GenSigEnvVarType" SG_ 262 ESP_QBit_Bremsdruck 0;
BA_ "GenSigSendType" SG_ 262 ESP_QBit_Bremsdruck 7;
BA_ "GenSigStartValue" SG_ 262 ESP_QBit_Bremsdruck 1;
BA_ "NWM-WakeupAllowed" SG_ 262 ESP_QBit_Bremsdruck 0;
BA_ "NMH-WakeupAllowed" SG_ 262 ESP_QBit_Bremsdruck 0;
BA_ "GenSigTimeoutMsg_Daempfer_B8" SG_ 262 ESP_QBit_Bremsdruck 262;
BA_ "GenSigTimeoutMsg_Getriebe_AL6000" SG_ 262 ESP_QBit_Bremsdruck 262;
BA_ "GenSigTimeoutMsg_Getriebe_DL5001" SG_ 262 ESP_QBit_Bremsdruck 262;
BA_ "GenSigTimeoutMsg_Motor_EDC17_003" SG_ 262 ESP_QBit_Bremsdruck 262;
BA_ "GenSigTimeoutMsg_Motor_EDC17_004" SG_ 262 ESP_QBit_Bremsdruck 262;
BA_ "GenSigTimeoutMsg_Motor_MED17_B8" SG_ 262 ESP_QBit_Bremsdruck 262;
BA_ "GenSigTimeoutMsg_Motor_MED9_B8" SG_ 262 ESP_QBit_Bremsdruck 262;
BA_ "GenSigTimeoutMsg_Motor_SIMOS8_B8" SG_ 262 ESP_QBit_Bremsdruck 262;
BA_ "GenSigAutoGenDsp" SG_ 262 ESP_QBit_Fahrer_bremst 1;
BA_ "GenSigAutoGenSnd" SG_ 262 ESP_QBit_Fahrer_bremst 1;
BA_ "GenSigSendType" SG_ 262 ESP_QBit_Fahrer_bremst 7;
BA_ "GenSigStartValue" SG_ 262 ESP_QBit_Fahrer_bremst 1;
BA_ "NWM-WakeupAllowed" SG_ 262 ESP_QBit_Fahrer_bremst 0;
BA_ "NMH-WakeupAllowed" SG_ 262 ESP_QBit_Fahrer_bremst 0;
BA_ "GenSigTimeoutMsg_Motor_EDC17_003" SG_ 262 ESP_QBit_Fahrer_bremst 262;
BA_ "GenSigTimeoutMsg_Motor_EDC17_004" SG_ 262 ESP_QBit_Fahrer_bremst 262;
BA_ "GenSigTimeoutMsg_Motor_MED17_B8" SG_ 262 ESP_QBit_Fahrer_bremst 262;
BA_ "GenSigTimeoutMsg_Motor_MED9_B8" SG_ 262 ESP_QBit_Fahrer_bremst 262;
BA_ "GenSigTimeoutMsg_Motor_SIMOS8_B8" SG_ 262 ESP_QBit_Fahrer_bremst 262;
BA_ "GenSigAutoGenDsp" SG_ 262 ESP_Schwelle_Unterdruck 1;
BA_ "GenSigAutoGenSnd" SG_ 262 ESP_Schwelle_Unterdruck 1;
BA_ "GenSigSendType" SG_ 262 ESP_Schwelle_Unterdruck 7;
BA_ "NWM-WakeupAllowed" SG_ 262 ESP_Schwelle_Unterdruck 0;
BA_ "NMH-WakeupAllowed" SG_ 262 ESP_Schwelle_Unterdruck 0;
BA_ "GenSigAutoGenDsp" SG_ 262 ESP_Bremsdruck 1;
BA_ "GenSigAutoGenSnd" SG_ 262 ESP_Bremsdruck 1;
BA_ "GenSigEnvVarType" SG_ 262 ESP_Bremsdruck 1;
BA_ "GenSigSendType" SG_ 262 ESP_Bremsdruck 7;
BA_ "GenSigStartValue" SG_ 262 ESP_Bremsdruck 100;
BA_ "NWM-WakeupAllowed" SG_ 262 ESP_Bremsdruck 0;
BA_ "NMH-WakeupAllowed" SG_ 262 ESP_Bremsdruck 0;
BA_ "GenSigTimeoutMsg_Daempfer_B8" SG_ 262 ESP_Bremsdruck 262;
BA_ "GenSigTimeoutMsg_Getriebe_AL6000" SG_ 262 ESP_Bremsdruck 262;
BA_ "GenSigTimeoutMsg_Getriebe_DL5001" SG_ 262 ESP_Bremsdruck 262;
BA_ "GenSigTimeoutMsg_Motor_EDC17_003" SG_ 262 ESP_Bremsdruck 262;
BA_ "GenSigTimeoutMsg_Motor_EDC17_004" SG_ 262 ESP_Bremsdruck 262;
BA_ "GenSigTimeoutMsg_Motor_MED17_B8" SG_ 262 ESP_Bremsdruck 262;
BA_ "GenSigTimeoutMsg_Motor_MED9_B8" SG_ 262 ESP_Bremsdruck 262;
BA_ "GenSigTimeoutMsg_Motor_SIMOS8_B8" SG_ 262 ESP_Bremsdruck 262;
BA_ "GenSigAutoGenDsp" SG_ 262 ESP_Fahrer_bremst 1;
BA_ "GenSigAutoGenSnd" SG_ 262 ESP_Fahrer_bremst 1;
BA_ "GenSigEnvVarType" SG_ 262 ESP_Fahrer_bremst 0;
BA_ "GenSigSendType" SG_ 262 ESP_Fahrer_bremst 7;
BA_ "NWM-WakeupAllowed" SG_ 262 ESP_Fahrer_bremst 0;
BA_ "NMH-WakeupAllowed" SG_ 262 ESP_Fahrer_bremst 0;
BA_ "GenSigTimeoutMsg_Motor_EDC17_003" SG_ 262 ESP_Fahrer_bremst 262;
BA_ "GenSigTimeoutMsg_Motor_EDC17_004" SG_ 262 ESP_Fahrer_bremst 262;
BA_ "GenSigTimeoutMsg_Motor_MED17_B8" SG_ 262 ESP_Fahrer_bremst 262;
BA_ "GenSigTimeoutMsg_Motor_MED9_B8" SG_ 262 ESP_Fahrer_bremst 262;
BA_ "GenSigTimeoutMsg_Motor_SIMOS8_B8" SG_ 262 ESP_Fahrer_bremst 262;
BA_ "GenSigAutoGenDsp" SG_ 262 ESP_Verz_TSK_aktiv 0;
BA_ "GenSigAutoGenSnd" SG_ 262 ESP_Verz_TSK_aktiv 0;
BA_ "GenSigSendType" SG_ 262 ESP_Verz_TSK_aktiv 7;
BA_ "NWM-WakeupAllowed" SG_ 262 ESP_Verz_TSK_aktiv 0;
BA_ "NMH-WakeupAllowed" SG_ 262 ESP_Verz_TSK_aktiv 0;
BA_ "GenSigTimeoutMsg_Getriebe_AL6000" SG_ 262 ESP_Verz_TSK_aktiv 262;
BA_ "GenSigTimeoutMsg_Motor_EDC17_003" SG_ 262 ESP_Verz_TSK_aktiv 262;
BA_ "GenSigTimeoutMsg_Motor_EDC17_004" SG_ 262 ESP_Verz_TSK_aktiv 262;
BA_ "GenSigTimeoutMsg_Motor_MED17_B8" SG_ 262 ESP_Verz_TSK_aktiv 262;
BA_ "GenSigTimeoutMsg_Motor_MED9_B8" SG_ 262 ESP_Verz_TSK_aktiv 262;
BA_ "GenSigTimeoutMsg_Motor_SIMOS8_B8" SG_ 262 ESP_Verz_TSK_aktiv 262;
BA_ "GenSigAutoGenDsp" SG_ 262 ESP_Lenkeingriff_ADS 1;
BA_ "GenSigAutoGenSnd" SG_ 262 ESP_Lenkeingriff_ADS 1;
BA_ "GenSigSendType" SG_ 262 ESP_Lenkeingriff_ADS 7;
BA_ "NWM-WakeupAllowed" SG_ 262 ESP_Lenkeingriff_ADS 0;
BA_ "NMH-WakeupAllowed" SG_ 262 ESP_Lenkeingriff_ADS 0;
BA_ "GenSigAutoGenDsp" SG_ 262 ESP_Konsistenz_TSK 1;
BA_ "GenSigAutoGenSnd" SG_ 262 ESP_Konsistenz_TSK 1;
BA_ "GenSigSendType" SG_ 262 ESP_Konsistenz_TSK 7;
BA_ "NWM-WakeupAllowed" SG_ 262 ESP_Konsistenz_TSK 0;
BA_ "NMH-WakeupAllowed" SG_ 262 ESP_Konsistenz_TSK 0;
BA_ "GenSigTimeoutMsg_Motor_EDC17_003" SG_ 262 ESP_Konsistenz_TSK 262;
BA_ "GenSigTimeoutMsg_Motor_EDC17_004" SG_ 262 ESP_Konsistenz_TSK 262;
BA_ "GenSigTimeoutMsg_Motor_MED17_B8" SG_ 262 ESP_Konsistenz_TSK 262;
BA_ "GenSigTimeoutMsg_Motor_MED9_B8" SG_ 262 ESP_Konsistenz_TSK 262;
BA_ "GenSigTimeoutMsg_Motor_SIMOS8_B8" SG_ 262 ESP_Konsistenz_TSK 262;
BA_ "GenSigAutoGenDsp" SG_ 262 ESP_Bremsruck_AWV2 1;
BA_ "GenSigAutoGenSnd" SG_ 262 ESP_Bremsruck_AWV2 1;
BA_ "GenSigSendType" SG_ 262 ESP_Bremsruck_AWV2 7;
BA_ "NWM-WakeupAllowed" SG_ 262 ESP_Bremsruck_AWV2 0;
BA_ "NMH-WakeupAllowed" SG_ 262 ESP_Bremsruck_AWV2 0;
BA_ "GenSigAutoGenDsp" SG_ 262 ESP_Konsistenz_AWV2 1;
BA_ "GenSigAutoGenSnd" SG_ 262 ESP_Konsistenz_AWV2 1;
BA_ "GenSigSendType" SG_ 262 ESP_Konsistenz_AWV2 7;
BA_ "NWM-WakeupAllowed" SG_ 262 ESP_Konsistenz_AWV2 0;
BA_ "NMH-WakeupAllowed" SG_ 262 ESP_Konsistenz_AWV2 0;
BA_ "GenSigAutoGenDsp" SG_ 262 ECD_Fehler 1;
BA_ "GenSigAutoGenSnd" SG_ 262 ECD_Fehler 1;
BA_ "GenSigSendType" SG_ 262 ECD_Fehler 7;
BA_ "NWM-WakeupAllowed" SG_ 262 ECD_Fehler 0;
BA_ "NMH-WakeupAllowed" SG_ 262 ECD_Fehler 0;
BA_ "GenSigTimeoutMsg_Motor_EDC17_003" SG_ 262 ECD_Fehler 262;
BA_ "GenSigTimeoutMsg_Motor_EDC17_004" SG_ 262 ECD_Fehler 262;
BA_ "GenSigTimeoutMsg_Motor_MED17_B8" SG_ 262 ECD_Fehler 262;
BA_ "GenSigTimeoutMsg_Motor_MED9_B8" SG_ 262 ECD_Fehler 262;
BA_ "GenSigTimeoutMsg_Motor_SIMOS8_B8" SG_ 262 ECD_Fehler 262;
BA_ "GenSigAutoGenDsp" SG_ 262 ECD_nicht_verfuegbar 1;
BA_ "GenSigAutoGenSnd" SG_ 262 ECD_nicht_verfuegbar 1;
BA_ "GenSigSendType" SG_ 262 ECD_nicht_verfuegbar 7;
BA_ "GenSigStartValue" SG_ 262 ECD_nicht_verfuegbar 1;
BA_ "NWM-WakeupAllowed" SG_ 262 ECD_nicht_verfuegbar 0;
BA_ "NMH-WakeupAllowed" SG_ 262 ECD_nicht_verfuegbar 0;
BA_ "GenSigTimeoutMsg_Motor_EDC17_003" SG_ 262 ECD_nicht_verfuegbar 262;
BA_ "GenSigTimeoutMsg_Motor_EDC17_004" SG_ 262 ECD_nicht_verfuegbar 262;
BA_ "GenSigTimeoutMsg_Motor_MED17_B8" SG_ 262 ECD_nicht_verfuegbar 262;
BA_ "GenSigTimeoutMsg_Motor_MED9_B8" SG_ 262 ECD_nicht_verfuegbar 262;
BA_ "GenSigTimeoutMsg_Motor_SIMOS8_B8" SG_ 262 ECD_nicht_verfuegbar 262;
BA_ "GenSigAutoGenDsp" SG_ 262 ESP_Status_Bremsentemp 1;
BA_ "GenSigAutoGenSnd" SG_ 262 ESP_Status_Bremsentemp 1;
BA_ "GenSigSendType" SG_ 262 ESP_Status_Bremsentemp 7;
BA_ "NWM-WakeupAllowed" SG_ 262 ESP_Status_Bremsentemp 0;
BA_ "NMH-WakeupAllowed" SG_ 262 ESP_Status_Bremsentemp 0;
BA_ "GenSigTimeoutMsg_Motor_EDC17_003" SG_ 262 ESP_Status_Bremsentemp 262;
BA_ "GenSigTimeoutMsg_Motor_EDC17_004" SG_ 262 ESP_Status_Bremsentemp 262;
BA_ "GenSigTimeoutMsg_Motor_MED17_B8" SG_ 262 ESP_Status_Bremsentemp 262;
BA_ "GenSigTimeoutMsg_Motor_MED9_B8" SG_ 262 ESP_Status_Bremsentemp 262;
BA_ "GenSigTimeoutMsg_Motor_SIMOS8_B8" SG_ 262 ESP_Status_Bremsentemp 262;
BA_ "GenSigAutoGenDsp" SG_ 262 ESP_Autohold_Standby 1;
BA_ "GenSigAutoGenSnd" SG_ 262 ESP_Autohold_Standby 1;
BA_ "GenSigSendType" SG_ 262 ESP_Autohold_Standby 7;
BA_ "NWM-WakeupAllowed" SG_ 262 ESP_Autohold_Standby 0;
BA_ "NMH-WakeupAllowed" SG_ 262 ESP_Autohold_Standby 0;
BA_ "GenSigAutoGenDsp" SG_ 262 ESP_HDC_Standby 1;
BA_ "GenSigAutoGenSnd" SG_ 262 ESP_HDC_Standby 1;
BA_ "GenSigSendType" SG_ 262 ESP_HDC_Standby 7;
BA_ "NWM-WakeupAllowed" SG_ 262 ESP_HDC_Standby 0;
BA_ "NMH-WakeupAllowed" SG_ 262 ESP_HDC_Standby 0;
BA_ "GenSigTimeoutMsg_Motor_EDC17_003" SG_ 262 ESP_HDC_Standby 262;
BA_ "GenSigTimeoutMsg_Motor_EDC17_004" SG_ 262 ESP_HDC_Standby 262;
BA_ "GenSigTimeoutMsg_Motor_MED17_B8" SG_ 262 ESP_HDC_Standby 262;
BA_ "GenSigTimeoutMsg_Motor_MED9_B8" SG_ 262 ESP_HDC_Standby 262;
BA_ "GenSigTimeoutMsg_Motor_SIMOS8_B8" SG_ 262 ESP_HDC_Standby 262;
BA_ "GenSigAutoGenDsp" SG_ 262 ESP_Eingr_HL 1;
BA_ "GenSigAutoGenSnd" SG_ 262 ESP_Eingr_HL 1;
BA_ "GenSigSendType" SG_ 262 ESP_Eingr_HL 7;
BA_ "NWM-WakeupAllowed" SG_ 262 ESP_Eingr_HL 0;
BA_ "NMH-WakeupAllowed" SG_ 262 ESP_Eingr_HL 0;
BA_ "GenSigAutoGenDsp" SG_ 262 ESP_Eingr_HR 1;
BA_ "GenSigAutoGenSnd" SG_ 262 ESP_Eingr_HR 1;
BA_ "GenSigSendType" SG_ 262 ESP_Eingr_HR 7;
BA_ "NWM-WakeupAllowed" SG_ 262 ESP_Eingr_HR 0;
BA_ "NMH-WakeupAllowed" SG_ 262 ESP_Eingr_HR 0;
BA_ "GenSigAutoGenDsp" SG_ 262 ESP_Eingr_VL 1;
BA_ "GenSigAutoGenSnd" SG_ 262 ESP_Eingr_VL 1;
BA_ "GenSigSendType" SG_ 262 ESP_Eingr_VL 7;
BA_ "NWM-WakeupAllowed" SG_ 262 ESP_Eingr_VL 0;
BA_ "NMH-WakeupAllowed" SG_ 262 ESP_Eingr_VL 0;
BA_ "GenSigAutoGenDsp" SG_ 262 ESP_Eingr_VR 1;
BA_ "GenSigAutoGenSnd" SG_ 262 ESP_Eingr_VR 1;
BA_ "GenSigSendType" SG_ 262 ESP_Eingr_VR 7;
BA_ "NWM-WakeupAllowed" SG_ 262 ESP_Eingr_VR 0;
BA_ "NMH-WakeupAllowed" SG_ 262 ESP_Eingr_VR 0;
BA_ "GenSigAutoGenDsp" SG_ 262 ESP_BKV_Unterdruck 1;
BA_ "GenSigAutoGenSnd" SG_ 262 ESP_BKV_Unterdruck 1;
BA_ "GenSigSendType" SG_ 262 ESP_BKV_Unterdruck 7;
BA_ "NWM-WakeupAllowed" SG_ 262 ESP_BKV_Unterdruck 0;
BA_ "NMH-WakeupAllowed" SG_ 262 ESP_BKV_Unterdruck 0;
BA_ "GenSigAutoGenDsp" SG_ 262 ESP_Autohold_aktiv 1;
BA_ "GenSigAutoGenSnd" SG_ 262 ESP_Autohold_aktiv 1;
BA_ "GenSigEnvVarType" SG_ 262 ESP_Autohold_aktiv 0;
BA_ "GenSigSendType" SG_ 262 ESP_Autohold_aktiv 7;
BA_ "NWM-WakeupAllowed" SG_ 262 ESP_Autohold_aktiv 0;
BA_ "NMH-WakeupAllowed" SG_ 262 ESP_Autohold_aktiv 0;
BA_ "GenSigTimeoutMsg_Getriebe_VL3002" SG_ 262 ESP_Autohold_aktiv 262;
BA_ "GenSigAutoGenDsp" SG_ 262 ESP_FStatus_Anfahrhilfe 1;
BA_ "GenSigAutoGenSnd" SG_ 262 ESP_FStatus_Anfahrhilfe 1;
BA_ "GenSigEnvVarType" SG_ 262 ESP_FStatus_Anfahrhilfe 0;
BA_ "GenSigSendType" SG_ 262 ESP_FStatus_Anfahrhilfe 7;
BA_ "NWM-WakeupAllowed" SG_ 262 ESP_FStatus_Anfahrhilfe 0;
BA_ "NMH-WakeupAllowed" SG_ 262 ESP_FStatus_Anfahrhilfe 0;
BA_ "GenSigAutoGenDsp" SG_ 262 ESP_Verz_EPB_aktiv 1;
BA_ "GenSigAutoGenSnd" SG_ 262 ESP_Verz_EPB_aktiv 1;
BA_ "GenSigEnvVarType" SG_ 262 ESP_Verz_EPB_aktiv 0;
BA_ "GenSigSendType" SG_ 262 ESP_Verz_EPB_aktiv 7;
BA_ "NWM-WakeupAllowed" SG_ 262 ESP_Verz_EPB_aktiv 0;
BA_ "NMH-WakeupAllowed" SG_ 262 ESP_Verz_EPB_aktiv 0;
BA_ "GenSigTimeoutMsg_Getriebe_AL6000" SG_ 262 ESP_Verz_EPB_aktiv 262;
BA_ "GenSigAutoGenDsp" SG_ 262 ECD_Bremslicht 1;
BA_ "GenSigAutoGenSnd" SG_ 262 ECD_Bremslicht 1;
BA_ "GenSigEnvVarType" SG_ 262 ECD_Bremslicht 0;
BA_ "GenSigSendType" SG_ 262 ECD_Bremslicht 7;
BA_ "NWM-WakeupAllowed" SG_ 262 ECD_Bremslicht 0;
BA_ "NMH-WakeupAllowed" SG_ 262 ECD_Bremslicht 0;
BA_ "GenSigTimeoutMsg_Motor_EDC17_003" SG_ 262 ECD_Bremslicht 262;
BA_ "GenSigTimeoutMsg_Motor_EDC17_004" SG_ 262 ECD_Bremslicht 262;
BA_ "GenSigTimeoutMsg_Motor_MED17_B8" SG_ 262 ECD_Bremslicht 262;
BA_ "GenSigTimeoutMsg_Motor_MED9_B8" SG_ 262 ECD_Bremslicht 262;
BA_ "GenSigTimeoutMsg_Motor_SIMOS8_B8" SG_ 262 ECD_Bremslicht 262;
BA_ "GenSigAutoGenDsp" SG_ 262 ESP_Verzoeg_EPB_verf 1;
BA_ "GenSigAutoGenSnd" SG_ 262 ESP_Verzoeg_EPB_verf 1;
BA_ "GenSigEnvVarType" SG_ 262 ESP_Verzoeg_EPB_verf 0;
BA_ "GenSigSendType" SG_ 262 ESP_Verzoeg_EPB_verf 7;
BA_ "NWM-WakeupAllowed" SG_ 262 ESP_Verzoeg_EPB_verf 0;
BA_ "NMH-WakeupAllowed" SG_ 262 ESP_Verzoeg_EPB_verf 0;
BA_ "GenSigAutoGenDsp" SG_ 262 ESP_Status_Bremsdruck 1;
BA_ "GenSigAutoGenSnd" SG_ 262 ESP_Status_Bremsdruck 1;
BA_ "GenSigEnvVarType" SG_ 262 ESP_Status_Bremsdruck 0;
BA_ "GenSigSendType" SG_ 262 ESP_Status_Bremsdruck 7;
BA_ "NWM-WakeupAllowed" SG_ 262 ESP_Status_Bremsdruck 0;
BA_ "NMH-WakeupAllowed" SG_ 262 ESP_Status_Bremsdruck 0;
BA_ "GenSigTimeoutMsg_Daempfer_B8" SG_ 262 ESP_Status_Bremsdruck 262;
BA_ "GenSigTimeoutMsg_Motor_EDC17_003" SG_ 262 ESP_Status_Bremsdruck 262;
BA_ "GenSigTimeoutMsg_Motor_EDC17_004" SG_ 262 ESP_Status_Bremsdruck 262;
BA_ "GenSigTimeoutMsg_Motor_MED17_B8" SG_ 262 ESP_Status_Bremsdruck 262;
BA_ "GenSigTimeoutMsg_Motor_MED9_B8" SG_ 262 ESP_Status_Bremsdruck 262;
BA_ "GenSigTimeoutMsg_Motor_SIMOS8_B8" SG_ 262 ESP_Status_Bremsdruck 262;
BA_ "GenSigAutoGenDsp" SG_ 262 ESP_Anforderung_EPB 1;
BA_ "GenSigAutoGenSnd" SG_ 262 ESP_Anforderung_EPB 1;
BA_ "GenSigEnvVarType" SG_ 262 ESP_Anforderung_EPB 0;
BA_ "GenSigSendType" SG_ 262 ESP_Anforderung_EPB 7;
BA_ "NWM-WakeupAllowed" SG_ 262 ESP_Anforderung_EPB 0;
BA_ "NMH-WakeupAllowed" SG_ 262 ESP_Anforderung_EPB 0;
BA_ "GenSigAutoGenDsp" SG_ 1721 ESP_Codierung_01_CHK 1;
BA_ "GenSigAutoGenSnd" SG_ 1721 ESP_Codierung_01_CHK 1;
BA_ "GenSigEnvVarType" SG_ 1721 ESP_Codierung_01_CHK 0;
BA_ "GenSigSendType" SG_ 1721 ESP_Codierung_01_CHK 7;
BA_ "NWM-WakeupAllowed" SG_ 1721 ESP_Codierung_01_CHK 0;
BA_ "NMH-WakeupAllowed" SG_ 1721 ESP_Codierung_01_CHK 0;
BA_ "GenSigTimeoutMsg_Gateway_B8" SG_ 1721 ESP_Codierung_01_CHK 1721;
BA_ "GenSigAutoGenDsp" SG_ 1721 ESP_Codierung_01_BZ 1;
BA_ "GenSigAutoGenSnd" SG_ 1721 ESP_Codierung_01_BZ 1;
BA_ "GenSigEnvVarType" SG_ 1721 ESP_Codierung_01_BZ 0;
BA_ "GenSigSendType" SG_ 1721 ESP_Codierung_01_BZ 7;
BA_ "NWM-WakeupAllowed" SG_ 1721 ESP_Codierung_01_BZ 0;
BA_ "NMH-WakeupAllowed" SG_ 1721 ESP_Codierung_01_BZ 0;
BA_ "GenSigTimeoutMsg_Gateway_B8" SG_ 1721 ESP_Codierung_01_BZ 1721;
BA_ "GenSigAutoGenDsp" SG_ 1721 ESP_Variante_Bremse 1;
BA_ "GenSigAutoGenSnd" SG_ 1721 ESP_Variante_Bremse 1;
BA_ "GenSigEnvVarType" SG_ 1721 ESP_Variante_Bremse 0;
BA_ "GenSigSendType" SG_ 1721 ESP_Variante_Bremse 7;
BA_ "NWM-WakeupAllowed" SG_ 1721 ESP_Variante_Bremse 0;
BA_ "NMH-WakeupAllowed" SG_ 1721 ESP_Variante_Bremse 0;
BA_ "GenSigTimeoutMsg_Gateway_B8" SG_ 1721 ESP_Variante_Bremse 1721;
BA_ "GenSigAutoGenDsp" SG_ 1721 ESP_Variante_Antrieb 1;
BA_ "GenSigAutoGenSnd" SG_ 1721 ESP_Variante_Antrieb 1;
BA_ "GenSigEnvVarType" SG_ 1721 ESP_Variante_Antrieb 0;
BA_ "GenSigSendType" SG_ 1721 ESP_Variante_Antrieb 7;
BA_ "NWM-WakeupAllowed" SG_ 1721 ESP_Variante_Antrieb 0;
BA_ "NMH-WakeupAllowed" SG_ 1721 ESP_Variante_Antrieb 0;
BA_ "GenSigTimeoutMsg_Gateway_B8" SG_ 1721 ESP_Variante_Antrieb 1721;
BA_ "GenSigAutoGenDsp" SG_ 264 Fahrwerk_01_CHK 1;
BA_ "GenSigAutoGenSnd" SG_ 264 Fahrwerk_01_CHK 1;
BA_ "GenSigSendType" SG_ 264 Fahrwerk_01_CHK 7;
BA_ "NWM-WakeupAllowed" SG_ 264 Fahrwerk_01_CHK 0;
BA_ "NMH-WakeupAllowed" SG_ 264 Fahrwerk_01_CHK 0;
BA_ "GenSigTimeoutMsg_Gateway_B8" SG_ 264 Fahrwerk_01_CHK 264;
BA_ "GenSigAutoGenDsp" SG_ 264 Fahrwerk_01_BZ 1;
BA_ "GenSigAutoGenSnd" SG_ 264 Fahrwerk_01_BZ 1;
BA_ "GenSigSendType" SG_ 264 Fahrwerk_01_BZ 7;
BA_ "NWM-WakeupAllowed" SG_ 264 Fahrwerk_01_BZ 0;
BA_ "NMH-WakeupAllowed" SG_ 264 Fahrwerk_01_BZ 0;
BA_ "GenSigTimeoutMsg_Gateway_B8" SG_ 264 Fahrwerk_01_BZ 264;
BA_ "GenSigAutoGenDsp" SG_ 264 FA_Hoehenwerte_kalibriert 1;
BA_ "GenSigAutoGenSnd" SG_ 264 FA_Hoehenwerte_kalibriert 1;
BA_ "GenSigSendType" SG_ 264 FA_Hoehenwerte_kalibriert 7;
BA_ "NWM-WakeupAllowed" SG_ 264 FA_Hoehenwerte_kalibriert 0;
BA_ "NMH-WakeupAllowed" SG_ 264 FA_Hoehenwerte_kalibriert 0;
BA_ "GenSigTimeoutMsg_AFS_B8" SG_ 264 FA_Hoehenwerte_kalibriert 264;
BA_ "GenSigTimeoutMsg_Gateway_B8" SG_ 264 FA_Hoehenwerte_kalibriert 264;
BA_ "GenSigTimeoutMsg_LWR_B8" SG_ 264 FA_Hoehenwerte_kalibriert 264;
BA_ "GenSigAutoGenDsp" SG_ 264 FA_Hoehenwert_VL_00 0;
BA_ "GenSigAutoGenSnd" SG_ 264 FA_Hoehenwert_VL_00 0;
BA_ "GenSigSendType" SG_ 264 FA_Hoehenwert_VL_00 7;
BA_ "GenSigStartValue" SG_ 264 FA_Hoehenwert_VL_00 254;
BA_ "NWM-WakeupAllowed" SG_ 264 FA_Hoehenwert_VL_00 0;
BA_ "NMH-WakeupAllowed" SG_ 264 FA_Hoehenwert_VL_00 0;
BA_ "GenSigTimeoutMsg_AFS_B8" SG_ 264 FA_Hoehenwert_VL_00 264;
BA_ "GenSigTimeoutMsg_Gateway_B8" SG_ 264 FA_Hoehenwert_VL_00 264;
BA_ "GenSigTimeoutMsg_LWR_B8" SG_ 264 FA_Hoehenwert_VL_00 264;
BA_ "GenSigAutoGenDsp" SG_ 264 FA_Hoehenwert_VL_01 0;
BA_ "GenSigAutoGenSnd" SG_ 264 FA_Hoehenwert_VL_01 0;
BA_ "GenSigSendType" SG_ 264 FA_Hoehenwert_VL_01 7;
BA_ "GenSigStartValue" SG_ 264 FA_Hoehenwert_VL_01 254;
BA_ "NWM-WakeupAllowed" SG_ 264 FA_Hoehenwert_VL_01 0;
BA_ "NMH-WakeupAllowed" SG_ 264 FA_Hoehenwert_VL_01 0;
BA_ "GenSigTimeoutMsg_AFS_B8" SG_ 264 FA_Hoehenwert_VL_01 264;
BA_ "GenSigTimeoutMsg_Gateway_B8" SG_ 264 FA_Hoehenwert_VL_01 264;
BA_ "GenSigTimeoutMsg_LWR_B8" SG_ 264 FA_Hoehenwert_VL_01 264;
BA_ "GenSigAutoGenDsp" SG_ 264 FA_Hoehenwert_VR_00 0;
BA_ "GenSigAutoGenSnd" SG_ 264 FA_Hoehenwert_VR_00 0;
BA_ "GenSigSendType" SG_ 264 FA_Hoehenwert_VR_00 7;
BA_ "GenSigStartValue" SG_ 264 FA_Hoehenwert_VR_00 254;
BA_ "NWM-WakeupAllowed" SG_ 264 FA_Hoehenwert_VR_00 0;
BA_ "NMH-WakeupAllowed" SG_ 264 FA_Hoehenwert_VR_00 0;
BA_ "GenSigTimeoutMsg_AFS_B8" SG_ 264 FA_Hoehenwert_VR_00 264;
BA_ "GenSigTimeoutMsg_Gateway_B8" SG_ 264 FA_Hoehenwert_VR_00 264;
BA_ "GenSigTimeoutMsg_LWR_B8" SG_ 264 FA_Hoehenwert_VR_00 264;
BA_ "GenSigAutoGenDsp" SG_ 264 FA_Hoehenwert_VR_01 0;
BA_ "GenSigAutoGenSnd" SG_ 264 FA_Hoehenwert_VR_01 0;
BA_ "GenSigSendType" SG_ 264 FA_Hoehenwert_VR_01 7;
BA_ "GenSigStartValue" SG_ 264 FA_Hoehenwert_VR_01 254;
BA_ "NWM-WakeupAllowed" SG_ 264 FA_Hoehenwert_VR_01 0;
BA_ "NMH-WakeupAllowed" SG_ 264 FA_Hoehenwert_VR_01 0;
BA_ "GenSigTimeoutMsg_AFS_B8" SG_ 264 FA_Hoehenwert_VR_01 264;
BA_ "GenSigTimeoutMsg_Gateway_B8" SG_ 264 FA_Hoehenwert_VR_01 264;
BA_ "GenSigTimeoutMsg_LWR_B8" SG_ 264 FA_Hoehenwert_VR_01 264;
BA_ "GenSigAutoGenDsp" SG_ 264 FA_Hoehenwert_HL_00 0;
BA_ "GenSigAutoGenSnd" SG_ 264 FA_Hoehenwert_HL_00 0;
BA_ "GenSigSendType" SG_ 264 FA_Hoehenwert_HL_00 7;
BA_ "GenSigStartValue" SG_ 264 FA_Hoehenwert_HL_00 254;
BA_ "NWM-WakeupAllowed" SG_ 264 FA_Hoehenwert_HL_00 0;
BA_ "NMH-WakeupAllowed" SG_ 264 FA_Hoehenwert_HL_00 0;
BA_ "GenSigTimeoutMsg_AFS_B8" SG_ 264 FA_Hoehenwert_HL_00 264;
BA_ "GenSigTimeoutMsg_Gateway_B8" SG_ 264 FA_Hoehenwert_HL_00 264;
BA_ "GenSigTimeoutMsg_LWR_B8" SG_ 264 FA_Hoehenwert_HL_00 264;
BA_ "GenSigAutoGenDsp" SG_ 264 FA_Hoehenwert_HL_01 0;
BA_ "GenSigAutoGenSnd" SG_ 264 FA_Hoehenwert_HL_01 0;
BA_ "GenSigSendType" SG_ 264 FA_Hoehenwert_HL_01 7;
BA_ "GenSigStartValue" SG_ 264 FA_Hoehenwert_HL_01 254;
BA_ "NWM-WakeupAllowed" SG_ 264 FA_Hoehenwert_HL_01 0;
BA_ "NMH-WakeupAllowed" SG_ 264 FA_Hoehenwert_HL_01 0;
BA_ "GenSigTimeoutMsg_AFS_B8" SG_ 264 FA_Hoehenwert_HL_01 264;
BA_ "GenSigTimeoutMsg_Gateway_B8" SG_ 264 FA_Hoehenwert_HL_01 264;
BA_ "GenSigTimeoutMsg_LWR_B8" SG_ 264 FA_Hoehenwert_HL_01 264;
BA_ "GenSigAutoGenDsp" SG_ 264 FA_Hoehenwert_HR_00 0;
BA_ "GenSigAutoGenSnd" SG_ 264 FA_Hoehenwert_HR_00 0;
BA_ "GenSigSendType" SG_ 264 FA_Hoehenwert_HR_00 7;
BA_ "GenSigStartValue" SG_ 264 FA_Hoehenwert_HR_00 254;
BA_ "NWM-WakeupAllowed" SG_ 264 FA_Hoehenwert_HR_00 0;
BA_ "NMH-WakeupAllowed" SG_ 264 FA_Hoehenwert_HR_00 0;
BA_ "GenSigTimeoutMsg_AFS_B8" SG_ 264 FA_Hoehenwert_HR_00 264;
BA_ "GenSigTimeoutMsg_Gateway_B8" SG_ 264 FA_Hoehenwert_HR_00 264;
BA_ "GenSigTimeoutMsg_LWR_B8" SG_ 264 FA_Hoehenwert_HR_00 264;
BA_ "GenSigAutoGenDsp" SG_ 264 FA_Hoehenwert_HR_01 0;
BA_ "GenSigAutoGenSnd" SG_ 264 FA_Hoehenwert_HR_01 0;
BA_ "GenSigSendType" SG_ 264 FA_Hoehenwert_HR_01 7;
BA_ "GenSigStartValue" SG_ 264 FA_Hoehenwert_HR_01 254;
BA_ "NWM-WakeupAllowed" SG_ 264 FA_Hoehenwert_HR_01 0;
BA_ "NMH-WakeupAllowed" SG_ 264 FA_Hoehenwert_HR_01 0;
BA_ "GenSigTimeoutMsg_AFS_B8" SG_ 264 FA_Hoehenwert_HR_01 264;
BA_ "GenSigTimeoutMsg_Gateway_B8" SG_ 264 FA_Hoehenwert_HR_01 264;
BA_ "GenSigTimeoutMsg_LWR_B8" SG_ 264 FA_Hoehenwert_HR_01 264;
BA_ "GenSigAutoGenDsp" SG_ 924 BCM1_02_alt 1;
BA_ "GenSigAutoGenSnd" SG_ 924 BCM1_02_alt 1;
BA_ "GenSigEnvVarType" SG_ 924 BCM1_02_alt 0;
BA_ "GenSigSendType" SG_ 924 BCM1_02_alt 7;
BA_ "GenSigStartValue" SG_ 924 BCM1_02_alt 1;
BA_ "NWM-WakeupAllowed" SG_ 924 BCM1_02_alt 0;
BA_ "NMH-WakeupAllowed" SG_ 924 BCM1_02_alt 0;
BA_ "GenSigTimeoutMsg_Motor_EDC17_003" SG_ 924 BCM1_02_alt 924;
BA_ "GenSigTimeoutMsg_Motor_EDC17_004" SG_ 924 BCM1_02_alt 924;
BA_ "GenSigTimeoutMsg_Motor_MED17_B8" SG_ 924 BCM1_02_alt 924;
BA_ "GenSigTimeoutMsg_Motor_MED9_B8" SG_ 924 BCM1_02_alt 924;
BA_ "GenSigTimeoutMsg_Motor_SIMOS8_B8" SG_ 924 BCM1_02_alt 924;
BA_ "GenSigAutoGenDsp" SG_ 924 Wischer_01_alt 1;
BA_ "GenSigAutoGenSnd" SG_ 924 Wischer_01_alt 1;
BA_ "GenSigEnvVarType" SG_ 924 Wischer_01_alt 0;
BA_ "GenSigSendType" SG_ 924 Wischer_01_alt 7;
BA_ "GenSigStartValue" SG_ 924 Wischer_01_alt 1;
BA_ "NWM-WakeupAllowed" SG_ 924 Wischer_01_alt 0;
BA_ "NMH-WakeupAllowed" SG_ 924 Wischer_01_alt 0;
BA_ "GenSigTimeoutMsg_Motor_EDC17_003" SG_ 924 Wischer_01_alt 924;
BA_ "GenSigTimeoutMsg_Motor_EDC17_004" SG_ 924 Wischer_01_alt 924;
BA_ "GenSigAutoGenDsp" SG_ 924 Klima_02_alt 1;
BA_ "GenSigAutoGenSnd" SG_ 924 Klima_02_alt 1;
BA_ "GenSigSendType" SG_ 924 Klima_02_alt 7;
BA_ "GenSigStartValue" SG_ 924 Klima_02_alt 1;
BA_ "NWM-WakeupAllowed" SG_ 924 Klima_02_alt 0;
BA_ "NMH-WakeupAllowed" SG_ 924 Klima_02_alt 0;
BA_ "GenSigAutoGenDsp" SG_ 924 BCM1_01_alt 1;
BA_ "GenSigAutoGenSnd" SG_ 924 BCM1_01_alt 1;
BA_ "GenSigSendType" SG_ 924 BCM1_01_alt 7;
BA_ "GenSigStartValue" SG_ 924 BCM1_01_alt 1;
BA_ "NWM-WakeupAllowed" SG_ 924 BCM1_01_alt 0;
BA_ "NMH-WakeupAllowed" SG_ 924 BCM1_01_alt 0;
BA_ "GenSigTimeoutMsg_Motor_EDC17_003" SG_ 924 BCM1_01_alt 924;
BA_ "GenSigTimeoutMsg_Motor_EDC17_004" SG_ 924 BCM1_01_alt 924;
BA_ "GenSigTimeoutMsg_Motor_MED17_B8" SG_ 924 BCM1_01_alt 924;
BA_ "GenSigTimeoutMsg_Motor_MED9_B8" SG_ 924 BCM1_01_alt 924;
BA_ "GenSigTimeoutMsg_Motor_SIMOS8_B8" SG_ 924 BCM1_01_alt 924;
BA_ "GenSigAutoGenDsp" SG_ 924 ESP_07_alt 1;
BA_ "GenSigAutoGenSnd" SG_ 924 ESP_07_alt 1;
BA_ "GenSigSendType" SG_ 924 ESP_07_alt 7;
BA_ "GenSigStartValue" SG_ 924 ESP_07_alt 1;
BA_ "NWM-WakeupAllowed" SG_ 924 ESP_07_alt 0;
BA_ "NMH-WakeupAllowed" SG_ 924 ESP_07_alt 0;
BA_ "GenSigTimeoutMsg_AFS_B8" SG_ 924 ESP_07_alt 924;
BA_ "GenSigTimeoutMsg_Daempfer_B8" SG_ 924 ESP_07_alt 924;
BA_ "GenSigTimeoutMsg_Motor_EDC17_003" SG_ 924 ESP_07_alt 924;
BA_ "GenSigTimeoutMsg_Motor_EDC17_004" SG_ 924 ESP_07_alt 924;
BA_ "GenSigTimeoutMsg_Motor_MED17_B8" SG_ 924 ESP_07_alt 924;
BA_ "GenSigTimeoutMsg_Motor_MED9_B8" SG_ 924 ESP_07_alt 924;
BA_ "GenSigTimeoutMsg_Motor_SIMOS8_B8" SG_ 924 ESP_07_alt 924;
BA_ "GenSigAutoGenDsp" SG_ 924 TSG_BT_1_alt 1;
BA_ "GenSigAutoGenSnd" SG_ 924 TSG_BT_1_alt 1;
BA_ "GenSigSendType" SG_ 924 TSG_BT_1_alt 7;
BA_ "GenSigStartValue" SG_ 924 TSG_BT_1_alt 1;
BA_ "NWM-WakeupAllowed" SG_ 924 TSG_BT_1_alt 0;
BA_ "NMH-WakeupAllowed" SG_ 924 TSG_BT_1_alt 0;
BA_ "GenSigAutoGenDsp" SG_ 924 TSG_HL_1_alt 1;
BA_ "GenSigAutoGenSnd" SG_ 924 TSG_HL_1_alt 1;
BA_ "GenSigSendType" SG_ 924 TSG_HL_1_alt 7;
BA_ "GenSigStartValue" SG_ 924 TSG_HL_1_alt 1;
BA_ "NWM-WakeupAllowed" SG_ 924 TSG_HL_1_alt 0;
BA_ "NMH-WakeupAllowed" SG_ 924 TSG_HL_1_alt 0;
BA_ "GenSigAutoGenDsp" SG_ 924 TSG_HR_1_alt 1;
BA_ "GenSigAutoGenSnd" SG_ 924 TSG_HR_1_alt 1;
BA_ "GenSigSendType" SG_ 924 TSG_HR_1_alt 7;
BA_ "GenSigStartValue" SG_ 924 TSG_HR_1_alt 1;
BA_ "NWM-WakeupAllowed" SG_ 924 TSG_HR_1_alt 0;
BA_ "NMH-WakeupAllowed" SG_ 924 TSG_HR_1_alt 0;
BA_ "GenSigAutoGenDsp" SG_ 924 Motor_02_alt 1;
BA_ "GenSigAutoGenSnd" SG_ 924 Motor_02_alt 1;
BA_ "GenSigSendType" SG_ 924 Motor_02_alt 7;
BA_ "GenSigStartValue" SG_ 924 Motor_02_alt 1;
BA_ "NWM-WakeupAllowed" SG_ 924 Motor_02_alt 0;
BA_ "NMH-WakeupAllowed" SG_ 924 Motor_02_alt 0;
BA_ "GenSigAutoGenDsp" SG_ 924 Klima_Sensor_02_alt 1;
BA_ "GenSigAutoGenSnd" SG_ 924 Klima_Sensor_02_alt 1;
BA_ "GenSigSendType" SG_ 924 Klima_Sensor_02_alt 7;
BA_ "GenSigStartValue" SG_ 924 Klima_Sensor_02_alt 1;
BA_ "NWM-WakeupAllowed" SG_ 924 Klima_Sensor_02_alt 0;
BA_ "NMH-WakeupAllowed" SG_ 924 Klima_Sensor_02_alt 0;
BA_ "GenSigTimeoutMsg_Motor_EDC17_003" SG_ 924 Klima_Sensor_02_alt 924;
BA_ "GenSigTimeoutMsg_Motor_EDC17_004" SG_ 924 Klima_Sensor_02_alt 924;
BA_ "GenSigTimeoutMsg_Motor_MED17_B8" SG_ 924 Klima_Sensor_02_alt 924;
BA_ "GenSigTimeoutMsg_Motor_MED9_B8" SG_ 924 Klima_Sensor_02_alt 924;
BA_ "GenSigTimeoutMsg_Motor_SIMOS8_B8" SG_ 924 Klima_Sensor_02_alt 924;
BA_ "GenSigAutoGenDsp" SG_ 924 TSG_FT_1_alt 0;
BA_ "GenSigAutoGenSnd" SG_ 924 TSG_FT_1_alt 0;
BA_ "GenSigSendType" SG_ 924 TSG_FT_1_alt 7;
BA_ "GenSigStartValue" SG_ 924 TSG_FT_1_alt 1;
BA_ "NWM-WakeupAllowed" SG_ 924 TSG_FT_1_alt 0;
BA_ "NMH-WakeupAllowed" SG_ 924 TSG_FT_1_alt 0;
BA_ "GenSigTimeoutMsg_Motor_EDC17_003" SG_ 924 TSG_FT_1_alt 924;
BA_ "GenSigTimeoutMsg_Motor_EDC17_004" SG_ 924 TSG_FT_1_alt 924;
BA_ "GenSigTimeoutMsg_Motor_MED17_B8" SG_ 924 TSG_FT_1_alt 924;
BA_ "GenSigTimeoutMsg_Motor_MED9_B8" SG_ 924 TSG_FT_1_alt 924;
BA_ "GenSigTimeoutMsg_Motor_SIMOS8_B8" SG_ 924 TSG_FT_1_alt 924;
BA_ "GenSigAutoGenDsp" SG_ 924 Motor_05_alt 1;
BA_ "GenSigAutoGenSnd" SG_ 924 Motor_05_alt 1;
BA_ "GenSigEnvVarType" SG_ 924 Motor_05_alt 0;
BA_ "GenSigSendType" SG_ 924 Motor_05_alt 7;
BA_ "GenSigStartValue" SG_ 924 Motor_05_alt 1;
BA_ "NWM-WakeupAllowed" SG_ 924 Motor_05_alt 0;
BA_ "NMH-WakeupAllowed" SG_ 924 Motor_05_alt 0;
BA_ "GenSigAutoGenDsp" SG_ 924 QSP_01_alt 1;
BA_ "GenSigAutoGenSnd" SG_ 924 QSP_01_alt 1;
BA_ "GenSigSendType" SG_ 924 QSP_01_alt 7;
BA_ "GenSigStartValue" SG_ 924 QSP_01_alt 1;
BA_ "NWM-WakeupAllowed" SG_ 924 QSP_01_alt 0;
BA_ "NMH-WakeupAllowed" SG_ 924 QSP_01_alt 0;
BA_ "GenSigAutoGenDsp" SG_ 924 Parkhilfe_01_alt 1;
BA_ "GenSigAutoGenSnd" SG_ 924 Parkhilfe_01_alt 1;
BA_ "GenSigSendType" SG_ 924 Parkhilfe_01_alt 7;
BA_ "GenSigStartValue" SG_ 924 Parkhilfe_01_alt 1;
BA_ "NWM-WakeupAllowed" SG_ 924 Parkhilfe_01_alt 0;
BA_ "NMH-WakeupAllowed" SG_ 924 Parkhilfe_01_alt 0;
BA_ "GenSigAutoGenDsp" SG_ 924 Fahrwerk_02_alt 1;
BA_ "GenSigAutoGenSnd" SG_ 924 Fahrwerk_02_alt 1;
BA_ "GenSigSendType" SG_ 924 Fahrwerk_02_alt 7;
BA_ "GenSigStartValue" SG_ 924 Fahrwerk_02_alt 1;
BA_ "NWM-WakeupAllowed" SG_ 924 Fahrwerk_02_alt 0;
BA_ "NMH-WakeupAllowed" SG_ 924 Fahrwerk_02_alt 0;
BA_ "GenSigAutoGenDsp" SG_ 924 GW_05_va_27 1;
BA_ "GenSigAutoGenSnd" SG_ 924 GW_05_va_27 1;
BA_ "GenSigSendType" SG_ 924 GW_05_va_27 7;
BA_ "GenSigStartValue" SG_ 924 GW_05_va_27 1;
BA_ "NWM-WakeupAllowed" SG_ 924 GW_05_va_27 0;
BA_ "NMH-WakeupAllowed" SG_ 924 GW_05_va_27 0;
BA_ "GenSigAutoGenDsp" SG_ 924 BCM1_MH_WIV_Schalter 1;
BA_ "GenSigAutoGenSnd" SG_ 924 BCM1_MH_WIV_Schalter 1;
BA_ "GenSigEnvVarType" SG_ 924 BCM1_MH_WIV_Schalter 0;
BA_ "GenSigSendType" SG_ 924 BCM1_MH_WIV_Schalter 3;
BA_ "NWM-WakeupAllowed" SG_ 924 BCM1_MH_WIV_Schalter 0;
BA_ "NMH-WakeupAllowed" SG_ 924 BCM1_MH_WIV_Schalter 0;
BA_ "GenSigTimeoutMsg_Motor_EDC17_003" SG_ 924 BCM1_MH_WIV_Schalter 924;
BA_ "GenSigTimeoutMsg_Motor_EDC17_004" SG_ 924 BCM1_MH_WIV_Schalter 924;
BA_ "GenSigTimeoutMsg_Motor_MED17_B8" SG_ 924 BCM1_MH_WIV_Schalter 924;
BA_ "GenSigTimeoutMsg_Motor_MED9_B8" SG_ 924 BCM1_MH_WIV_Schalter 924;
BA_ "GenSigTimeoutMsg_Motor_SIMOS8_B8" SG_ 924 BCM1_MH_WIV_Schalter 924;
BA_ "GenSigAutoGenDsp" SG_ 924 Wischer_vorne_aktiv 1;
BA_ "GenSigAutoGenSnd" SG_ 924 Wischer_vorne_aktiv 1;
BA_ "GenSigEnvVarType" SG_ 924 Wischer_vorne_aktiv 0;
BA_ "GenSigSendType" SG_ 924 Wischer_vorne_aktiv 3;
BA_ "NWM-WakeupAllowed" SG_ 924 Wischer_vorne_aktiv 0;
BA_ "NMH-WakeupAllowed" SG_ 924 Wischer_vorne_aktiv 0;
BA_ "GenSigTimeoutMsg_Motor_EDC17_003" SG_ 924 Wischer_vorne_aktiv 924;
BA_ "GenSigTimeoutMsg_Motor_EDC17_004" SG_ 924 Wischer_vorne_aktiv 924;
BA_ "GenSigAutoGenDsp" SG_ 924 BCM1_Rueckfahrlicht_Schalter 1;
BA_ "GenSigAutoGenSnd" SG_ 924 BCM1_Rueckfahrlicht_Schalter 1;
BA_ "GenSigEnvVarType" SG_ 924 BCM1_Rueckfahrlicht_Schalter 0;
BA_ "GenSigSendType" SG_ 924 BCM1_Rueckfahrlicht_Schalter 7;
BA_ "NWM-WakeupAllowed" SG_ 924 BCM1_Rueckfahrlicht_Schalter 0;
BA_ "NMH-WakeupAllowed" SG_ 924 BCM1_Rueckfahrlicht_Schalter 0;
BA_ "GenSigTimeoutMsg_AFS_B8" SG_ 924 BCM1_Rueckfahrlicht_Schalter 924;
BA_ "GenSigTimeoutMsg_Motor_EDC17_003" SG_ 924 BCM1_Rueckfahrlicht_Schalter 924;
BA_ "GenSigTimeoutMsg_Motor_EDC17_004" SG_ 924 BCM1_Rueckfahrlicht_Schalter 924;
BA_ "GenSigTimeoutMsg_Motor_MED17_B8" SG_ 924 BCM1_Rueckfahrlicht_Schalter 924;
BA_ "GenSigTimeoutMsg_Motor_MED9_B8" SG_ 924 BCM1_Rueckfahrlicht_Schalter 924;
BA_ "GenSigTimeoutMsg_Motor_SIMOS8_B8" SG_ 924 BCM1_Rueckfahrlicht_Schalter 924;
BA_ "GenSigAutoGenDsp" SG_ 924 KL_Zuheizer_Freigabe 0;
BA_ "GenSigAutoGenSnd" SG_ 924 KL_Zuheizer_Freigabe 0;
BA_ "GenSigSendType" SG_ 924 KL_Zuheizer_Freigabe 7;
BA_ "NWM-WakeupAllowed" SG_ 924 KL_Zuheizer_Freigabe 0;
BA_ "NMH-WakeupAllowed" SG_ 924 KL_Zuheizer_Freigabe 0;
BA_ "GenSigAutoGenDsp" SG_ 924 BCM1_Vorwaertsgang_eingelegt 1;
BA_ "GenSigAutoGenSnd" SG_ 924 BCM1_Vorwaertsgang_eingelegt 1;
BA_ "GenSigSendType" SG_ 924 BCM1_Vorwaertsgang_eingelegt 7;
BA_ "NWM-WakeupAllowed" SG_ 924 BCM1_Vorwaertsgang_eingelegt 0;
BA_ "NMH-WakeupAllowed" SG_ 924 BCM1_Vorwaertsgang_eingelegt 0;
BA_ "GenSigAutoGenDsp" SG_ 924 ESP_Codierung_ADS 1;
BA_ "GenSigAutoGenSnd" SG_ 924 ESP_Codierung_ADS 1;
BA_ "GenSigEnvVarType" SG_ 924 ESP_Codierung_ADS 0;
BA_ "GenSigSendType" SG_ 924 ESP_Codierung_ADS 7;
BA_ "NWM-WakeupAllowed" SG_ 924 ESP_Codierung_ADS 0;
BA_ "NMH-WakeupAllowed" SG_ 924 ESP_Codierung_ADS 0;
BA_ "GenSigTimeoutMsg_AFS_B8" SG_ 924 ESP_Codierung_ADS 924;
BA_ "GenSigTimeoutMsg_Daempfer_B8" SG_ 924 ESP_Codierung_ADS 924;
BA_ "GenSigTimeoutMsg_Motor_EDC17_003" SG_ 924 ESP_Codierung_ADS 924;
BA_ "GenSigTimeoutMsg_Motor_EDC17_004" SG_ 924 ESP_Codierung_ADS 924;
BA_ "GenSigTimeoutMsg_Motor_MED17_B8" SG_ 924 ESP_Codierung_ADS 924;
BA_ "GenSigTimeoutMsg_Motor_MED9_B8" SG_ 924 ESP_Codierung_ADS 924;
BA_ "GenSigTimeoutMsg_Motor_SIMOS8_B8" SG_ 924 ESP_Codierung_ADS 924;
BA_ "GenSigAutoGenDsp" SG_ 924 BCM1_RFahrlicht_Fzg_Anf 0;
BA_ "GenSigAutoGenSnd" SG_ 924 BCM1_RFahrlicht_Fzg_Anf 0;
BA_ "GenSigSendType" SG_ 924 BCM1_RFahrlicht_Fzg_Anf 7;
BA_ "NWM-WakeupAllowed" SG_ 924 BCM1_RFahrlicht_Fzg_Anf 0;
BA_ "NMH-WakeupAllowed" SG_ 924 BCM1_RFahrlicht_Fzg_Anf 0;
BA_ "GenSigAutoGenDsp" SG_ 924 FT_Tuer_geoeffnet 0;
BA_ "GenSigAutoGenSnd" SG_ 924 FT_Tuer_geoeffnet 0;
BA_ "GenSigSendType" SG_ 924 FT_Tuer_geoeffnet 7;
BA_ "NWM-WakeupAllowed" SG_ 924 FT_Tuer_geoeffnet 0;
BA_ "NMH-WakeupAllowed" SG_ 924 FT_Tuer_geoeffnet 0;
BA_ "GenSigTimeoutMsg_Motor_EDC17_003" SG_ 924 FT_Tuer_geoeffnet 924;
BA_ "GenSigTimeoutMsg_Motor_EDC17_004" SG_ 924 FT_Tuer_geoeffnet 924;
BA_ "GenSigTimeoutMsg_Motor_MED17_B8" SG_ 924 FT_Tuer_geoeffnet 924;
BA_ "GenSigTimeoutMsg_Motor_MED9_B8" SG_ 924 FT_Tuer_geoeffnet 924;
BA_ "GenSigTimeoutMsg_Motor_SIMOS8_B8" SG_ 924 FT_Tuer_geoeffnet 924;
BA_ "GenSigAutoGenDsp" SG_ 924 MO_Handshake_STH 1;
BA_ "GenSigAutoGenSnd" SG_ 924 MO_Handshake_STH 1;
BA_ "GenSigSendType" SG_ 924 MO_Handshake_STH 7;
BA_ "NWM-WakeupAllowed" SG_ 924 MO_Handshake_STH 0;
BA_ "NMH-WakeupAllowed" SG_ 924 MO_Handshake_STH 0;
BA_ "GenSigAutoGenDsp" SG_ 924 BCM1_OBD_FStatus_ATemp 1;
BA_ "GenSigAutoGenSnd" SG_ 924 BCM1_OBD_FStatus_ATemp 1;
BA_ "GenSigEnvVarType" SG_ 924 BCM1_OBD_FStatus_ATemp 0;
BA_ "GenSigSendType" SG_ 924 BCM1_OBD_FStatus_ATemp 7;
BA_ "NWM-WakeupAllowed" SG_ 924 BCM1_OBD_FStatus_ATemp 0;
BA_ "NMH-WakeupAllowed" SG_ 924 BCM1_OBD_FStatus_ATemp 0;
BA_ "GenSigTimeoutMsg_Motor_EDC17_003" SG_ 924 BCM1_OBD_FStatus_ATemp 924;
BA_ "GenSigTimeoutMsg_Motor_EDC17_004" SG_ 924 BCM1_OBD_FStatus_ATemp 924;
BA_ "GenSigTimeoutMsg_Motor_MED17_B8" SG_ 924 BCM1_OBD_FStatus_ATemp 924;
BA_ "GenSigTimeoutMsg_Motor_MED9_B8" SG_ 924 BCM1_OBD_FStatus_ATemp 924;
BA_ "GenSigTimeoutMsg_Motor_SIMOS8_B8" SG_ 924 BCM1_OBD_FStatus_ATemp 924;
BA_ "GenSigAutoGenDsp" SG_ 924 BCM1_Aussen_Temp_ungef 1;
BA_ "GenSigAutoGenSnd" SG_ 924 BCM1_Aussen_Temp_ungef 1;
BA_ "GenSigEnvVarType" SG_ 924 BCM1_Aussen_Temp_ungef 1;
BA_ "GenSigSendType" SG_ 924 BCM1_Aussen_Temp_ungef 7;
BA_ "GenSigStartValue" SG_ 924 BCM1_Aussen_Temp_ungef 254;
BA_ "NWM-WakeupAllowed" SG_ 924 BCM1_Aussen_Temp_ungef 0;
BA_ "NMH-WakeupAllowed" SG_ 924 BCM1_Aussen_Temp_ungef 0;
BA_ "GenSigTimeoutMsg_Motor_EDC17_003" SG_ 924 BCM1_Aussen_Temp_ungef 924;
BA_ "GenSigTimeoutMsg_Motor_EDC17_004" SG_ 924 BCM1_Aussen_Temp_ungef 924;
BA_ "GenSigTimeoutMsg_Motor_MED17_B8" SG_ 924 BCM1_Aussen_Temp_ungef 924;
BA_ "GenSigTimeoutMsg_Motor_MED9_B8" SG_ 924 BCM1_Aussen_Temp_ungef 924;
BA_ "GenSigTimeoutMsg_Motor_SIMOS8_B8" SG_ 924 BCM1_Aussen_Temp_ungef 924;
BA_ "GenSigAutoGenDsp" SG_ 924 BCM1_Oeldruck_Schalter 1;
BA_ "GenSigAutoGenSnd" SG_ 924 BCM1_Oeldruck_Schalter 1;
BA_ "GenSigEnvVarType" SG_ 924 BCM1_Oeldruck_Schalter 0;
BA_ "GenSigSendType" SG_ 924 BCM1_Oeldruck_Schalter 3;
BA_ "NWM-WakeupAllowed" SG_ 924 BCM1_Oeldruck_Schalter 0;
BA_ "NMH-WakeupAllowed" SG_ 924 BCM1_Oeldruck_Schalter 0;
BA_ "GenSigTimeoutMsg_Motor_EDC17_003" SG_ 924 BCM1_Oeldruck_Schalter 924;
BA_ "GenSigTimeoutMsg_Motor_EDC17_004" SG_ 924 BCM1_Oeldruck_Schalter 924;
BA_ "GenSigTimeoutMsg_Motor_MED17_B8" SG_ 924 BCM1_Oeldruck_Schalter 924;
BA_ "GenSigTimeoutMsg_Motor_MED9_B8" SG_ 924 BCM1_Oeldruck_Schalter 924;
BA_ "GenSigTimeoutMsg_Motor_SIMOS8_B8" SG_ 924 BCM1_Oeldruck_Schalter 924;
BA_ "GenSigAutoGenDsp" SG_ 924 BCM1_Oeldruck_Schalter_2 1;
BA_ "GenSigAutoGenSnd" SG_ 924 BCM1_Oeldruck_Schalter_2 1;
BA_ "GenSigEnvVarType" SG_ 924 BCM1_Oeldruck_Schalter_2 0;
BA_ "GenSigSendType" SG_ 924 BCM1_Oeldruck_Schalter_2 3;
BA_ "NWM-WakeupAllowed" SG_ 924 BCM1_Oeldruck_Schalter_2 0;
BA_ "NMH-WakeupAllowed" SG_ 924 BCM1_Oeldruck_Schalter_2 0;
BA_ "GenSigAutoGenDsp" SG_ 1604 SMLS_01_alt 1;
BA_ "GenSigAutoGenSnd" SG_ 1604 SMLS_01_alt 1;
BA_ "GenSigSendType" SG_ 1604 SMLS_01_alt 7;
BA_ "GenSigStartValue" SG_ 1604 SMLS_01_alt 1;
BA_ "NWM-WakeupAllowed" SG_ 1604 SMLS_01_alt 0;
BA_ "NMH-WakeupAllowed" SG_ 1604 SMLS_01_alt 0;
BA_ "GenSigTimeoutMsg_AFS_B8" SG_ 1604 SMLS_01_alt 1604;
BA_ "GenSigAutoGenDsp" SG_ 1604 BCM1_01_alt 1;
BA_ "GenSigAutoGenSnd" SG_ 1604 BCM1_01_alt 1;
BA_ "GenSigSendType" SG_ 1604 BCM1_01_alt 7;
BA_ "GenSigStartValue" SG_ 1604 BCM1_01_alt 1;
BA_ "NWM-WakeupAllowed" SG_ 1604 BCM1_01_alt 0;
BA_ "NMH-WakeupAllowed" SG_ 1604 BCM1_01_alt 0;
BA_ "GenSigTimeoutMsg_AFS_B8" SG_ 1604 BCM1_01_alt 1604;
BA_ "GenSigTimeoutMsg_LWR_B8" SG_ 1604 BCM1_01_alt 1604;
BA_ "GenSigAutoGenDsp" SG_ 1604 BCM1_02_alt 1;
BA_ "GenSigAutoGenSnd" SG_ 1604 BCM1_02_alt 1;
BA_ "GenSigEnvVarType" SG_ 1604 BCM1_02_alt 0;
BA_ "GenSigSendType" SG_ 1604 BCM1_02_alt 7;
BA_ "GenSigStartValue" SG_ 1604 BCM1_02_alt 1;
BA_ "NWM-WakeupAllowed" SG_ 1604 BCM1_02_alt 0;
BA_ "NMH-WakeupAllowed" SG_ 1604 BCM1_02_alt 0;
BA_ "GenSigTimeoutMsg_AFS_B8" SG_ 1604 BCM1_02_alt 1604;
BA_ "GenSigTimeoutMsg_LWR_B8" SG_ 1604 BCM1_02_alt 1604;
BA_ "GenSigAutoGenDsp" SG_ 1604 BCM2_02_alt 1;
BA_ "GenSigAutoGenSnd" SG_ 1604 BCM2_02_alt 1;
BA_ "GenSigSendType" SG_ 1604 BCM2_02_alt 7;
BA_ "GenSigStartValue" SG_ 1604 BCM2_02_alt 1;
BA_ "NWM-WakeupAllowed" SG_ 1604 BCM2_02_alt 0;
BA_ "NMH-WakeupAllowed" SG_ 1604 BCM2_02_alt 0;
BA_ "GenSigTimeoutMsg_Getriebe_VL3002" SG_ 1604 BCM2_02_alt 1604;
BA_ "GenSigAutoGenDsp" SG_ 1604 HYB_Anf_E_Mode_alt 1;
BA_ "GenSigAutoGenSnd" SG_ 1604 HYB_Anf_E_Mode_alt 1;
BA_ "GenSigSendType" SG_ 1604 HYB_Anf_E_Mode_alt 7;
BA_ "GenSigStartValue" SG_ 1604 HYB_Anf_E_Mode_alt 1;
BA_ "NWM-WakeupAllowed" SG_ 1604 HYB_Anf_E_Mode_alt 0;
BA_ "NMH-WakeupAllowed" SG_ 1604 HYB_Anf_E_Mode_alt 0;
BA_ "GenSigAutoGenDsp" SG_ 1604 GW_11_va_20 1;
BA_ "GenSigAutoGenSnd" SG_ 1604 GW_11_va_20 1;
BA_ "GenSigSendType" SG_ 1604 GW_11_va_20 7;
BA_ "GenSigStartValue" SG_ 1604 GW_11_va_20 1;
BA_ "NWM-WakeupAllowed" SG_ 1604 GW_11_va_20 0;
BA_ "NMH-WakeupAllowed" SG_ 1604 GW_11_va_20 0;
BA_ "GenSigAutoGenDsp" SG_ 1604 GW_11_va_21 1;
BA_ "GenSigAutoGenSnd" SG_ 1604 GW_11_va_21 1;
BA_ "GenSigSendType" SG_ 1604 GW_11_va_21 7;
BA_ "GenSigStartValue" SG_ 1604 GW_11_va_21 1;
BA_ "NWM-WakeupAllowed" SG_ 1604 GW_11_va_21 0;
BA_ "NMH-WakeupAllowed" SG_ 1604 GW_11_va_21 0;
BA_ "GenSigAutoGenDsp" SG_ 1604 GW_11_va_22 1;
BA_ "GenSigAutoGenSnd" SG_ 1604 GW_11_va_22 1;
BA_ "GenSigSendType" SG_ 1604 GW_11_va_22 7;
BA_ "GenSigStartValue" SG_ 1604 GW_11_va_22 1;
BA_ "NWM-WakeupAllowed" SG_ 1604 GW_11_va_22 0;
BA_ "NMH-WakeupAllowed" SG_ 1604 GW_11_va_22 0;
BA_ "GenSigAutoGenDsp" SG_ 1604 GW_11_va_23 1;
BA_ "GenSigAutoGenSnd" SG_ 1604 GW_11_va_23 1;
BA_ "GenSigSendType" SG_ 1604 GW_11_va_23 7;
BA_ "GenSigStartValue" SG_ 1604 GW_11_va_23 1;
BA_ "NWM-WakeupAllowed" SG_ 1604 GW_11_va_23 0;
BA_ "NMH-WakeupAllowed" SG_ 1604 GW_11_va_23 0;
BA_ "GenSigAutoGenDsp" SG_ 1604 GW_11_va_24 1;
BA_ "GenSigAutoGenSnd" SG_ 1604 GW_11_va_24 1;
BA_ "GenSigSendType" SG_ 1604 GW_11_va_24 7;
BA_ "GenSigStartValue" SG_ 1604 GW_11_va_24 1;
BA_ "NWM-WakeupAllowed" SG_ 1604 GW_11_va_24 0;
BA_ "NMH-WakeupAllowed" SG_ 1604 GW_11_va_24 0;
BA_ "GenSigAutoGenDsp" SG_ 1604 GW_11_va_25 1;
BA_ "GenSigAutoGenSnd" SG_ 1604 GW_11_va_25 1;
BA_ "GenSigSendType" SG_ 1604 GW_11_va_25 7;
BA_ "GenSigStartValue" SG_ 1604 GW_11_va_25 1;
BA_ "NWM-WakeupAllowed" SG_ 1604 GW_11_va_25 0;
BA_ "NMH-WakeupAllowed" SG_ 1604 GW_11_va_25 0;
BA_ "GenSigAutoGenDsp" SG_ 1604 GW_11_va_26 1;
BA_ "GenSigAutoGenSnd" SG_ 1604 GW_11_va_26 1;
BA_ "GenSigSendType" SG_ 1604 GW_11_va_26 7;
BA_ "GenSigStartValue" SG_ 1604 GW_11_va_26 1;
BA_ "NWM-WakeupAllowed" SG_ 1604 GW_11_va_26 0;
BA_ "NMH-WakeupAllowed" SG_ 1604 GW_11_va_26 0;
BA_ "GenSigAutoGenDsp" SG_ 1604 GW_11_va_27 1;
BA_ "GenSigAutoGenSnd" SG_ 1604 GW_11_va_27 1;
BA_ "GenSigSendType" SG_ 1604 GW_11_va_27 7;
BA_ "GenSigStartValue" SG_ 1604 GW_11_va_27 1;
BA_ "NWM-WakeupAllowed" SG_ 1604 GW_11_va_27 0;
BA_ "NMH-WakeupAllowed" SG_ 1604 GW_11_va_27 0;
BA_ "GenSigAutoGenDsp" SG_ 1604 BH_Blinker_li 1;
BA_ "GenSigAutoGenSnd" SG_ 1604 BH_Blinker_li 1;
BA_ "GenSigEnvVarType" SG_ 1604 BH_Blinker_li 0;
BA_ "GenSigSendType" SG_ 1604 BH_Blinker_li 7;
BA_ "NWM-WakeupAllowed" SG_ 1604 BH_Blinker_li 0;
BA_ "NMH-WakeupAllowed" SG_ 1604 BH_Blinker_li 0;
BA_ "GenSigTimeoutMsg_AFS_B8" SG_ 1604 BH_Blinker_li 1604;
BA_ "GenSigAutoGenDsp" SG_ 1604 BH_Blinker_re 1;
BA_ "GenSigAutoGenSnd" SG_ 1604 BH_Blinker_re 1;
BA_ "GenSigEnvVarType" SG_ 1604 BH_Blinker_re 0;
BA_ "GenSigSendType" SG_ 1604 BH_Blinker_re 7;
BA_ "NWM-WakeupAllowed" SG_ 1604 BH_Blinker_re 0;
BA_ "NMH-WakeupAllowed" SG_ 1604 BH_Blinker_re 0;
BA_ "GenSigTimeoutMsg_AFS_B8" SG_ 1604 BH_Blinker_re 1604;
BA_ "GenSigAutoGenDsp" SG_ 1604 BM_Autobahn 1;
BA_ "GenSigAutoGenSnd" SG_ 1604 BM_Autobahn 1;
BA_ "GenSigEnvVarType" SG_ 1604 BM_Autobahn 0;
BA_ "GenSigSendType" SG_ 1604 BM_Autobahn 7;
BA_ "NWM-WakeupAllowed" SG_ 1604 BM_Autobahn 0;
BA_ "NMH-WakeupAllowed" SG_ 1604 BM_Autobahn 0;
BA_ "GenSigAutoGenDsp" SG_ 1604 BCM1_MH_Schalter 1;
BA_ "GenSigAutoGenSnd" SG_ 1604 BCM1_MH_Schalter 1;
BA_ "GenSigEnvVarType" SG_ 1604 BCM1_MH_Schalter 0;
BA_ "GenSigSendType" SG_ 1604 BCM1_MH_Schalter 7;
BA_ "NWM-WakeupAllowed" SG_ 1604 BCM1_MH_Schalter 0;
BA_ "NMH-WakeupAllowed" SG_ 1604 BCM1_MH_Schalter 0;
BA_ "GenSigTimeoutMsg_AFS_B8" SG_ 1604 BCM1_MH_Schalter 1604;
BA_ "GenSigAutoGenDsp" SG_ 1604 BCM1_Touristen_Licht_Anf 0;
BA_ "GenSigAutoGenSnd" SG_ 1604 BCM1_Touristen_Licht_Anf 0;
BA_ "GenSigSendType" SG_ 1604 BCM1_Touristen_Licht_Anf 7;
BA_ "NWM-WakeupAllowed" SG_ 1604 BCM1_Touristen_Licht_Anf 0;
BA_ "NMH-WakeupAllowed" SG_ 1604 BCM1_Touristen_Licht_Anf 0;
BA_ "GenSigTimeoutMsg_AFS_B8" SG_ 1604 BCM1_Touristen_Licht_Anf 1604;
BA_ "GenSigTimeoutMsg_LWR_B8" SG_ 1604 BCM1_Touristen_Licht_Anf 1604;
BA_ "GenSigAutoGenDsp" SG_ 1604 LV_Abblendlicht_li_def 1;
BA_ "GenSigAutoGenSnd" SG_ 1604 LV_Abblendlicht_li_def 1;
BA_ "GenSigEnvVarType" SG_ 1604 LV_Abblendlicht_li_def 0;
BA_ "GenSigSendType" SG_ 1604 LV_Abblendlicht_li_def 7;
BA_ "NWM-WakeupAllowed" SG_ 1604 LV_Abblendlicht_li_def 0;
BA_ "NMH-WakeupAllowed" SG_ 1604 LV_Abblendlicht_li_def 0;
BA_ "GenSigTimeoutMsg_AFS_B8" SG_ 1604 LV_Abblendlicht_li_def 1604;
BA_ "GenSigAutoGenDsp" SG_ 1604 LV_Abblendlicht_re_def 1;
BA_ "GenSigAutoGenSnd" SG_ 1604 LV_Abblendlicht_re_def 1;
BA_ "GenSigEnvVarType" SG_ 1604 LV_Abblendlicht_re_def 0;
BA_ "GenSigSendType" SG_ 1604 LV_Abblendlicht_re_def 7;
BA_ "NWM-WakeupAllowed" SG_ 1604 LV_Abblendlicht_re_def 0;
BA_ "NMH-WakeupAllowed" SG_ 1604 LV_Abblendlicht_re_def 0;
BA_ "GenSigTimeoutMsg_AFS_B8" SG_ 1604 LV_Abblendlicht_re_def 1604;
BA_ "GenSigAutoGenDsp" SG_ 1604 LV_Abblendlicht_Anzeige 1;
BA_ "GenSigAutoGenSnd" SG_ 1604 LV_Abblendlicht_Anzeige 1;
BA_ "GenSigEnvVarType" SG_ 1604 LV_Abblendlicht_Anzeige 0;
BA_ "GenSigSendType" SG_ 1604 LV_Abblendlicht_Anzeige 3;
BA_ "NWM-WakeupAllowed" SG_ 1604 LV_Abblendlicht_Anzeige 0;
BA_ "NMH-WakeupAllowed" SG_ 1604 LV_Abblendlicht_Anzeige 0;
BA_ "GenSigTimeoutMsg_AFS_B8" SG_ 1604 LV_Abblendlicht_Anzeige 1604;
BA_ "GenSigTimeoutMsg_LWR_B8" SG_ 1604 LV_Abblendlicht_Anzeige 1604;
BA_ "GenSigAutoGenDsp" SG_ 1604 BCM2_P_verriegelt 1;
BA_ "GenSigAutoGenSnd" SG_ 1604 BCM2_P_verriegelt 1;
BA_ "GenSigSendType" SG_ 1604 BCM2_P_verriegelt 7;
BA_ "NWM-WakeupAllowed" SG_ 1604 BCM2_P_verriegelt 0;
BA_ "NMH-WakeupAllowed" SG_ 1604 BCM2_P_verriegelt 0;
BA_ "GenSigTimeoutMsg_Getriebe_VL3002" SG_ 1604 BCM2_P_verriegelt 1604;
BA_ "GenSigAutoGenDsp" SG_ 1138 Anhaenger_01_alt 0;
BA_ "GenSigAutoGenSnd" SG_ 1138 Anhaenger_01_alt 0;
BA_ "GenSigSendType" SG_ 1138 Anhaenger_01_alt 7;
BA_ "GenSigStartValue" SG_ 1138 Anhaenger_01_alt 1;
BA_ "NWM-WakeupAllowed" SG_ 1138 Anhaenger_01_alt 0;
BA_ "NMH-WakeupAllowed" SG_ 1138 Anhaenger_01_alt 0;
BA_ "GenSigTimeoutMsg_Motor_MED9_B8" SG_ 1138 Anhaenger_01_alt 1138;
BA_ "GenSigAutoGenDsp" SG_ 1138 GW_MED9_01_va_11 1;
BA_ "GenSigAutoGenSnd" SG_ 1138 GW_MED9_01_va_11 1;
BA_ "GenSigSendType" SG_ 1138 GW_MED9_01_va_11 7;
BA_ "GenSigStartValue" SG_ 1138 GW_MED9_01_va_11 1;
BA_ "NWM-WakeupAllowed" SG_ 1138 GW_MED9_01_va_11 0;
BA_ "NMH-WakeupAllowed" SG_ 1138 GW_MED9_01_va_11 0;
BA_ "GenSigAutoGenDsp" SG_ 1138 Kombi_01_alt 1;
BA_ "GenSigAutoGenSnd" SG_ 1138 Kombi_01_alt 1;
BA_ "GenSigSendType" SG_ 1138 Kombi_01_alt 7;
BA_ "GenSigStartValue" SG_ 1138 Kombi_01_alt 1;
BA_ "NWM-WakeupAllowed" SG_ 1138 Kombi_01_alt 0;
BA_ "NMH-WakeupAllowed" SG_ 1138 Kombi_01_alt 0;
BA_ "GenSigTimeoutMsg_Motor_MED9_B8" SG_ 1138 Kombi_01_alt 1138;
BA_ "GenSigAutoGenDsp" SG_ 1138 STH_01_alt 1;
BA_ "GenSigAutoGenSnd" SG_ 1138 STH_01_alt 1;
BA_ "GenSigSendType" SG_ 1138 STH_01_alt 7;
BA_ "GenSigStartValue" SG_ 1138 STH_01_alt 1;
BA_ "NWM-WakeupAllowed" SG_ 1138 STH_01_alt 0;
BA_ "NMH-WakeupAllowed" SG_ 1138 STH_01_alt 0;
BA_ "GenSigTimeoutMsg_Motor_MED9_B8" SG_ 1138 STH_01_alt 1138;
BA_ "GenSigAutoGenDsp" SG_ 1138 Licht_hinten_01_alt 1;
BA_ "GenSigAutoGenSnd" SG_ 1138 Licht_hinten_01_alt 1;
BA_ "GenSigSendType" SG_ 1138 Licht_hinten_01_alt 7;
BA_ "GenSigStartValue" SG_ 1138 Licht_hinten_01_alt 1;
BA_ "NWM-WakeupAllowed" SG_ 1138 Licht_hinten_01_alt 0;
BA_ "NMH-WakeupAllowed" SG_ 1138 Licht_hinten_01_alt 0;
BA_ "GenSigTimeoutMsg_Motor_MED9_B8" SG_ 1138 Licht_hinten_01_alt 1138;
BA_ "GenSigAutoGenDsp" SG_ 1138 GW_MED9_01_va_15 1;
BA_ "GenSigAutoGenSnd" SG_ 1138 GW_MED9_01_va_15 1;
BA_ "GenSigSendType" SG_ 1138 GW_MED9_01_va_15 7;
BA_ "GenSigStartValue" SG_ 1138 GW_MED9_01_va_15 1;
BA_ "NWM-WakeupAllowed" SG_ 1138 GW_MED9_01_va_15 0;
BA_ "NMH-WakeupAllowed" SG_ 1138 GW_MED9_01_va_15 0;
BA_ "GenSigTimeoutMsg_Motor_MED9_B8" SG_ 1138 GW_MED9_01_va_15 1138;
BA_ "GenSigAutoGenDsp" SG_ 1138 GW_MED9_01_va_16 1;
BA_ "GenSigAutoGenSnd" SG_ 1138 GW_MED9_01_va_16 1;
BA_ "GenSigSendType" SG_ 1138 GW_MED9_01_va_16 7;
BA_ "GenSigStartValue" SG_ 1138 GW_MED9_01_va_16 1;
BA_ "NWM-WakeupAllowed" SG_ 1138 GW_MED9_01_va_16 0;
BA_ "NMH-WakeupAllowed" SG_ 1138 GW_MED9_01_va_16 0;
BA_ "GenSigTimeoutMsg_Motor_MED9_B8" SG_ 1138 GW_MED9_01_va_16 1138;
BA_ "GenSigAutoGenDsp" SG_ 1138 GW_MED9_01_va_17 1;
BA_ "GenSigAutoGenSnd" SG_ 1138 GW_MED9_01_va_17 1;
BA_ "GenSigSendType" SG_ 1138 GW_MED9_01_va_17 7;
BA_ "GenSigStartValue" SG_ 1138 GW_MED9_01_va_17 1;
BA_ "NWM-WakeupAllowed" SG_ 1138 GW_MED9_01_va_17 0;
BA_ "NMH-WakeupAllowed" SG_ 1138 GW_MED9_01_va_17 0;
BA_ "GenSigTimeoutMsg_Motor_MED9_B8" SG_ 1138 GW_MED9_01_va_17 1138;
BA_ "GenSigAutoGenDsp" SG_ 1138 AAG_BZ 1;
BA_ "GenSigAutoGenSnd" SG_ 1138 AAG_BZ 1;
BA_ "GenSigEnvVarType" SG_ 1138 AAG_BZ 0;
BA_ "GenSigSendType" SG_ 1138 AAG_BZ 7;
BA_ "NWM-WakeupAllowed" SG_ 1138 AAG_BZ 0;
BA_ "NMH-WakeupAllowed" SG_ 1138 AAG_BZ 0;
BA_ "GenSigTimeoutMsg_Motor_MED9_B8" SG_ 1138 AAG_BZ 1138;
BA_ "GenSigAutoGenDsp" SG_ 1138 AAG_Bremsl_durch_ECD 1;
BA_ "GenSigAutoGenSnd" SG_ 1138 AAG_Bremsl_durch_ECD 1;
BA_ "GenSigEnvVarType" SG_ 1138 AAG_Bremsl_durch_ECD 0;
BA_ "GenSigSendType" SG_ 1138 AAG_Bremsl_durch_ECD 7;
BA_ "NWM-WakeupAllowed" SG_ 1138 AAG_Bremsl_durch_ECD 0;
BA_ "NMH-WakeupAllowed" SG_ 1138 AAG_Bremsl_durch_ECD 0;
BA_ "GenSigTimeoutMsg_Motor_MED9_B8" SG_ 1138 AAG_Bremsl_durch_ECD 1138;
BA_ "GenSigAutoGenDsp" SG_ 1138 AAG_Anhaenger_erkannt 1;
BA_ "GenSigAutoGenSnd" SG_ 1138 AAG_Anhaenger_erkannt 1;
BA_ "GenSigEnvVarType" SG_ 1138 AAG_Anhaenger_erkannt 0;
BA_ "GenSigSendType" SG_ 1138 AAG_Anhaenger_erkannt 7;
BA_ "NWM-WakeupAllowed" SG_ 1138 AAG_Anhaenger_erkannt 0;
BA_ "NMH-WakeupAllowed" SG_ 1138 AAG_Anhaenger_erkannt 0;
BA_ "GenSigTimeoutMsg_Motor_MED9_B8" SG_ 1138 AAG_Anhaenger_erkannt 1138;
BA_ "GenSigAutoGenDsp" SG_ 1138 AAG_Bremslicht_H_def 1;
BA_ "GenSigAutoGenSnd" SG_ 1138 AAG_Bremslicht_H_def 1;
BA_ "GenSigEnvVarType" SG_ 1138 AAG_Bremslicht_H_def 0;
BA_ "GenSigSendType" SG_ 1138 AAG_Bremslicht_H_def 7;
BA_ "NWM-WakeupAllowed" SG_ 1138 AAG_Bremslicht_H_def 0;
BA_ "NMH-WakeupAllowed" SG_ 1138 AAG_Bremslicht_H_def 0;
BA_ "GenSigTimeoutMsg_Motor_MED9_B8" SG_ 1138 AAG_Bremslicht_H_def 1138;
BA_ "GenSigAutoGenDsp" SG_ 1138 KBI_Tankwarnung 1;
BA_ "GenSigAutoGenSnd" SG_ 1138 KBI_Tankwarnung 1;
BA_ "GenSigEnvVarType" SG_ 1138 KBI_Tankwarnung 0;
BA_ "GenSigSendType" SG_ 1138 KBI_Tankwarnung 7;
BA_ "NWM-WakeupAllowed" SG_ 1138 KBI_Tankwarnung 0;
BA_ "NMH-WakeupAllowed" SG_ 1138 KBI_Tankwarnung 0;
BA_ "GenSigTimeoutMsg_Motor_MED9_B8" SG_ 1138 KBI_Tankwarnung 1138;
BA_ "GenSigAutoGenDsp" SG_ 1138 KBI_MFA_v_Einheit_01 1;
BA_ "GenSigAutoGenSnd" SG_ 1138 KBI_MFA_v_Einheit_01 1;
BA_ "GenSigSendType" SG_ 1138 KBI_MFA_v_Einheit_01 7;
BA_ "NWM-WakeupAllowed" SG_ 1138 KBI_MFA_v_Einheit_01 0;
BA_ "NMH-WakeupAllowed" SG_ 1138 KBI_MFA_v_Einheit_01 0;
BA_ "GenSigTimeoutMsg_Motor_MED9_B8" SG_ 1138 KBI_MFA_v_Einheit_01 1138;
BA_ "GenSigAutoGenDsp" SG_ 1138 KBI_Einheit_Tacho 1;
BA_ "GenSigAutoGenSnd" SG_ 1138 KBI_Einheit_Tacho 1;
BA_ "GenSigEnvVarType" SG_ 1138 KBI_Einheit_Tacho 0;
BA_ "GenSigSendType" SG_ 1138 KBI_Einheit_Tacho 7;
BA_ "NWM-WakeupAllowed" SG_ 1138 KBI_Einheit_Tacho 0;
BA_ "NMH-WakeupAllowed" SG_ 1138 KBI_Einheit_Tacho 0;
BA_ "GenSigTimeoutMsg_Motor_MED9_B8" SG_ 1138 KBI_Einheit_Tacho 1138;
BA_ "GenSigAutoGenDsp" SG_ 1138 KBI_angez_Geschw 1;
BA_ "GenSigAutoGenSnd" SG_ 1138 KBI_angez_Geschw 1;
BA_ "GenSigEnvVarType" SG_ 1138 KBI_angez_Geschw 1;
BA_ "GenSigSendType" SG_ 1138 KBI_angez_Geschw 7;
BA_ "NWM-WakeupAllowed" SG_ 1138 KBI_angez_Geschw 0;
BA_ "NMH-WakeupAllowed" SG_ 1138 KBI_angez_Geschw 0;
BA_ "GenSigTimeoutMsg_Motor_MED9_B8" SG_ 1138 KBI_angez_Geschw 1138;
BA_ "GenSigAutoGenDsp" SG_ 1138 STH_Ventiloeffnungszeit 1;
BA_ "GenSigAutoGenSnd" SG_ 1138 STH_Ventiloeffnungszeit 1;
BA_ "GenSigSendType" SG_ 1138 STH_Ventiloeffnungszeit 7;
BA_ "NWM-WakeupAllowed" SG_ 1138 STH_Ventiloeffnungszeit 0;
BA_ "NMH-WakeupAllowed" SG_ 1138 STH_Ventiloeffnungszeit 0;
BA_ "GenSigTimeoutMsg_Motor_MED9_B8" SG_ 1138 STH_Ventiloeffnungszeit 1138;
BA_ "GenSigAutoGenDsp" SG_ 1138 STH_EKP_Anst 1;
BA_ "GenSigAutoGenSnd" SG_ 1138 STH_EKP_Anst 1;
BA_ "GenSigEnvVarType" SG_ 1138 STH_EKP_Anst 0;
BA_ "GenSigSendType" SG_ 1138 STH_EKP_Anst 7;
BA_ "NWM-WakeupAllowed" SG_ 1138 STH_EKP_Anst 0;
BA_ "NMH-WakeupAllowed" SG_ 1138 STH_EKP_Anst 0;
BA_ "GenSigTimeoutMsg_Motor_MED9_B8" SG_ 1138 STH_EKP_Anst 1138;
BA_ "GenSigAutoGenDsp" SG_ 1138 STH_Motorvorwaermung 1;
BA_ "GenSigAutoGenSnd" SG_ 1138 STH_Motorvorwaermung 1;
BA_ "GenSigSendType" SG_ 1138 STH_Motorvorwaermung 7;
BA_ "NWM-WakeupAllowed" SG_ 1138 STH_Motorvorwaermung 0;
BA_ "NMH-WakeupAllowed" SG_ 1138 STH_Motorvorwaermung 0;
BA_ "GenSigTimeoutMsg_Motor_MED9_B8" SG_ 1138 STH_Motorvorwaermung 1138;
BA_ "GenSigAutoGenDsp" SG_ 1138 STH_Waermeeintrag 1;
BA_ "GenSigAutoGenSnd" SG_ 1138 STH_Waermeeintrag 1;
BA_ "GenSigEnvVarType" SG_ 1138 STH_Waermeeintrag 1;
BA_ "GenSigSendType" SG_ 1138 STH_Waermeeintrag 7;
BA_ "NWM-WakeupAllowed" SG_ 1138 STH_Waermeeintrag 0;
BA_ "NMH-WakeupAllowed" SG_ 1138 STH_Waermeeintrag 0;
BA_ "GenSigTimeoutMsg_Motor_MED9_B8" SG_ 1138 STH_Waermeeintrag 1138;
BA_ "GenSigAutoGenDsp" SG_ 1138 STH_war_aktiv 1;
BA_ "GenSigAutoGenSnd" SG_ 1138 STH_war_aktiv 1;
BA_ "GenSigEnvVarType" SG_ 1138 STH_war_aktiv 0;
BA_ "GenSigSendType" SG_ 1138 STH_war_aktiv 7;
BA_ "NWM-WakeupAllowed" SG_ 1138 STH_war_aktiv 0;
BA_ "NMH-WakeupAllowed" SG_ 1138 STH_war_aktiv 0;
BA_ "GenSigTimeoutMsg_Motor_MED9_B8" SG_ 1138 STH_war_aktiv 1138;
BA_ "GenSigAutoGenDsp" SG_ 1138 Licht_hinten_01_BZ 1;
BA_ "GenSigAutoGenSnd" SG_ 1138 Licht_hinten_01_BZ 1;
BA_ "GenSigEnvVarType" SG_ 1138 Licht_hinten_01_BZ 0;
BA_ "GenSigSendType" SG_ 1138 Licht_hinten_01_BZ 7;
BA_ "NWM-WakeupAllowed" SG_ 1138 Licht_hinten_01_BZ 0;
BA_ "NMH-WakeupAllowed" SG_ 1138 Licht_hinten_01_BZ 0;
BA_ "GenSigTimeoutMsg_Motor_MED9_B8" SG_ 1138 Licht_hinten_01_BZ 1138;
BA_ "GenSigAutoGenDsp" SG_ 1138 BCM2_Bremsl_durch_ECD 1;
BA_ "GenSigAutoGenSnd" SG_ 1138 BCM2_Bremsl_durch_ECD 1;
BA_ "GenSigEnvVarType" SG_ 1138 BCM2_Bremsl_durch_ECD 0;
BA_ "GenSigSendType" SG_ 1138 BCM2_Bremsl_durch_ECD 7;
BA_ "NWM-WakeupAllowed" SG_ 1138 BCM2_Bremsl_durch_ECD 0;
BA_ "NMH-WakeupAllowed" SG_ 1138 BCM2_Bremsl_durch_ECD 0;
BA_ "GenSigTimeoutMsg_Motor_MED9_B8" SG_ 1138 BCM2_Bremsl_durch_ECD 1138;
BA_ "GenSigAutoGenDsp" SG_ 1138 LH_3_Bremsl_def 1;
BA_ "GenSigAutoGenSnd" SG_ 1138 LH_3_Bremsl_def 1;
BA_ "GenSigEnvVarType" SG_ 1138 LH_3_Bremsl_def 0;
BA_ "GenSigSendType" SG_ 1138 LH_3_Bremsl_def 7;
BA_ "NWM-WakeupAllowed" SG_ 1138 LH_3_Bremsl_def 0;
BA_ "NMH-WakeupAllowed" SG_ 1138 LH_3_Bremsl_def 0;
BA_ "GenSigTimeoutMsg_Motor_MED9_B8" SG_ 1138 LH_3_Bremsl_def 1138;
BA_ "GenSigAutoGenDsp" SG_ 1138 LH_Bremsl_li_ges_def 1;
BA_ "GenSigAutoGenSnd" SG_ 1138 LH_Bremsl_li_ges_def 1;
BA_ "GenSigEnvVarType" SG_ 1138 LH_Bremsl_li_ges_def 0;
BA_ "GenSigSendType" SG_ 1138 LH_Bremsl_li_ges_def 7;
BA_ "NWM-WakeupAllowed" SG_ 1138 LH_Bremsl_li_ges_def 0;
BA_ "NMH-WakeupAllowed" SG_ 1138 LH_Bremsl_li_ges_def 0;
BA_ "GenSigTimeoutMsg_Motor_MED9_B8" SG_ 1138 LH_Bremsl_li_ges_def 1138;
BA_ "GenSigAutoGenDsp" SG_ 1138 LH_Bremsl_re_ges_def 1;
BA_ "GenSigAutoGenSnd" SG_ 1138 LH_Bremsl_re_ges_def 1;
BA_ "GenSigSendType" SG_ 1138 LH_Bremsl_re_ges_def 7;
BA_ "NWM-WakeupAllowed" SG_ 1138 LH_Bremsl_re_ges_def 0;
BA_ "NMH-WakeupAllowed" SG_ 1138 LH_Bremsl_re_ges_def 0;
BA_ "GenSigTimeoutMsg_Motor_MED9_B8" SG_ 1138 LH_Bremsl_re_ges_def 1138;
BA_ "GenSigAutoGenDsp" SG_ 130 Getriebe_01_CHK 1;
BA_ "GenSigAutoGenSnd" SG_ 130 Getriebe_01_CHK 1;
BA_ "GenSigEnvVarType" SG_ 130 Getriebe_01_CHK 0;
BA_ "GenSigSendType" SG_ 130 Getriebe_01_CHK 7;
BA_ "NWM-WakeupAllowed" SG_ 130 Getriebe_01_CHK 0;
BA_ "NMH-WakeupAllowed" SG_ 130 Getriebe_01_CHK 0;
BA_ "GenSigTimeoutMsg_Gateway_B8" SG_ 130 Getriebe_01_CHK 130;
BA_ "GenSigTimeoutMsg_Motor_EDC17_003" SG_ 130 Getriebe_01_CHK 130;
BA_ "GenSigTimeoutMsg_Motor_EDC17_004" SG_ 130 Getriebe_01_CHK 130;
BA_ "GenSigTimeoutMsg_Motor_MED17_B8" SG_ 130 Getriebe_01_CHK 130;
BA_ "GenSigTimeoutMsg_Motor_MED9_B8" SG_ 130 Getriebe_01_CHK 130;
BA_ "GenSigTimeoutMsg_Motor_SIMOS8_B8" SG_ 130 Getriebe_01_CHK 130;
BA_ "GenSigAutoGenDsp" SG_ 130 Getriebe_01_BZ 1;
BA_ "GenSigAutoGenSnd" SG_ 130 Getriebe_01_BZ 1;
BA_ "GenSigEnvVarType" SG_ 130 Getriebe_01_BZ 0;
BA_ "GenSigSendType" SG_ 130 Getriebe_01_BZ 7;
BA_ "NWM-WakeupAllowed" SG_ 130 Getriebe_01_BZ 0;
BA_ "NMH-WakeupAllowed" SG_ 130 Getriebe_01_BZ 0;
BA_ "GenSigTimeoutMsg_Gateway_B8" SG_ 130 Getriebe_01_BZ 130;
BA_ "GenSigTimeoutMsg_Motor_EDC17_003" SG_ 130 Getriebe_01_BZ 130;
BA_ "GenSigTimeoutMsg_Motor_EDC17_004" SG_ 130 Getriebe_01_BZ 130;
BA_ "GenSigTimeoutMsg_Motor_MED17_B8" SG_ 130 Getriebe_01_BZ 130;
BA_ "GenSigTimeoutMsg_Motor_MED9_B8" SG_ 130 Getriebe_01_BZ 130;
BA_ "GenSigTimeoutMsg_Motor_SIMOS8_B8" SG_ 130 Getriebe_01_BZ 130;
BA_ "GenSigAutoGenDsp" SG_ 130 GE_Schaltvorgang 1;
BA_ "GenSigAutoGenSnd" SG_ 130 GE_Schaltvorgang 1;
BA_ "GenSigEnvVarType" SG_ 130 GE_Schaltvorgang 0;
BA_ "GenSigSendType" SG_ 130 GE_Schaltvorgang 7;
BA_ "NWM-WakeupAllowed" SG_ 130 GE_Schaltvorgang 0;
BA_ "NMH-WakeupAllowed" SG_ 130 GE_Schaltvorgang 0;
BA_ "GenSigTimeoutMsg_Gateway_B8" SG_ 130 GE_Schaltvorgang 130;
BA_ "GenSigTimeoutMsg_Motor_EDC17_003" SG_ 130 GE_Schaltvorgang 130;
BA_ "GenSigTimeoutMsg_Motor_EDC17_004" SG_ 130 GE_Schaltvorgang 130;
BA_ "GenSigTimeoutMsg_Motor_MED17_B8" SG_ 130 GE_Schaltvorgang 130;
BA_ "GenSigTimeoutMsg_Motor_MED9_B8" SG_ 130 GE_Schaltvorgang 130;
BA_ "GenSigTimeoutMsg_Motor_SIMOS8_B8" SG_ 130 GE_Schaltvorgang 130;
BA_ "GenSigAutoGenDsp" SG_ 130 GE_Status_Kupplung 1;
BA_ "GenSigAutoGenSnd" SG_ 130 GE_Status_Kupplung 1;
BA_ "GenSigEnvVarType" SG_ 130 GE_Status_Kupplung 0;
BA_ "GenSigSendType" SG_ 130 GE_Status_Kupplung 7;
BA_ "NWM-WakeupAllowed" SG_ 130 GE_Status_Kupplung 0;
BA_ "NMH-WakeupAllowed" SG_ 130 GE_Status_Kupplung 0;
BA_ "GenSigTimeoutMsg_Gateway_B8" SG_ 130 GE_Status_Kupplung 130;
BA_ "GenSigTimeoutMsg_Motor_EDC17_003" SG_ 130 GE_Status_Kupplung 130;
BA_ "GenSigTimeoutMsg_Motor_EDC17_004" SG_ 130 GE_Status_Kupplung 130;
BA_ "GenSigTimeoutMsg_Motor_MED17_B8" SG_ 130 GE_Status_Kupplung 130;
BA_ "GenSigTimeoutMsg_Motor_MED9_B8" SG_ 130 GE_Status_Kupplung 130;
BA_ "GenSigTimeoutMsg_Motor_SIMOS8_B8" SG_ 130 GE_Status_Kupplung 130;
BA_ "GenSigAutoGenDsp" SG_ 130 GE_MMom_Soll 1;
BA_ "GenSigAutoGenSnd" SG_ 130 GE_MMom_Soll 1;
BA_ "GenSigEnvVarType" SG_ 130 GE_MMom_Soll 1;
BA_ "GenSigSendType" SG_ 130 GE_MMom_Soll 7;
BA_ "GenSigStartValue" SG_ 130 GE_MMom_Soll 1022;
BA_ "NWM-WakeupAllowed" SG_ 130 GE_MMom_Soll 0;
BA_ "NMH-WakeupAllowed" SG_ 130 GE_MMom_Soll 0;
BA_ "GenSigTimeoutMsg_Gateway_B8" SG_ 130 GE_MMom_Soll 130;
BA_ "GenSigTimeoutMsg_Motor_EDC17_003" SG_ 130 GE_MMom_Soll 130;
BA_ "GenSigTimeoutMsg_Motor_EDC17_004" SG_ 130 GE_MMom_Soll 130;
BA_ "GenSigTimeoutMsg_Motor_MED17_B8" SG_ 130 GE_MMom_Soll 130;
BA_ "GenSigTimeoutMsg_Motor_MED9_B8" SG_ 130 GE_MMom_Soll 130;
BA_ "GenSigTimeoutMsg_Motor_SIMOS8_B8" SG_ 130 GE_MMom_Soll 130;
BA_ "GenSigAutoGenDsp" SG_ 130 GE_MMom_Status 1;
BA_ "GenSigAutoGenSnd" SG_ 130 GE_MMom_Status 1;
BA_ "GenSigEnvVarType" SG_ 130 GE_MMom_Status 0;
BA_ "GenSigSendType" SG_ 130 GE_MMom_Status 7;
BA_ "NWM-WakeupAllowed" SG_ 130 GE_MMom_Status 0;
BA_ "NMH-WakeupAllowed" SG_ 130 GE_MMom_Status 0;
BA_ "GenSigTimeoutMsg_Gateway_B8" SG_ 130 GE_MMom_Status 130;
BA_ "GenSigTimeoutMsg_Motor_EDC17_003" SG_ 130 GE_MMom_Status 130;
BA_ "GenSigTimeoutMsg_Motor_EDC17_004" SG_ 130 GE_MMom_Status 130;
BA_ "GenSigTimeoutMsg_Motor_MED17_B8" SG_ 130 GE_MMom_Status 130;
BA_ "GenSigTimeoutMsg_Motor_MED9_B8" SG_ 130 GE_MMom_Status 130;
BA_ "GenSigTimeoutMsg_Motor_SIMOS8_B8" SG_ 130 GE_MMom_Status 130;
BA_ "GenSigAutoGenDsp" SG_ 130 GE_Freig_Mmom_Soll 1;
BA_ "GenSigAutoGenSnd" SG_ 130 GE_Freig_Mmom_Soll 1;
BA_ "GenSigEnvVarType" SG_ 130 GE_Freig_Mmom_Soll 0;
BA_ "GenSigSendType" SG_ 130 GE_Freig_Mmom_Soll 7;
BA_ "NWM-WakeupAllowed" SG_ 130 GE_Freig_Mmom_Soll 0;
BA_ "NMH-WakeupAllowed" SG_ 130 GE_Freig_Mmom_Soll 0;
BA_ "GenSigTimeoutMsg_Gateway_B8" SG_ 130 GE_Freig_Mmom_Soll 130;
BA_ "GenSigAutoGenDsp" SG_ 130 GE_Status_Schaltablauf 1;
BA_ "GenSigAutoGenSnd" SG_ 130 GE_Status_Schaltablauf 1;
BA_ "GenSigEnvVarType" SG_ 130 GE_Status_Schaltablauf 0;
BA_ "GenSigSendType" SG_ 130 GE_Status_Schaltablauf 7;
BA_ "NWM-WakeupAllowed" SG_ 130 GE_Status_Schaltablauf 0;
BA_ "NMH-WakeupAllowed" SG_ 130 GE_Status_Schaltablauf 0;
BA_ "GenSigTimeoutMsg_Gateway_B8" SG_ 130 GE_Status_Schaltablauf 130;
BA_ "GenSigTimeoutMsg_Motor_EDC17_003" SG_ 130 GE_Status_Schaltablauf 130;
BA_ "GenSigTimeoutMsg_Motor_EDC17_004" SG_ 130 GE_Status_Schaltablauf 130;
BA_ "GenSigTimeoutMsg_Motor_MED17_B8" SG_ 130 GE_Status_Schaltablauf 130;
BA_ "GenSigTimeoutMsg_Motor_MED9_B8" SG_ 130 GE_Status_Schaltablauf 130;
BA_ "GenSigTimeoutMsg_Motor_SIMOS8_B8" SG_ 130 GE_Status_Schaltablauf 130;
BA_ "GenSigAutoGenDsp" SG_ 130 GE_Zeit_MZP 1;
BA_ "GenSigAutoGenSnd" SG_ 130 GE_Zeit_MZP 1;
BA_ "GenSigEnvVarType" SG_ 130 GE_Zeit_MZP 0;
BA_ "GenSigSendType" SG_ 130 GE_Zeit_MZP 7;
BA_ "NWM-WakeupAllowed" SG_ 130 GE_Zeit_MZP 0;
BA_ "NMH-WakeupAllowed" SG_ 130 GE_Zeit_MZP 0;
BA_ "GenSigTimeoutMsg_Gateway_B8" SG_ 130 GE_Zeit_MZP 130;
BA_ "GenSigTimeoutMsg_Motor_EDC17_003" SG_ 130 GE_Zeit_MZP 130;
BA_ "GenSigTimeoutMsg_Motor_EDC17_004" SG_ 130 GE_Zeit_MZP 130;
BA_ "GenSigTimeoutMsg_Motor_MED17_B8" SG_ 130 GE_Zeit_MZP 130;
BA_ "GenSigTimeoutMsg_Motor_MED9_B8" SG_ 130 GE_Zeit_MZP 130;
BA_ "GenSigTimeoutMsg_Motor_SIMOS8_B8" SG_ 130 GE_Zeit_MZP 130;
BA_ "GenSigAutoGenDsp" SG_ 130 GE_Mom_MZP 1;
BA_ "GenSigAutoGenSnd" SG_ 130 GE_Mom_MZP 1;
BA_ "GenSigEnvVarType" SG_ 130 GE_Mom_MZP 1;
BA_ "GenSigSendType" SG_ 130 GE_Mom_MZP 7;
BA_ "GenSigStartValue" SG_ 130 GE_Mom_MZP 1022;
BA_ "NWM-WakeupAllowed" SG_ 130 GE_Mom_MZP 0;
BA_ "NMH-WakeupAllowed" SG_ 130 GE_Mom_MZP 0;
BA_ "GenSigTimeoutMsg_Gateway_B8" SG_ 130 GE_Mom_MZP 130;
BA_ "GenSigTimeoutMsg_Motor_EDC17_003" SG_ 130 GE_Mom_MZP 130;
BA_ "GenSigTimeoutMsg_Motor_EDC17_004" SG_ 130 GE_Mom_MZP 130;
BA_ "GenSigTimeoutMsg_Motor_MED17_B8" SG_ 130 GE_Mom_MZP 130;
BA_ "GenSigTimeoutMsg_Motor_MED9_B8" SG_ 130 GE_Mom_MZP 130;
BA_ "GenSigTimeoutMsg_Motor_SIMOS8_B8" SG_ 130 GE_Mom_MZP 130;
BA_ "GenSigAutoGenDsp" SG_ 130 GE_Freig_Mom_Eingriff 1;
BA_ "GenSigAutoGenSnd" SG_ 130 GE_Freig_Mom_Eingriff 1;
BA_ "GenSigEnvVarType" SG_ 130 GE_Freig_Mom_Eingriff 0;
BA_ "GenSigSendType" SG_ 130 GE_Freig_Mom_Eingriff 7;
BA_ "NWM-WakeupAllowed" SG_ 130 GE_Freig_Mom_Eingriff 0;
BA_ "NMH-WakeupAllowed" SG_ 130 GE_Freig_Mom_Eingriff 0;
BA_ "GenSigTimeoutMsg_Gateway_B8" SG_ 130 GE_Freig_Mom_Eingriff 130;
BA_ "GenSigTimeoutMsg_Motor_EDC17_003" SG_ 130 GE_Freig_Mom_Eingriff 130;
BA_ "GenSigTimeoutMsg_Motor_EDC17_004" SG_ 130 GE_Freig_Mom_Eingriff 130;
BA_ "GenSigTimeoutMsg_Motor_MED17_B8" SG_ 130 GE_Freig_Mom_Eingriff 130;
BA_ "GenSigTimeoutMsg_Motor_MED9_B8" SG_ 130 GE_Freig_Mom_Eingriff 130;
BA_ "GenSigTimeoutMsg_Motor_SIMOS8_B8" SG_ 130 GE_Freig_Mom_Eingriff 130;
BA_ "GenSigAutoGenDsp" SG_ 130 GE_Mom_Ident 1;
BA_ "GenSigAutoGenSnd" SG_ 130 GE_Mom_Ident 1;
BA_ "GenSigEnvVarType" SG_ 130 GE_Mom_Ident 0;
BA_ "GenSigSendType" SG_ 130 GE_Mom_Ident 7;
BA_ "NWM-WakeupAllowed" SG_ 130 GE_Mom_Ident 0;
BA_ "NMH-WakeupAllowed" SG_ 130 GE_Mom_Ident 0;
BA_ "GenSigTimeoutMsg_Gateway_B8" SG_ 130 GE_Mom_Ident 130;
BA_ "GenSigTimeoutMsg_Motor_EDC17_003" SG_ 130 GE_Mom_Ident 130;
BA_ "GenSigTimeoutMsg_Motor_EDC17_004" SG_ 130 GE_Mom_Ident 130;
BA_ "GenSigTimeoutMsg_Motor_MED17_B8" SG_ 130 GE_Mom_Ident 130;
BA_ "GenSigTimeoutMsg_Motor_MED9_B8" SG_ 130 GE_Mom_Ident 130;
BA_ "GenSigTimeoutMsg_Motor_SIMOS8_B8" SG_ 130 GE_Mom_Ident 130;
BA_ "GenSigAutoGenDsp" SG_ 130 GE_KD_Fehler 1;
BA_ "GenSigAutoGenSnd" SG_ 130 GE_KD_Fehler 1;
BA_ "GenSigEnvVarType" SG_ 130 GE_KD_Fehler 0;
BA_ "GenSigSendType" SG_ 130 GE_KD_Fehler 7;
BA_ "NWM-WakeupAllowed" SG_ 130 GE_KD_Fehler 0;
BA_ "NMH-WakeupAllowed" SG_ 130 GE_KD_Fehler 0;
BA_ "GenSigTimeoutMsg_Gateway_B8" SG_ 130 GE_KD_Fehler 130;
BA_ "GenSigAutoGenDsp" SG_ 131 Getriebe_02_CHK 1;
BA_ "GenSigAutoGenSnd" SG_ 131 Getriebe_02_CHK 1;
BA_ "GenSigEnvVarType" SG_ 131 Getriebe_02_CHK 0;
BA_ "GenSigSendType" SG_ 131 Getriebe_02_CHK 7;
BA_ "NWM-WakeupAllowed" SG_ 131 Getriebe_02_CHK 0;
BA_ "NMH-WakeupAllowed" SG_ 131 Getriebe_02_CHK 0;
BA_ "GenSigTimeoutMsg_Motor_EDC17_003" SG_ 131 Getriebe_02_CHK 131;
BA_ "GenSigTimeoutMsg_Motor_EDC17_004" SG_ 131 Getriebe_02_CHK 131;
BA_ "GenSigTimeoutMsg_Motor_MED17_B8" SG_ 131 Getriebe_02_CHK 131;
BA_ "GenSigTimeoutMsg_Motor_MED9_B8" SG_ 131 Getriebe_02_CHK 131;
BA_ "GenSigTimeoutMsg_Motor_SIMOS8_B8" SG_ 131 Getriebe_02_CHK 131;
BA_ "GenSigAutoGenDsp" SG_ 131 Getriebe_02_BZ 1;
BA_ "GenSigAutoGenSnd" SG_ 131 Getriebe_02_BZ 1;
BA_ "GenSigEnvVarType" SG_ 131 Getriebe_02_BZ 0;
BA_ "GenSigSendType" SG_ 131 Getriebe_02_BZ 7;
BA_ "NWM-WakeupAllowed" SG_ 131 Getriebe_02_BZ 0;
BA_ "NMH-WakeupAllowed" SG_ 131 Getriebe_02_BZ 0;
BA_ "GenSigTimeoutMsg_Motor_EDC17_003" SG_ 131 Getriebe_02_BZ 131;
BA_ "GenSigTimeoutMsg_Motor_EDC17_004" SG_ 131 Getriebe_02_BZ 131;
BA_ "GenSigTimeoutMsg_Motor_MED17_B8" SG_ 131 Getriebe_02_BZ 131;
BA_ "GenSigTimeoutMsg_Motor_MED9_B8" SG_ 131 Getriebe_02_BZ 131;
BA_ "GenSigTimeoutMsg_Motor_SIMOS8_B8" SG_ 131 Getriebe_02_BZ 131;
BA_ "GenSigAutoGenDsp" SG_ 131 GE_Synchro_Wunschdrehz 1;
BA_ "GenSigAutoGenSnd" SG_ 131 GE_Synchro_Wunschdrehz 1;
BA_ "GenSigEnvVarType" SG_ 131 GE_Synchro_Wunschdrehz 1;
BA_ "GenSigSendType" SG_ 131 GE_Synchro_Wunschdrehz 7;
BA_ "NWM-WakeupAllowed" SG_ 131 GE_Synchro_Wunschdrehz 0;
BA_ "NMH-WakeupAllowed" SG_ 131 GE_Synchro_Wunschdrehz 0;
BA_ "GenSigTimeoutMsg_Motor_EDC17_003" SG_ 131 GE_Synchro_Wunschdrehz 131;
BA_ "GenSigTimeoutMsg_Motor_EDC17_004" SG_ 131 GE_Synchro_Wunschdrehz 131;
BA_ "GenSigTimeoutMsg_Motor_MED17_B8" SG_ 131 GE_Synchro_Wunschdrehz 131;
BA_ "GenSigTimeoutMsg_Motor_MED9_B8" SG_ 131 GE_Synchro_Wunschdrehz 131;
BA_ "GenSigTimeoutMsg_Motor_SIMOS8_B8" SG_ 131 GE_Synchro_Wunschdrehz 131;
BA_ "GenSigAutoGenDsp" SG_ 131 GE_Synchro_Zeit 1;
BA_ "GenSigAutoGenSnd" SG_ 131 GE_Synchro_Zeit 1;
BA_ "GenSigEnvVarType" SG_ 131 GE_Synchro_Zeit 0;
BA_ "GenSigSendType" SG_ 131 GE_Synchro_Zeit 7;
BA_ "NWM-WakeupAllowed" SG_ 131 GE_Synchro_Zeit 0;
BA_ "NMH-WakeupAllowed" SG_ 131 GE_Synchro_Zeit 0;
BA_ "GenSigTimeoutMsg_Motor_EDC17_003" SG_ 131 GE_Synchro_Zeit 131;
BA_ "GenSigTimeoutMsg_Motor_EDC17_004" SG_ 131 GE_Synchro_Zeit 131;
BA_ "GenSigTimeoutMsg_Motor_MED17_B8" SG_ 131 GE_Synchro_Zeit 131;
BA_ "GenSigTimeoutMsg_Motor_MED9_B8" SG_ 131 GE_Synchro_Zeit 131;
BA_ "GenSigTimeoutMsg_Motor_SIMOS8_B8" SG_ 131 GE_Synchro_Zeit 131;
BA_ "GenSigAutoGenDsp" SG_ 131 GE_Mom_Begr_Gradient 1;
BA_ "GenSigAutoGenSnd" SG_ 131 GE_Mom_Begr_Gradient 1;
BA_ "GenSigEnvVarType" SG_ 131 GE_Mom_Begr_Gradient 0;
BA_ "GenSigSendType" SG_ 131 GE_Mom_Begr_Gradient 7;
BA_ "GenSigStartValue" SG_ 131 GE_Mom_Begr_Gradient 255;
BA_ "NWM-WakeupAllowed" SG_ 131 GE_Mom_Begr_Gradient 0;
BA_ "NMH-WakeupAllowed" SG_ 131 GE_Mom_Begr_Gradient 0;
BA_ "GenSigTimeoutMsg_Motor_EDC17_003" SG_ 131 GE_Mom_Begr_Gradient 131;
BA_ "GenSigTimeoutMsg_Motor_EDC17_004" SG_ 131 GE_Mom_Begr_Gradient 131;
BA_ "GenSigTimeoutMsg_Motor_MED17_B8" SG_ 131 GE_Mom_Begr_Gradient 131;
BA_ "GenSigTimeoutMsg_Motor_MED9_B8" SG_ 131 GE_Mom_Begr_Gradient 131;
BA_ "GenSigTimeoutMsg_Motor_SIMOS8_B8" SG_ 131 GE_Mom_Begr_Gradient 131;
BA_ "GenSigAutoGenDsp" SG_ 131 GE_Anheb_Solldrehz_Leerlauf 1;
BA_ "GenSigAutoGenSnd" SG_ 131 GE_Anheb_Solldrehz_Leerlauf 1;
BA_ "GenSigEnvVarType" SG_ 131 GE_Anheb_Solldrehz_Leerlauf 0;
BA_ "GenSigSendType" SG_ 131 GE_Anheb_Solldrehz_Leerlauf 7;
BA_ "NWM-WakeupAllowed" SG_ 131 GE_Anheb_Solldrehz_Leerlauf 0;
BA_ "NMH-WakeupAllowed" SG_ 131 GE_Anheb_Solldrehz_Leerlauf 0;
BA_ "GenSigTimeoutMsg_Motor_EDC17_003" SG_ 131 GE_Anheb_Solldrehz_Leerlauf 131;
BA_ "GenSigTimeoutMsg_Motor_EDC17_004" SG_ 131 GE_Anheb_Solldrehz_Leerlauf 131;
BA_ "GenSigTimeoutMsg_Motor_MED17_B8" SG_ 131 GE_Anheb_Solldrehz_Leerlauf 131;
BA_ "GenSigTimeoutMsg_Motor_MED9_B8" SG_ 131 GE_Anheb_Solldrehz_Leerlauf 131;
BA_ "GenSigTimeoutMsg_Motor_SIMOS8_B8" SG_ 131 GE_Anheb_Solldrehz_Leerlauf 131;
BA_ "GenSigAutoGenDsp" SG_ 131 GE_Vorsteuermoment 1;
BA_ "GenSigAutoGenSnd" SG_ 131 GE_Vorsteuermoment 1;
BA_ "GenSigEnvVarType" SG_ 131 GE_Vorsteuermoment 1;
BA_ "GenSigSendType" SG_ 131 GE_Vorsteuermoment 7;
BA_ "GenSigStartValue" SG_ 131 GE_Vorsteuermoment 510;
BA_ "NWM-WakeupAllowed" SG_ 131 GE_Vorsteuermoment 0;
BA_ "NMH-WakeupAllowed" SG_ 131 GE_Vorsteuermoment 0;
BA_ "GenSigTimeoutMsg_Motor_EDC17_003" SG_ 131 GE_Vorsteuermoment 131;
BA_ "GenSigTimeoutMsg_Motor_EDC17_004" SG_ 131 GE_Vorsteuermoment 131;
BA_ "GenSigTimeoutMsg_Motor_MED17_B8" SG_ 131 GE_Vorsteuermoment 131;
BA_ "GenSigTimeoutMsg_Motor_MED9_B8" SG_ 131 GE_Vorsteuermoment 131;
BA_ "GenSigTimeoutMsg_Motor_SIMOS8_B8" SG_ 131 GE_Vorsteuermoment 131;
BA_ "GenSigAutoGenDsp" SG_ 131 GE_Drehzahlmesser_Daempfung 1;
BA_ "GenSigAutoGenSnd" SG_ 131 GE_Drehzahlmesser_Daempfung 1;
BA_ "GenSigSendType" SG_ 131 GE_Drehzahlmesser_Daempfung 7;
BA_ "NWM-WakeupAllowed" SG_ 131 GE_Drehzahlmesser_Daempfung 0;
BA_ "NMH-WakeupAllowed" SG_ 131 GE_Drehzahlmesser_Daempfung 0;
BA_ "GenSigTimeoutMsg_Motor_EDC17_003" SG_ 131 GE_Drehzahlmesser_Daempfung 131;
BA_ "GenSigTimeoutMsg_Motor_EDC17_004" SG_ 131 GE_Drehzahlmesser_Daempfung 131;
BA_ "GenSigTimeoutMsg_Motor_MED17_B8" SG_ 131 GE_Drehzahlmesser_Daempfung 131;
BA_ "GenSigTimeoutMsg_Motor_MED9_B8" SG_ 131 GE_Drehzahlmesser_Daempfung 131;
BA_ "GenSigTimeoutMsg_Motor_SIMOS8_B8" SG_ 131 GE_Drehzahlmesser_Daempfung 131;
BA_ "GenSigAutoGenDsp" SG_ 131 GE_Schubabschalt_Unt 1;
BA_ "GenSigAutoGenSnd" SG_ 131 GE_Schubabschalt_Unt 1;
BA_ "GenSigEnvVarType" SG_ 131 GE_Schubabschalt_Unt 0;
BA_ "GenSigSendType" SG_ 131 GE_Schubabschalt_Unt 7;
BA_ "NWM-WakeupAllowed" SG_ 131 GE_Schubabschalt_Unt 0;
BA_ "NMH-WakeupAllowed" SG_ 131 GE_Schubabschalt_Unt 0;
BA_ "GenSigTimeoutMsg_Motor_EDC17_003" SG_ 131 GE_Schubabschalt_Unt 131;
BA_ "GenSigTimeoutMsg_Motor_EDC17_004" SG_ 131 GE_Schubabschalt_Unt 131;
BA_ "GenSigTimeoutMsg_Motor_MED17_B8" SG_ 131 GE_Schubabschalt_Unt 131;
BA_ "GenSigTimeoutMsg_Motor_MED9_B8" SG_ 131 GE_Schubabschalt_Unt 131;
BA_ "GenSigTimeoutMsg_Motor_SIMOS8_B8" SG_ 131 GE_Schubabschalt_Unt 131;
BA_ "GenSigAutoGenDsp" SG_ 131 GE_Freigabe_Synchro 1;
BA_ "GenSigAutoGenSnd" SG_ 131 GE_Freigabe_Synchro 1;
BA_ "GenSigEnvVarType" SG_ 131 GE_Freigabe_Synchro 0;
BA_ "GenSigSendType" SG_ 131 GE_Freigabe_Synchro 7;
BA_ "NWM-WakeupAllowed" SG_ 131 GE_Freigabe_Synchro 0;
BA_ "NMH-WakeupAllowed" SG_ 131 GE_Freigabe_Synchro 0;
BA_ "GenSigTimeoutMsg_Motor_EDC17_003" SG_ 131 GE_Freigabe_Synchro 131;
BA_ "GenSigTimeoutMsg_Motor_EDC17_004" SG_ 131 GE_Freigabe_Synchro 131;
BA_ "GenSigTimeoutMsg_Motor_MED17_B8" SG_ 131 GE_Freigabe_Synchro 131;
BA_ "GenSigTimeoutMsg_Motor_MED9_B8" SG_ 131 GE_Freigabe_Synchro 131;
BA_ "GenSigTimeoutMsg_Motor_SIMOS8_B8" SG_ 131 GE_Freigabe_Synchro 131;
BA_ "GenSigAutoGenDsp" SG_ 258 Getriebe_03_CHK 1;
BA_ "GenSigAutoGenSnd" SG_ 258 Getriebe_03_CHK 1;
BA_ "GenSigEnvVarType" SG_ 258 Getriebe_03_CHK 0;
BA_ "GenSigSendType" SG_ 258 Getriebe_03_CHK 7;
BA_ "NWM-WakeupAllowed" SG_ 258 Getriebe_03_CHK 0;
BA_ "NMH-WakeupAllowed" SG_ 258 Getriebe_03_CHK 0;
BA_ "GenSigTimeoutMsg_Gateway_B8" SG_ 258 Getriebe_03_CHK 258;
BA_ "GenSigTimeoutMsg_Motor_EDC17_003" SG_ 258 Getriebe_03_CHK 258;
BA_ "GenSigTimeoutMsg_Motor_EDC17_004" SG_ 258 Getriebe_03_CHK 258;
BA_ "GenSigTimeoutMsg_Motor_MED17_B8" SG_ 258 Getriebe_03_CHK 258;
BA_ "GenSigTimeoutMsg_Motor_MED9_B8" SG_ 258 Getriebe_03_CHK 258;
BA_ "GenSigTimeoutMsg_Motor_SIMOS8_B8" SG_ 258 Getriebe_03_CHK 258;
BA_ "GenSigAutoGenDsp" SG_ 258 Getriebe_03_BZ 1;
BA_ "GenSigAutoGenSnd" SG_ 258 Getriebe_03_BZ 1;
BA_ "GenSigEnvVarType" SG_ 258 Getriebe_03_BZ 0;
BA_ "GenSigSendType" SG_ 258 Getriebe_03_BZ 7;
BA_ "NWM-WakeupAllowed" SG_ 258 Getriebe_03_BZ 0;
BA_ "NMH-WakeupAllowed" SG_ 258 Getriebe_03_BZ 0;
BA_ "GenSigTimeoutMsg_Gateway_B8" SG_ 258 Getriebe_03_BZ 258;
BA_ "GenSigTimeoutMsg_Motor_EDC17_003" SG_ 258 Getriebe_03_BZ 258;
BA_ "GenSigTimeoutMsg_Motor_EDC17_004" SG_ 258 Getriebe_03_BZ 258;
BA_ "GenSigTimeoutMsg_Motor_MED17_B8" SG_ 258 Getriebe_03_BZ 258;
BA_ "GenSigTimeoutMsg_Motor_MED9_B8" SG_ 258 Getriebe_03_BZ 258;
BA_ "GenSigTimeoutMsg_Motor_SIMOS8_B8" SG_ 258 Getriebe_03_BZ 258;
BA_ "GenSigAutoGenDsp" SG_ 258 GE_Freig_Langfr_Schutzmom 1;
BA_ "GenSigAutoGenSnd" SG_ 258 GE_Freig_Langfr_Schutzmom 1;
BA_ "GenSigEnvVarType" SG_ 258 GE_Freig_Langfr_Schutzmom 0;
BA_ "GenSigSendType" SG_ 258 GE_Freig_Langfr_Schutzmom 7;
BA_ "NWM-WakeupAllowed" SG_ 258 GE_Freig_Langfr_Schutzmom 0;
BA_ "NMH-WakeupAllowed" SG_ 258 GE_Freig_Langfr_Schutzmom 0;
BA_ "GenSigTimeoutMsg_Gateway_B8" SG_ 258 GE_Freig_Langfr_Schutzmom 258;
BA_ "GenSigTimeoutMsg_Motor_EDC17_003" SG_ 258 GE_Freig_Langfr_Schutzmom 258;
BA_ "GenSigTimeoutMsg_Motor_EDC17_004" SG_ 258 GE_Freig_Langfr_Schutzmom 258;
BA_ "GenSigTimeoutMsg_Motor_MED17_B8" SG_ 258 GE_Freig_Langfr_Schutzmom 258;
BA_ "GenSigTimeoutMsg_Motor_MED9_B8" SG_ 258 GE_Freig_Langfr_Schutzmom 258;
BA_ "GenSigTimeoutMsg_Motor_SIMOS8_B8" SG_ 258 GE_Freig_Langfr_Schutzmom 258;
BA_ "GenSigAutoGenDsp" SG_ 258 GE_Uefkt 1;
BA_ "GenSigAutoGenSnd" SG_ 258 GE_Uefkt 1;
BA_ "GenSigEnvVarType" SG_ 258 GE_Uefkt 1;
BA_ "GenSigSendType" SG_ 258 GE_Uefkt 7;
BA_ "NWM-WakeupAllowed" SG_ 258 GE_Uefkt 0;
BA_ "NMH-WakeupAllowed" SG_ 258 GE_Uefkt 0;
BA_ "GenSigTimeoutMsg_Gateway_B8" SG_ 258 GE_Uefkt 258;
BA_ "GenSigTimeoutMsg_Motor_EDC17_003" SG_ 258 GE_Uefkt 258;
BA_ "GenSigTimeoutMsg_Motor_EDC17_004" SG_ 258 GE_Uefkt 258;
BA_ "GenSigTimeoutMsg_Motor_MED17_B8" SG_ 258 GE_Uefkt 258;
BA_ "GenSigTimeoutMsg_Motor_MED9_B8" SG_ 258 GE_Uefkt 258;
BA_ "GenSigTimeoutMsg_Motor_SIMOS8_B8" SG_ 258 GE_Uefkt 258;
BA_ "GenSigAutoGenDsp" SG_ 258 GE_Zielgang 1;
BA_ "GenSigAutoGenSnd" SG_ 258 GE_Zielgang 1;
BA_ "GenSigEnvVarType" SG_ 258 GE_Zielgang 0;
BA_ "GenSigSendType" SG_ 258 GE_Zielgang 7;
BA_ "NWM-WakeupAllowed" SG_ 258 GE_Zielgang 0;
BA_ "NMH-WakeupAllowed" SG_ 258 GE_Zielgang 0;
BA_ "GenSigTimeoutMsg_Gateway_B8" SG_ 258 GE_Zielgang 258;
BA_ "GenSigTimeoutMsg_Motor_EDC17_003" SG_ 258 GE_Zielgang 258;
BA_ "GenSigTimeoutMsg_Motor_EDC17_004" SG_ 258 GE_Zielgang 258;
BA_ "GenSigTimeoutMsg_Motor_MED17_B8" SG_ 258 GE_Zielgang 258;
BA_ "GenSigTimeoutMsg_Motor_MED9_B8" SG_ 258 GE_Zielgang 258;
BA_ "GenSigTimeoutMsg_Motor_SIMOS8_B8" SG_ 258 GE_Zielgang 258;
BA_ "GenSigAutoGenDsp" SG_ 258 GE_Langfr_Schutzmom 1;
BA_ "GenSigAutoGenSnd" SG_ 258 GE_Langfr_Schutzmom 1;
BA_ "GenSigEnvVarType" SG_ 258 GE_Langfr_Schutzmom 0;
BA_ "GenSigSendType" SG_ 258 GE_Langfr_Schutzmom 7;
BA_ "GenSigStartValue" SG_ 258 GE_Langfr_Schutzmom 1022;
BA_ "NWM-WakeupAllowed" SG_ 258 GE_Langfr_Schutzmom 0;
BA_ "NMH-WakeupAllowed" SG_ 258 GE_Langfr_Schutzmom 0;
BA_ "GenSigTimeoutMsg_Gateway_B8" SG_ 258 GE_Langfr_Schutzmom 258;
BA_ "GenSigTimeoutMsg_Motor_EDC17_003" SG_ 258 GE_Langfr_Schutzmom 258;
BA_ "GenSigTimeoutMsg_Motor_EDC17_004" SG_ 258 GE_Langfr_Schutzmom 258;
BA_ "GenSigTimeoutMsg_Motor_MED17_B8" SG_ 258 GE_Langfr_Schutzmom 258;
BA_ "GenSigTimeoutMsg_Motor_MED9_B8" SG_ 258 GE_Langfr_Schutzmom 258;
BA_ "GenSigTimeoutMsg_Motor_SIMOS8_B8" SG_ 258 GE_Langfr_Schutzmom 258;
BA_ "GenSigAutoGenDsp" SG_ 258 GE_reserv_Waehlhebel 1;
BA_ "GenSigAutoGenSnd" SG_ 258 GE_reserv_Waehlhebel 1;
BA_ "GenSigSendType" SG_ 258 GE_reserv_Waehlhebel 7;
BA_ "NWM-WakeupAllowed" SG_ 258 GE_reserv_Waehlhebel 0;
BA_ "NMH-WakeupAllowed" SG_ 258 GE_reserv_Waehlhebel 0;
BA_ "GenSigTimeoutMsg_Gateway_B8" SG_ 258 GE_reserv_Waehlhebel 258;
BA_ "GenSigAutoGenDsp" SG_ 258 GE_Waehlhebel 1;
BA_ "GenSigAutoGenSnd" SG_ 258 GE_Waehlhebel 1;
BA_ "GenSigEnvVarType" SG_ 258 GE_Waehlhebel 0;
BA_ "GenSigSendType" SG_ 258 GE_Waehlhebel 7;
BA_ "GenSigStartValue" SG_ 258 GE_Waehlhebel 1;
BA_ "NWM-WakeupAllowed" SG_ 258 GE_Waehlhebel 0;
BA_ "NMH-WakeupAllowed" SG_ 258 GE_Waehlhebel 0;
BA_ "GenSigTimeoutMsg_Gateway_B8" SG_ 258 GE_Waehlhebel 258;
BA_ "GenSigTimeoutMsg_Motor_EDC17_003" SG_ 258 GE_Waehlhebel 258;
BA_ "GenSigTimeoutMsg_Motor_EDC17_004" SG_ 258 GE_Waehlhebel 258;
BA_ "GenSigTimeoutMsg_Motor_MED17_B8" SG_ 258 GE_Waehlhebel 258;
BA_ "GenSigTimeoutMsg_Motor_MED9_B8" SG_ 258 GE_Waehlhebel 258;
BA_ "GenSigTimeoutMsg_Motor_SIMOS8_B8" SG_ 258 GE_Waehlhebel 258;
BA_ "GenSigAutoGenDsp" SG_ 258 GE_Eingangsdrehz 1;
BA_ "GenSigAutoGenSnd" SG_ 258 GE_Eingangsdrehz 1;
BA_ "GenSigEnvVarType" SG_ 258 GE_Eingangsdrehz 1;
BA_ "GenSigSendType" SG_ 258 GE_Eingangsdrehz 7;
BA_ "GenSigStartValue" SG_ 258 GE_Eingangsdrehz 16382;
BA_ "NWM-WakeupAllowed" SG_ 258 GE_Eingangsdrehz 0;
BA_ "NMH-WakeupAllowed" SG_ 258 GE_Eingangsdrehz 0;
BA_ "GenSigTimeoutMsg_Gateway_B8" SG_ 258 GE_Eingangsdrehz 258;
BA_ "GenSigTimeoutMsg_Motor_EDC17_003" SG_ 258 GE_Eingangsdrehz 258;
BA_ "GenSigTimeoutMsg_Motor_EDC17_004" SG_ 258 GE_Eingangsdrehz 258;
BA_ "GenSigTimeoutMsg_Motor_MED17_B8" SG_ 258 GE_Eingangsdrehz 258;
BA_ "GenSigTimeoutMsg_Motor_MED9_B8" SG_ 258 GE_Eingangsdrehz 258;
BA_ "GenSigTimeoutMsg_Motor_SIMOS8_B8" SG_ 258 GE_Eingangsdrehz 258;
BA_ "GenSigAutoGenDsp" SG_ 258 GE_Notlauf 1;
BA_ "GenSigAutoGenSnd" SG_ 258 GE_Notlauf 1;
BA_ "GenSigEnvVarType" SG_ 258 GE_Notlauf 0;
BA_ "GenSigSendType" SG_ 258 GE_Notlauf 7;
BA_ "NWM-WakeupAllowed" SG_ 258 GE_Notlauf 0;
BA_ "NMH-WakeupAllowed" SG_ 258 GE_Notlauf 0;
BA_ "GenSigTimeoutMsg_Gateway_B8" SG_ 258 GE_Notlauf 258;
BA_ "GenSigTimeoutMsg_Motor_EDC17_003" SG_ 258 GE_Notlauf 258;
BA_ "GenSigTimeoutMsg_Motor_EDC17_004" SG_ 258 GE_Notlauf 258;
BA_ "GenSigTimeoutMsg_Motor_MED17_B8" SG_ 258 GE_Notlauf 258;
BA_ "GenSigTimeoutMsg_Motor_MED9_B8" SG_ 258 GE_Notlauf 258;
BA_ "GenSigTimeoutMsg_Motor_SIMOS8_B8" SG_ 258 GE_Notlauf 258;
BA_ "GenSigAutoGenDsp" SG_ 258 GE_Codierung_MSG 1;
BA_ "GenSigAutoGenSnd" SG_ 258 GE_Codierung_MSG 1;
BA_ "GenSigEnvVarType" SG_ 258 GE_Codierung_MSG 0;
BA_ "GenSigSendType" SG_ 258 GE_Codierung_MSG 7;
BA_ "NWM-WakeupAllowed" SG_ 258 GE_Codierung_MSG 0;
BA_ "NMH-WakeupAllowed" SG_ 258 GE_Codierung_MSG 0;
BA_ "GenSigTimeoutMsg_Gateway_B8" SG_ 258 GE_Codierung_MSG 258;
BA_ "GenSigAutoGenDsp" SG_ 1089 GE_Index_Fahrwid 1;
BA_ "GenSigAutoGenSnd" SG_ 1089 GE_Index_Fahrwid 1;
BA_ "GenSigEnvVarType" SG_ 1089 GE_Index_Fahrwid 1;
BA_ "GenSigSendType" SG_ 1089 GE_Index_Fahrwid 7;
BA_ "GenSigStartValue" SG_ 1089 GE_Index_Fahrwid 127;
BA_ "NWM-WakeupAllowed" SG_ 1089 GE_Index_Fahrwid 0;
BA_ "NMH-WakeupAllowed" SG_ 1089 GE_Index_Fahrwid 0;
BA_ "GenSigTimeoutMsg_Gateway_B8" SG_ 1089 GE_Index_Fahrwid 1089;
BA_ "GenSigTimeoutMsg_Motor_EDC17_003" SG_ 1089 GE_Index_Fahrwid 1089;
BA_ "GenSigTimeoutMsg_Motor_EDC17_004" SG_ 1089 GE_Index_Fahrwid 1089;
BA_ "GenSigTimeoutMsg_Motor_MED17_B8" SG_ 1089 GE_Index_Fahrwid 1089;
BA_ "GenSigTimeoutMsg_Motor_MED9_B8" SG_ 1089 GE_Index_Fahrwid 1089;
BA_ "GenSigTimeoutMsg_Motor_SIMOS8_B8" SG_ 1089 GE_Index_Fahrwid 1089;
BA_ "GenSigAutoGenDsp" SG_ 1089 GE_OBD_Status 1;
BA_ "GenSigAutoGenSnd" SG_ 1089 GE_OBD_Status 1;
BA_ "GenSigEnvVarType" SG_ 1089 GE_OBD_Status 0;
BA_ "GenSigSendType" SG_ 1089 GE_OBD_Status 7;
BA_ "NWM-WakeupAllowed" SG_ 1089 GE_OBD_Status 0;
BA_ "NMH-WakeupAllowed" SG_ 1089 GE_OBD_Status 0;
BA_ "GenSigTimeoutMsg_Gateway_B8" SG_ 1089 GE_OBD_Status 1089;
BA_ "GenSigTimeoutMsg_Motor_EDC17_003" SG_ 1089 GE_OBD_Status 1089;
BA_ "GenSigTimeoutMsg_Motor_EDC17_004" SG_ 1089 GE_OBD_Status 1089;
BA_ "GenSigTimeoutMsg_Motor_MED17_B8" SG_ 1089 GE_OBD_Status 1089;
BA_ "GenSigTimeoutMsg_Motor_MED9_B8" SG_ 1089 GE_OBD_Status 1089;
BA_ "GenSigTimeoutMsg_Motor_SIMOS8_B8" SG_ 1089 GE_OBD_Status 1089;
BA_ "GenSigAutoGenDsp" SG_ 1089 GE_LFR_Adaption 1;
BA_ "GenSigAutoGenSnd" SG_ 1089 GE_LFR_Adaption 1;
BA_ "GenSigEnvVarType" SG_ 1089 GE_LFR_Adaption 0;
BA_ "GenSigSendType" SG_ 1089 GE_LFR_Adaption 7;
BA_ "NWM-WakeupAllowed" SG_ 1089 GE_LFR_Adaption 0;
BA_ "NMH-WakeupAllowed" SG_ 1089 GE_LFR_Adaption 0;
BA_ "GenSigTimeoutMsg_Gateway_B8" SG_ 1089 GE_LFR_Adaption 1089;
BA_ "GenSigTimeoutMsg_Motor_EDC17_003" SG_ 1089 GE_LFR_Adaption 1089;
BA_ "GenSigTimeoutMsg_Motor_EDC17_004" SG_ 1089 GE_LFR_Adaption 1089;
BA_ "GenSigTimeoutMsg_Motor_MED17_B8" SG_ 1089 GE_LFR_Adaption 1089;
BA_ "GenSigTimeoutMsg_Motor_MED9_B8" SG_ 1089 GE_LFR_Adaption 1089;
BA_ "GenSigTimeoutMsg_Motor_SIMOS8_B8" SG_ 1089 GE_LFR_Adaption 1089;
BA_ "GenSigAutoGenDsp" SG_ 1089 GE_Grenzkriechmoment 1;
BA_ "GenSigAutoGenSnd" SG_ 1089 GE_Grenzkriechmoment 1;
BA_ "GenSigEnvVarType" SG_ 1089 GE_Grenzkriechmoment 1;
BA_ "GenSigSendType" SG_ 1089 GE_Grenzkriechmoment 7;
BA_ "GenSigStartValue" SG_ 1089 GE_Grenzkriechmoment 62;
BA_ "NWM-WakeupAllowed" SG_ 1089 GE_Grenzkriechmoment 0;
BA_ "NMH-WakeupAllowed" SG_ 1089 GE_Grenzkriechmoment 0;
BA_ "GenSigTimeoutMsg_Gateway_B8" SG_ 1089 GE_Grenzkriechmoment 1089;
BA_ "GenSigAutoGenDsp" SG_ 1089 GE_Charisma_FahrPr 1;
BA_ "GenSigAutoGenSnd" SG_ 1089 GE_Charisma_FahrPr 1;
BA_ "GenSigSendType" SG_ 1089 GE_Charisma_FahrPr 7;
BA_ "NWM-WakeupAllowed" SG_ 1089 GE_Charisma_FahrPr 0;
BA_ "NMH-WakeupAllowed" SG_ 1089 GE_Charisma_FahrPr 0;
BA_ "GenSigTimeoutMsg_Gateway_B8" SG_ 1089 GE_Charisma_FahrPr 1089;
BA_ "GenSigAutoGenDsp" SG_ 1089 GE_Charisma_Status 1;
BA_ "GenSigAutoGenSnd" SG_ 1089 GE_Charisma_Status 1;
BA_ "GenSigSendType" SG_ 1089 GE_Charisma_Status 7;
BA_ "NWM-WakeupAllowed" SG_ 1089 GE_Charisma_Status 0;
BA_ "NMH-WakeupAllowed" SG_ 1089 GE_Charisma_Status 0;
BA_ "GenSigTimeoutMsg_Gateway_B8" SG_ 1089 GE_Charisma_Status 1089;
BA_ "GenSigAutoGenDsp" SG_ 1089 GE_Charisma_Umschaltung 1;
BA_ "GenSigAutoGenSnd" SG_ 1089 GE_Charisma_Umschaltung 1;
BA_ "GenSigSendType" SG_ 1089 GE_Charisma_Umschaltung 7;
BA_ "NWM-WakeupAllowed" SG_ 1089 GE_Charisma_Umschaltung 0;
BA_ "NMH-WakeupAllowed" SG_ 1089 GE_Charisma_Umschaltung 0;
BA_ "GenSigTimeoutMsg_Gateway_B8" SG_ 1089 GE_Charisma_Umschaltung 1089;
BA_ "GenSigAutoGenDsp" SG_ 1089 GE_Verlustmoment 1;
BA_ "GenSigAutoGenSnd" SG_ 1089 GE_Verlustmoment 1;
BA_ "GenSigSendType" SG_ 1089 GE_Verlustmoment 7;
BA_ "NWM-WakeupAllowed" SG_ 1089 GE_Verlustmoment 0;
BA_ "NMH-WakeupAllowed" SG_ 1089 GE_Verlustmoment 0;
BA_ "GenSigTimeoutMsg_Gateway_B8" SG_ 1089 GE_Verlustmoment 1089;
BA_ "GenSigTimeoutMsg_Motor_EDC17_003" SG_ 1089 GE_Verlustmoment 1089;
BA_ "GenSigTimeoutMsg_Motor_EDC17_004" SG_ 1089 GE_Verlustmoment 1089;
BA_ "GenSigTimeoutMsg_Motor_MED17_B8" SG_ 1089 GE_Verlustmoment 1089;
BA_ "GenSigTimeoutMsg_Motor_MED9_B8" SG_ 1089 GE_Verlustmoment 1089;
BA_ "GenSigTimeoutMsg_Motor_SIMOS8_B8" SG_ 1089 GE_Verlustmoment 1089;
BA_ "GenSigAutoGenDsp" SG_ 1089 GE_amax_moeglich 1;
BA_ "GenSigAutoGenSnd" SG_ 1089 GE_amax_moeglich 1;
BA_ "GenSigSendType" SG_ 1089 GE_amax_moeglich 7;
BA_ "GenSigStartValue" SG_ 1089 GE_amax_moeglich 84;
BA_ "NWM-WakeupAllowed" SG_ 1089 GE_amax_moeglich 0;
BA_ "NMH-WakeupAllowed" SG_ 1089 GE_amax_moeglich 0;
BA_ "GenSigTimeoutMsg_Gateway_B8" SG_ 1089 GE_amax_moeglich 1089;
BA_ "GenSigTimeoutMsg_Motor_EDC17_003" SG_ 1089 GE_amax_moeglich 1089;
BA_ "GenSigTimeoutMsg_Motor_EDC17_004" SG_ 1089 GE_amax_moeglich 1089;
BA_ "GenSigTimeoutMsg_Motor_MED17_B8" SG_ 1089 GE_amax_moeglich 1089;
BA_ "GenSigTimeoutMsg_Motor_MED9_B8" SG_ 1089 GE_amax_moeglich 1089;
BA_ "GenSigTimeoutMsg_Motor_SIMOS8_B8" SG_ 1089 GE_amax_moeglich 1089;
BA_ "GenSigAutoGenDsp" SG_ 1089 GE_Sumpftemperatur 1;
BA_ "GenSigAutoGenSnd" SG_ 1089 GE_Sumpftemperatur 1;
BA_ "GenSigSendType" SG_ 1089 GE_Sumpftemperatur 7;
BA_ "NWM-WakeupAllowed" SG_ 1089 GE_Sumpftemperatur 0;
BA_ "NMH-WakeupAllowed" SG_ 1089 GE_Sumpftemperatur 0;
BA_ "GenSigTimeoutMsg_Gateway_B8" SG_ 1089 GE_Sumpftemperatur 1089;
BA_ "GenSigTimeoutMsg_Motor_EDC17_003" SG_ 1089 GE_Sumpftemperatur 1089;
BA_ "GenSigTimeoutMsg_Motor_EDC17_004" SG_ 1089 GE_Sumpftemperatur 1089;
BA_ "GenSigTimeoutMsg_Motor_MED17_B8" SG_ 1089 GE_Sumpftemperatur 1089;
BA_ "GenSigTimeoutMsg_Motor_MED9_B8" SG_ 1089 GE_Sumpftemperatur 1089;
BA_ "GenSigTimeoutMsg_Motor_SIMOS8_B8" SG_ 1089 GE_Sumpftemperatur 1089;
BA_ "GenSigAutoGenDsp" SG_ 1813 ISO_Airbag_01_Req_Data 1;
BA_ "GenSigAutoGenSnd" SG_ 1813 ISO_Airbag_01_Req_Data 1;
BA_ "GenSigSendType" SG_ 1813 ISO_Airbag_01_Req_Data 7;
BA_ "NWM-WakeupAllowed" SG_ 1813 ISO_Airbag_01_Req_Data 0;
BA_ "NMH-WakeupAllowed" SG_ 1813 ISO_Airbag_01_Req_Data 0;
BA_ "GenSigTimeoutMsg_Airbag_B8" SG_ 1813 ISO_Airbag_01_Req_Data 1813;
BA_ "GenSigAutoGenDsp" SG_ 1919 ISO_Airbag_01_Resp_Data 1;
BA_ "GenSigAutoGenSnd" SG_ 1919 ISO_Airbag_01_Resp_Data 1;
BA_ "GenSigSendType" SG_ 1919 ISO_Airbag_01_Resp_Data 7;
BA_ "NWM-WakeupAllowed" SG_ 1919 ISO_Airbag_01_Resp_Data 0;
BA_ "NMH-WakeupAllowed" SG_ 1919 ISO_Airbag_01_Resp_Data 0;
BA_ "GenSigTimeoutMsg_Gateway_B8" SG_ 1919 ISO_Airbag_01_Resp_Data 1919;
BA_ "GenSigAutoGenDsp" SG_ 2022 ISO_EMotor_01_Req_Data 1;
BA_ "GenSigAutoGenSnd" SG_ 2022 ISO_EMotor_01_Req_Data 1;
BA_ "GenSigSendType" SG_ 2022 ISO_EMotor_01_Req_Data 7;
BA_ "NWM-WakeupAllowed" SG_ 2022 ISO_EMotor_01_Req_Data 0;
BA_ "NMH-WakeupAllowed" SG_ 2022 ISO_EMotor_01_Req_Data 0;
BA_ "GenSigAutoGenDsp" SG_ 2030 ISO_EMotor_01_Resp_Data 1;
BA_ "GenSigAutoGenSnd" SG_ 2030 ISO_EMotor_01_Resp_Data 1;
BA_ "GenSigSendType" SG_ 2030 ISO_EMotor_01_Resp_Data 7;
BA_ "NWM-WakeupAllowed" SG_ 2030 ISO_EMotor_01_Resp_Data 0;
BA_ "NMH-WakeupAllowed" SG_ 2030 ISO_EMotor_01_Resp_Data 0;
BA_ "GenSigTimeoutMsg_Gateway_B8" SG_ 2030 ISO_EMotor_01_Resp_Data 2030;
BA_ "GenSigAutoGenDsp" SG_ 1792 ISO_ALL_01_Req_Data 1;
BA_ "GenSigAutoGenSnd" SG_ 1792 ISO_ALL_01_Req_Data 1;
BA_ "GenSigSendType" SG_ 1792 ISO_ALL_01_Req_Data 7;
BA_ "NWM-WakeupAllowed" SG_ 1792 ISO_ALL_01_Req_Data 0;
BA_ "NMH-WakeupAllowed" SG_ 1792 ISO_ALL_01_Req_Data 0;
BA_ "GenSigTimeoutMsg_Airbag_B8" SG_ 1792 ISO_ALL_01_Req_Data 1792;
BA_ "GenSigTimeoutMsg_Getriebe_AL6000" SG_ 1792 ISO_ALL_01_Req_Data 1792;
BA_ "GenSigTimeoutMsg_Getriebe_DL5001" SG_ 1792 ISO_ALL_01_Req_Data 1792;
BA_ "GenSigTimeoutMsg_Getriebe_VL3002" SG_ 1792 ISO_ALL_01_Req_Data 1792;
BA_ "GenSigTimeoutMsg_Motor_EDC17_003" SG_ 1792 ISO_ALL_01_Req_Data 1792;
BA_ "GenSigTimeoutMsg_Motor_EDC17_004" SG_ 1792 ISO_ALL_01_Req_Data 1792;
BA_ "GenSigTimeoutMsg_Motor_MED17_B8" SG_ 1792 ISO_ALL_01_Req_Data 1792;
BA_ "GenSigTimeoutMsg_Motor_MED9_B8" SG_ 1792 ISO_ALL_01_Req_Data 1792;
BA_ "GenSigTimeoutMsg_Motor_SIMOS8_B8" SG_ 1792 ISO_ALL_01_Req_Data 1792;
BA_ "GenSigTimeoutMsg_Motor_Slave_B8" SG_ 1792 ISO_ALL_01_Req_Data 1792;
BA_ "GenSigAutoGenDsp" SG_ 2015 ISO_OBD_Funktionaler_Req_Data 1;
BA_ "GenSigAutoGenSnd" SG_ 2015 ISO_OBD_Funktionaler_Req_Data 1;
BA_ "GenSigSendType" SG_ 2015 ISO_OBD_Funktionaler_Req_Data 7;
BA_ "NWM-WakeupAllowed" SG_ 2015 ISO_OBD_Funktionaler_Req_Data 0;
BA_ "NMH-WakeupAllowed" SG_ 2015 ISO_OBD_Funktionaler_Req_Data 0;
BA_ "GenSigTimeoutMsg_Airbag_B8" SG_ 2015 ISO_OBD_Funktionaler_Req_Data 2015;
BA_ "GenSigTimeoutMsg_Getriebe_AL6000" SG_ 2015 ISO_OBD_Funktionaler_Req_Data 2015;
BA_ "GenSigTimeoutMsg_Getriebe_DL5001" SG_ 2015 ISO_OBD_Funktionaler_Req_Data 2015;
BA_ "GenSigTimeoutMsg_Getriebe_VL3002" SG_ 2015 ISO_OBD_Funktionaler_Req_Data 2015;
BA_ "GenSigTimeoutMsg_Motor_EDC17_003" SG_ 2015 ISO_OBD_Funktionaler_Req_Data 2015;
BA_ "GenSigTimeoutMsg_Motor_EDC17_004" SG_ 2015 ISO_OBD_Funktionaler_Req_Data 2015;
BA_ "GenSigTimeoutMsg_Motor_MED17_B8" SG_ 2015 ISO_OBD_Funktionaler_Req_Data 2015;
BA_ "GenSigTimeoutMsg_Motor_MED9_B8" SG_ 2015 ISO_OBD_Funktionaler_Req_Data 2015;
BA_ "GenSigTimeoutMsg_Motor_SIMOS8_B8" SG_ 2015 ISO_OBD_Funktionaler_Req_Data 2015;
BA_ "GenSigTimeoutMsg_Motor_Slave_B8" SG_ 2015 ISO_OBD_Funktionaler_Req_Data 2015;
BA_ "GenSigAutoGenDsp" SG_ 2017 ISO_Getriebe_01_Req_Data 1;
BA_ "GenSigAutoGenSnd" SG_ 2017 ISO_Getriebe_01_Req_Data 1;
BA_ "GenSigSendType" SG_ 2017 ISO_Getriebe_01_Req_Data 7;
BA_ "NWM-WakeupAllowed" SG_ 2017 ISO_Getriebe_01_Req_Data 0;
BA_ "NMH-WakeupAllowed" SG_ 2017 ISO_Getriebe_01_Req_Data 0;
BA_ "GenSigTimeoutMsg_Getriebe_AL6000" SG_ 2017 ISO_Getriebe_01_Req_Data 2017;
BA_ "GenSigTimeoutMsg_Getriebe_DL5001" SG_ 2017 ISO_Getriebe_01_Req_Data 2017;
BA_ "GenSigTimeoutMsg_Getriebe_VL3002" SG_ 2017 ISO_Getriebe_01_Req_Data 2017;
BA_ "GenSigAutoGenDsp" SG_ 2025 ISO_Getriebe_01_Resp_Data 1;
BA_ "GenSigAutoGenSnd" SG_ 2025 ISO_Getriebe_01_Resp_Data 1;
BA_ "GenSigSendType" SG_ 2025 ISO_Getriebe_01_Resp_Data 7;
BA_ "NWM-WakeupAllowed" SG_ 2025 ISO_Getriebe_01_Resp_Data 0;
BA_ "NMH-WakeupAllowed" SG_ 2025 ISO_Getriebe_01_Resp_Data 0;
BA_ "GenSigTimeoutMsg_Gateway_B8" SG_ 2025 ISO_Getriebe_01_Resp_Data 2025;
BA_ "GenSigAutoGenDsp" SG_ 2021 ISO_Hybrid_01_Req_Data 1;
BA_ "GenSigAutoGenSnd" SG_ 2021 ISO_Hybrid_01_Req_Data 1;
BA_ "GenSigSendType" SG_ 2021 ISO_Hybrid_01_Req_Data 7;
BA_ "NWM-WakeupAllowed" SG_ 2021 ISO_Hybrid_01_Req_Data 0;
BA_ "NMH-WakeupAllowed" SG_ 2021 ISO_Hybrid_01_Req_Data 0;
BA_ "GenSigAutoGenDsp" SG_ 2029 ISO_Hybrid_01_Resp_Data 1;
BA_ "GenSigAutoGenSnd" SG_ 2029 ISO_Hybrid_01_Resp_Data 1;
BA_ "GenSigSendType" SG_ 2029 ISO_Hybrid_01_Resp_Data 7;
BA_ "NWM-WakeupAllowed" SG_ 2029 ISO_Hybrid_01_Resp_Data 0;
BA_ "NMH-WakeupAllowed" SG_ 2029 ISO_Hybrid_01_Resp_Data 0;
BA_ "GenSigTimeoutMsg_Gateway_B8" SG_ 2029 ISO_Hybrid_01_Resp_Data 2029;
BA_ "GenSigAutoGenDsp" SG_ 2016 ISO_MO_01_Req_Data 1;
BA_ "GenSigAutoGenSnd" SG_ 2016 ISO_MO_01_Req_Data 1;
BA_ "GenSigSendType" SG_ 2016 ISO_MO_01_Req_Data 7;
BA_ "NWM-WakeupAllowed" SG_ 2016 ISO_MO_01_Req_Data 0;
BA_ "NMH-WakeupAllowed" SG_ 2016 ISO_MO_01_Req_Data 0;
BA_ "GenSigTimeoutMsg_Motor_EDC17_003" SG_ 2016 ISO_MO_01_Req_Data 2016;
BA_ "GenSigTimeoutMsg_Motor_EDC17_004" SG_ 2016 ISO_MO_01_Req_Data 2016;
BA_ "GenSigTimeoutMsg_Motor_MED17_B8" SG_ 2016 ISO_MO_01_Req_Data 2016;
BA_ "GenSigTimeoutMsg_Motor_MED9_B8" SG_ 2016 ISO_MO_01_Req_Data 2016;
BA_ "GenSigTimeoutMsg_Motor_SIMOS8_B8" SG_ 2016 ISO_MO_01_Req_Data 2016;
BA_ "GenSigAutoGenDsp" SG_ 2024 ISO_MO_01_Resp_Data 1;
BA_ "GenSigAutoGenSnd" SG_ 2024 ISO_MO_01_Resp_Data 1;
BA_ "GenSigSendType" SG_ 2024 ISO_MO_01_Resp_Data 7;
BA_ "NWM-WakeupAllowed" SG_ 2024 ISO_MO_01_Resp_Data 0;
BA_ "NMH-WakeupAllowed" SG_ 2024 ISO_MO_01_Resp_Data 0;
BA_ "GenSigTimeoutMsg_Gateway_B8" SG_ 2024 ISO_MO_01_Resp_Data 2024;
BA_ "GenSigAutoGenDsp" SG_ 2018 ISO_MOS_01_Req_Data 1;
BA_ "GenSigAutoGenSnd" SG_ 2018 ISO_MOS_01_Req_Data 1;
BA_ "GenSigSendType" SG_ 2018 ISO_MOS_01_Req_Data 7;
BA_ "NWM-WakeupAllowed" SG_ 2018 ISO_MOS_01_Req_Data 0;
BA_ "NMH-WakeupAllowed" SG_ 2018 ISO_MOS_01_Req_Data 0;
BA_ "GenSigTimeoutMsg_Motor_Slave_B8" SG_ 2018 ISO_MOS_01_Req_Data 2018;
BA_ "GenSigAutoGenDsp" SG_ 2026 ISO_MOS_01_Resp_Data 1;
BA_ "GenSigAutoGenSnd" SG_ 2026 ISO_MOS_01_Resp_Data 1;
BA_ "GenSigSendType" SG_ 2026 ISO_MOS_01_Resp_Data 7;
BA_ "NWM-WakeupAllowed" SG_ 2026 ISO_MOS_01_Resp_Data 0;
BA_ "NMH-WakeupAllowed" SG_ 2026 ISO_MOS_01_Resp_Data 0;
BA_ "GenSigTimeoutMsg_Gateway_B8" SG_ 2026 ISO_MOS_01_Resp_Data 2026;
BA_ "GenSigAutoGenDsp" SG_ 2019 ISO_MOS_02_Req_Data 1;
BA_ "GenSigAutoGenSnd" SG_ 2019 ISO_MOS_02_Req_Data 1;
BA_ "GenSigSendType" SG_ 2019 ISO_MOS_02_Req_Data 7;
BA_ "NWM-WakeupAllowed" SG_ 2019 ISO_MOS_02_Req_Data 0;
BA_ "NMH-WakeupAllowed" SG_ 2019 ISO_MOS_02_Req_Data 0;
BA_ "GenSigAutoGenDsp" SG_ 2027 ISO_MOS_02_Resp_Data 1;
BA_ "GenSigAutoGenSnd" SG_ 2027 ISO_MOS_02_Resp_Data 1;
BA_ "GenSigSendType" SG_ 2027 ISO_MOS_02_Resp_Data 7;
BA_ "NWM-WakeupAllowed" SG_ 2027 ISO_MOS_02_Resp_Data 0;
BA_ "NMH-WakeupAllowed" SG_ 2027 ISO_MOS_02_Resp_Data 0;
BA_ "GenSigTimeoutMsg_Gateway_B8" SG_ 2027 ISO_MOS_02_Resp_Data 2027;
BA_ "GenSigAutoGenDsp" SG_ 2023 ISO_OBD_reserv3_Req_Data 1;
BA_ "GenSigAutoGenSnd" SG_ 2023 ISO_OBD_reserv3_Req_Data 1;
BA_ "GenSigSendType" SG_ 2023 ISO_OBD_reserv3_Req_Data 7;
BA_ "NWM-WakeupAllowed" SG_ 2023 ISO_OBD_reserv3_Req_Data 0;
BA_ "NMH-WakeupAllowed" SG_ 2023 ISO_OBD_reserv3_Req_Data 0;
BA_ "GenSigAutoGenDsp" SG_ 2031 ISO_OBD_reserv3_Resp_Data 1;
BA_ "GenSigAutoGenSnd" SG_ 2031 ISO_OBD_reserv3_Resp_Data 1;
BA_ "GenSigSendType" SG_ 2031 ISO_OBD_reserv3_Resp_Data 7;
BA_ "NWM-WakeupAllowed" SG_ 2031 ISO_OBD_reserv3_Resp_Data 0;
BA_ "NMH-WakeupAllowed" SG_ 2031 ISO_OBD_reserv3_Resp_Data 0;
BA_ "GenSigTimeoutMsg_Gateway_B8" SG_ 2031 ISO_OBD_reserv3_Resp_Data 2031;
BA_ "GenSigAutoGenDsp" SG_ 2020 ISO_OBD_reserv4_Req_Data 1;
BA_ "GenSigAutoGenSnd" SG_ 2020 ISO_OBD_reserv4_Req_Data 1;
BA_ "GenSigSendType" SG_ 2020 ISO_OBD_reserv4_Req_Data 7;
BA_ "NWM-WakeupAllowed" SG_ 2020 ISO_OBD_reserv4_Req_Data 0;
BA_ "NMH-WakeupAllowed" SG_ 2020 ISO_OBD_reserv4_Req_Data 0;
BA_ "GenSigAutoGenDsp" SG_ 2028 ISO_OBD_reserv4_Resp_Data 1;
BA_ "GenSigAutoGenSnd" SG_ 2028 ISO_OBD_reserv4_Resp_Data 1;
BA_ "GenSigSendType" SG_ 2028 ISO_OBD_reserv4_Resp_Data 7;
BA_ "NWM-WakeupAllowed" SG_ 2028 ISO_OBD_reserv4_Resp_Data 0;
BA_ "NMH-WakeupAllowed" SG_ 2028 ISO_OBD_reserv4_Resp_Data 0;
BA_ "GenSigTimeoutMsg_Gateway_B8" SG_ 2028 ISO_OBD_reserv4_Resp_Data 2028;
BA_ "GenSigAutoGenDsp" SG_ 960 Klemmen_Status_01_CHK 1;
BA_ "GenSigAutoGenSnd" SG_ 960 Klemmen_Status_01_CHK 1;
BA_ "GenSigEnvVarType" SG_ 960 Klemmen_Status_01_CHK 0;
BA_ "GenSigSendType" SG_ 960 Klemmen_Status_01_CHK 7;
BA_ "NWM-WakeupAllowed" SG_ 960 Klemmen_Status_01_CHK 0;
BA_ "NMH-WakeupAllowed" SG_ 960 Klemmen_Status_01_CHK 0;
BA_ "GenSigTimeoutMsg_Daempfer_B8" SG_ 960 Klemmen_Status_01_CHK 960;
BA_ "GenSigTimeoutMsg_Getriebe_AL6000" SG_ 960 Klemmen_Status_01_CHK 960;
BA_ "GenSigTimeoutMsg_Motor_EDC17_003" SG_ 960 Klemmen_Status_01_CHK 960;
BA_ "GenSigTimeoutMsg_Motor_EDC17_004" SG_ 960 Klemmen_Status_01_CHK 960;
BA_ "GenSigTimeoutMsg_Motor_MED17_B8" SG_ 960 Klemmen_Status_01_CHK 960;
BA_ "GenSigTimeoutMsg_Motor_MED9_B8" SG_ 960 Klemmen_Status_01_CHK 960;
BA_ "GenSigTimeoutMsg_Motor_SIMOS8_B8" SG_ 960 Klemmen_Status_01_CHK 960;
BA_ "GenSigAutoGenDsp" SG_ 960 Klemmen_Status_01_BZ 1;
BA_ "GenSigAutoGenSnd" SG_ 960 Klemmen_Status_01_BZ 1;
BA_ "GenSigEnvVarType" SG_ 960 Klemmen_Status_01_BZ 0;
BA_ "GenSigSendType" SG_ 960 Klemmen_Status_01_BZ 7;
BA_ "NWM-WakeupAllowed" SG_ 960 Klemmen_Status_01_BZ 0;
BA_ "NMH-WakeupAllowed" SG_ 960 Klemmen_Status_01_BZ 0;
BA_ "GenSigTimeoutMsg_Daempfer_B8" SG_ 960 Klemmen_Status_01_BZ 960;
BA_ "GenSigTimeoutMsg_Getriebe_AL6000" SG_ 960 Klemmen_Status_01_BZ 960;
BA_ "GenSigTimeoutMsg_Motor_EDC17_003" SG_ 960 Klemmen_Status_01_BZ 960;
BA_ "GenSigTimeoutMsg_Motor_EDC17_004" SG_ 960 Klemmen_Status_01_BZ 960;
BA_ "GenSigTimeoutMsg_Motor_MED17_B8" SG_ 960 Klemmen_Status_01_BZ 960;
BA_ "GenSigTimeoutMsg_Motor_MED9_B8" SG_ 960 Klemmen_Status_01_BZ 960;
BA_ "GenSigTimeoutMsg_Motor_SIMOS8_B8" SG_ 960 Klemmen_Status_01_BZ 960;
BA_ "GenSigAutoGenDsp" SG_ 960 ZAS_Kl_S 1;
BA_ "GenSigAutoGenSnd" SG_ 960 ZAS_Kl_S 1;
BA_ "GenSigEnvVarType" SG_ 960 ZAS_Kl_S 0;
BA_ "GenSigSendType" SG_ 960 ZAS_Kl_S 7;
BA_ "NWM-WakeupAllowed" SG_ 960 ZAS_Kl_S 0;
BA_ "NMH-WakeupAllowed" SG_ 960 ZAS_Kl_S 0;
BA_ "GenSigAutoGenDsp" SG_ 960 ZAS_Kl_15 1;
BA_ "GenSigAutoGenSnd" SG_ 960 ZAS_Kl_15 1;
BA_ "GenSigEnvVarType" SG_ 960 ZAS_Kl_15 0;
BA_ "GenSigSendType" SG_ 960 ZAS_Kl_15 7;
BA_ "NWM-WakeupAllowed" SG_ 960 ZAS_Kl_15 1;
BA_ "NMH-WakeupAllowed" SG_ 960 ZAS_Kl_15 0;
BA_ "GenSigTimeoutMsg_Daempfer_B8" SG_ 960 ZAS_Kl_15 960;
BA_ "GenSigTimeoutMsg_Getriebe_AL6000" SG_ 960 ZAS_Kl_15 960;
BA_ "GenSigTimeoutMsg_Getriebe_DL5001" SG_ 960 ZAS_Kl_15 960;
BA_ "GenSigTimeoutMsg_Motor_EDC17_003" SG_ 960 ZAS_Kl_15 960;
BA_ "GenSigTimeoutMsg_Motor_EDC17_004" SG_ 960 ZAS_Kl_15 960;
BA_ "GenSigTimeoutMsg_Motor_MED17_B8" SG_ 960 ZAS_Kl_15 960;
BA_ "GenSigTimeoutMsg_Motor_MED9_B8" SG_ 960 ZAS_Kl_15 960;
BA_ "GenSigTimeoutMsg_Motor_SIMOS8_B8" SG_ 960 ZAS_Kl_15 960;
BA_ "GenSigAutoGenDsp" SG_ 960 ZAS_Kl_X 1;
BA_ "GenSigAutoGenSnd" SG_ 960 ZAS_Kl_X 1;
BA_ "GenSigEnvVarType" SG_ 960 ZAS_Kl_X 0;
BA_ "GenSigSendType" SG_ 960 ZAS_Kl_X 7;
BA_ "NWM-WakeupAllowed" SG_ 960 ZAS_Kl_X 0;
BA_ "NMH-WakeupAllowed" SG_ 960 ZAS_Kl_X 0;
BA_ "GenSigTimeoutMsg_AFS_B8" SG_ 960 ZAS_Kl_X 960;
BA_ "GenSigTimeoutMsg_Daempfer_B8" SG_ 960 ZAS_Kl_X 960;
BA_ "GenSigAutoGenDsp" SG_ 960 ZAS_Kl_50 1;
BA_ "GenSigAutoGenSnd" SG_ 960 ZAS_Kl_50 1;
BA_ "GenSigEnvVarType" SG_ 960 ZAS_Kl_50 0;
BA_ "GenSigSendType" SG_ 960 ZAS_Kl_50 7;
BA_ "NWM-WakeupAllowed" SG_ 960 ZAS_Kl_50 0;
BA_ "NMH-WakeupAllowed" SG_ 960 ZAS_Kl_50 0;
BA_ "GenSigTimeoutMsg_AFS_B8" SG_ 960 ZAS_Kl_50 960;
BA_ "GenSigTimeoutMsg_Daempfer_B8" SG_ 960 ZAS_Kl_50 960;
BA_ "GenSigTimeoutMsg_Motor_EDC17_003" SG_ 960 ZAS_Kl_50 960;
BA_ "GenSigTimeoutMsg_Motor_EDC17_004" SG_ 960 ZAS_Kl_50 960;
BA_ "GenSigTimeoutMsg_Motor_MED17_B8" SG_ 960 ZAS_Kl_50 960;
BA_ "GenSigTimeoutMsg_Motor_MED9_B8" SG_ 960 ZAS_Kl_50 960;
BA_ "GenSigTimeoutMsg_Motor_SIMOS8_B8" SG_ 960 ZAS_Kl_50 960;
BA_ "GenSigAutoGenDsp" SG_ 959 KL_Drehz_Anh 1;
BA_ "GenSigAutoGenSnd" SG_ 959 KL_Drehz_Anh 1;
BA_ "GenSigEnvVarType" SG_ 959 KL_Drehz_Anh 0;
BA_ "GenSigSendType" SG_ 959 KL_Drehz_Anh 7;
BA_ "NWM-WakeupAllowed" SG_ 959 KL_Drehz_Anh 0;
BA_ "NMH-WakeupAllowed" SG_ 959 KL_Drehz_Anh 0;
BA_ "GenSigTimeoutMsg_Motor_EDC17_003" SG_ 959 KL_Drehz_Anh 959;
BA_ "GenSigTimeoutMsg_Motor_EDC17_004" SG_ 959 KL_Drehz_Anh 959;
BA_ "GenSigTimeoutMsg_Motor_MED17_B8" SG_ 959 KL_Drehz_Anh 959;
BA_ "GenSigTimeoutMsg_Motor_MED9_B8" SG_ 959 KL_Drehz_Anh 959;
BA_ "GenSigTimeoutMsg_Motor_SIMOS8_B8" SG_ 959 KL_Drehz_Anh 959;
BA_ "GenSigAutoGenDsp" SG_ 959 KL_Vorwarn_Komp_ein 1;
BA_ "GenSigAutoGenSnd" SG_ 959 KL_Vorwarn_Komp_ein 1;
BA_ "GenSigEnvVarType" SG_ 959 KL_Vorwarn_Komp_ein 0;
BA_ "GenSigSendType" SG_ 959 KL_Vorwarn_Komp_ein 7;
BA_ "NWM-WakeupAllowed" SG_ 959 KL_Vorwarn_Komp_ein 0;
BA_ "NMH-WakeupAllowed" SG_ 959 KL_Vorwarn_Komp_ein 0;
BA_ "GenSigTimeoutMsg_Motor_EDC17_003" SG_ 959 KL_Vorwarn_Komp_ein 959;
BA_ "GenSigTimeoutMsg_Motor_EDC17_004" SG_ 959 KL_Vorwarn_Komp_ein 959;
BA_ "GenSigTimeoutMsg_Motor_MED17_B8" SG_ 959 KL_Vorwarn_Komp_ein 959;
BA_ "GenSigTimeoutMsg_Motor_MED9_B8" SG_ 959 KL_Vorwarn_Komp_ein 959;
BA_ "GenSigTimeoutMsg_Motor_SIMOS8_B8" SG_ 959 KL_Vorwarn_Komp_ein 959;
BA_ "GenSigAutoGenDsp" SG_ 959 KL_Handshake_BEM 1;
BA_ "GenSigAutoGenSnd" SG_ 959 KL_Handshake_BEM 1;
BA_ "GenSigEnvVarType" SG_ 959 KL_Handshake_BEM 0;
BA_ "GenSigSendType" SG_ 959 KL_Handshake_BEM 7;
BA_ "NWM-WakeupAllowed" SG_ 959 KL_Handshake_BEM 0;
BA_ "NMH-WakeupAllowed" SG_ 959 KL_Handshake_BEM 0;
BA_ "GenSigAutoGenDsp" SG_ 959 KL_Komp_Moment_alt 1;
BA_ "GenSigAutoGenSnd" SG_ 959 KL_Komp_Moment_alt 1;
BA_ "GenSigEnvVarType" SG_ 959 KL_Komp_Moment_alt 0;
BA_ "GenSigSendType" SG_ 959 KL_Komp_Moment_alt 7;
BA_ "NWM-WakeupAllowed" SG_ 959 KL_Komp_Moment_alt 0;
BA_ "NMH-WakeupAllowed" SG_ 959 KL_Komp_Moment_alt 0;
BA_ "GenSigAutoGenDsp" SG_ 959 KL_Vorwarn_HHS_ein 1;
BA_ "GenSigAutoGenSnd" SG_ 959 KL_Vorwarn_HHS_ein 1;
BA_ "GenSigEnvVarType" SG_ 959 KL_Vorwarn_HHS_ein 0;
BA_ "GenSigSendType" SG_ 959 KL_Vorwarn_HHS_ein 7;
BA_ "NWM-WakeupAllowed" SG_ 959 KL_Vorwarn_HHS_ein 0;
BA_ "NMH-WakeupAllowed" SG_ 959 KL_Vorwarn_HHS_ein 0;
BA_ "GenSigTimeoutMsg_Motor_EDC17_003" SG_ 959 KL_Vorwarn_HHS_ein 959;
BA_ "GenSigTimeoutMsg_Motor_EDC17_004" SG_ 959 KL_Vorwarn_HHS_ein 959;
BA_ "GenSigTimeoutMsg_Motor_MED17_B8" SG_ 959 KL_Vorwarn_HHS_ein 959;
BA_ "GenSigTimeoutMsg_Motor_MED9_B8" SG_ 959 KL_Vorwarn_HHS_ein 959;
BA_ "GenSigTimeoutMsg_Motor_SIMOS8_B8" SG_ 959 KL_Vorwarn_HHS_ein 959;
BA_ "GenSigAutoGenDsp" SG_ 959 KL_Vorwarn_HFS_ein 1;
BA_ "GenSigAutoGenSnd" SG_ 959 KL_Vorwarn_HFS_ein 1;
BA_ "GenSigEnvVarType" SG_ 959 KL_Vorwarn_HFS_ein 0;
BA_ "GenSigSendType" SG_ 959 KL_Vorwarn_HFS_ein 7;
BA_ "NWM-WakeupAllowed" SG_ 959 KL_Vorwarn_HFS_ein 0;
BA_ "NMH-WakeupAllowed" SG_ 959 KL_Vorwarn_HFS_ein 0;
BA_ "GenSigTimeoutMsg_Motor_EDC17_003" SG_ 959 KL_Vorwarn_HFS_ein 959;
BA_ "GenSigTimeoutMsg_Motor_EDC17_004" SG_ 959 KL_Vorwarn_HFS_ein 959;
BA_ "GenSigTimeoutMsg_Motor_MED17_B8" SG_ 959 KL_Vorwarn_HFS_ein 959;
BA_ "GenSigTimeoutMsg_Motor_MED9_B8" SG_ 959 KL_Vorwarn_HFS_ein 959;
BA_ "GenSigTimeoutMsg_Motor_SIMOS8_B8" SG_ 959 KL_Vorwarn_HFS_ein 959;
BA_ "GenSigAutoGenDsp" SG_ 959 KL_Vorwarn_Zuheizer_ein 1;
BA_ "GenSigAutoGenSnd" SG_ 959 KL_Vorwarn_Zuheizer_ein 1;
BA_ "GenSigEnvVarType" SG_ 959 KL_Vorwarn_Zuheizer_ein 0;
BA_ "GenSigSendType" SG_ 959 KL_Vorwarn_Zuheizer_ein 7;
BA_ "NWM-WakeupAllowed" SG_ 959 KL_Vorwarn_Zuheizer_ein 0;
BA_ "NMH-WakeupAllowed" SG_ 959 KL_Vorwarn_Zuheizer_ein 0;
BA_ "GenSigAutoGenDsp" SG_ 959 KL_KD_Fehler 1;
BA_ "GenSigAutoGenSnd" SG_ 959 KL_KD_Fehler 1;
BA_ "GenSigEnvVarType" SG_ 959 KL_KD_Fehler 1;
BA_ "GenSigSendType" SG_ 959 KL_KD_Fehler 7;
BA_ "NWM-WakeupAllowed" SG_ 959 KL_KD_Fehler 0;
BA_ "NMH-WakeupAllowed" SG_ 959 KL_KD_Fehler 0;
BA_ "GenSigAutoGenDsp" SG_ 959 KL_Last_Kompr 1;
BA_ "GenSigAutoGenSnd" SG_ 959 KL_Last_Kompr 1;
BA_ "GenSigEnvVarType" SG_ 959 KL_Last_Kompr 1;
BA_ "GenSigSendType" SG_ 959 KL_Last_Kompr 7;
BA_ "NWM-WakeupAllowed" SG_ 959 KL_Last_Kompr 0;
BA_ "NMH-WakeupAllowed" SG_ 959 KL_Last_Kompr 0;
BA_ "GenSigTimeoutMsg_Motor_EDC17_003" SG_ 959 KL_Last_Kompr 959;
BA_ "GenSigTimeoutMsg_Motor_EDC17_004" SG_ 959 KL_Last_Kompr 959;
BA_ "GenSigTimeoutMsg_Motor_MED17_B8" SG_ 959 KL_Last_Kompr 959;
BA_ "GenSigTimeoutMsg_Motor_MED9_B8" SG_ 959 KL_Last_Kompr 959;
BA_ "GenSigTimeoutMsg_Motor_SIMOS8_B8" SG_ 959 KL_Last_Kompr 959;
BA_ "GenSigAutoGenDsp" SG_ 959 KL_Leistung_Hzg_Soll 1;
BA_ "GenSigAutoGenSnd" SG_ 959 KL_Leistung_Hzg_Soll 1;
BA_ "GenSigEnvVarType" SG_ 959 KL_Leistung_Hzg_Soll 1;
BA_ "GenSigSendType" SG_ 959 KL_Leistung_Hzg_Soll 7;
BA_ "NWM-WakeupAllowed" SG_ 959 KL_Leistung_Hzg_Soll 0;
BA_ "NMH-WakeupAllowed" SG_ 959 KL_Leistung_Hzg_Soll 0;
BA_ "GenSigAutoGenDsp" SG_ 959 KL_Anf_KL 1;
BA_ "GenSigAutoGenSnd" SG_ 959 KL_Anf_KL 1;
BA_ "GenSigEnvVarType" SG_ 959 KL_Anf_KL 1;
BA_ "GenSigSendType" SG_ 959 KL_Anf_KL 7;
BA_ "NWM-WakeupAllowed" SG_ 959 KL_Anf_KL 0;
BA_ "NMH-WakeupAllowed" SG_ 959 KL_Anf_KL 0;
BA_ "GenSigTimeoutMsg_Motor_EDC17_003" SG_ 959 KL_Anf_KL 959;
BA_ "GenSigTimeoutMsg_Motor_EDC17_004" SG_ 959 KL_Anf_KL 959;
BA_ "GenSigTimeoutMsg_Motor_MED17_B8" SG_ 959 KL_Anf_KL 959;
BA_ "GenSigTimeoutMsg_Motor_MED9_B8" SG_ 959 KL_Anf_KL 959;
BA_ "GenSigTimeoutMsg_Motor_SIMOS8_B8" SG_ 959 KL_Anf_KL 959;
BA_ "GenSigAutoGenDsp" SG_ 959 KL_4_Zonen 1;
BA_ "GenSigAutoGenSnd" SG_ 959 KL_4_Zonen 1;
BA_ "GenSigSendType" SG_ 959 KL_4_Zonen 7;
BA_ "NWM-WakeupAllowed" SG_ 959 KL_4_Zonen 0;
BA_ "NMH-WakeupAllowed" SG_ 959 KL_4_Zonen 0;
BA_ "GenSigTimeoutMsg_Motor_EDC17_003" SG_ 959 KL_4_Zonen 959;
BA_ "GenSigTimeoutMsg_Motor_EDC17_004" SG_ 959 KL_4_Zonen 959;
BA_ "GenSigTimeoutMsg_Motor_MED17_B8" SG_ 959 KL_4_Zonen 959;
BA_ "GenSigTimeoutMsg_Motor_MED9_B8" SG_ 959 KL_4_Zonen 959;
BA_ "GenSigTimeoutMsg_Motor_SIMOS8_B8" SG_ 959 KL_4_Zonen 959;
BA_ "GenSigAutoGenDsp" SG_ 959 KL_AC_Schalter 1;
BA_ "GenSigAutoGenSnd" SG_ 959 KL_AC_Schalter 1;
BA_ "GenSigEnvVarType" SG_ 959 KL_AC_Schalter 0;
BA_ "GenSigSendType" SG_ 959 KL_AC_Schalter 7;
BA_ "NWM-WakeupAllowed" SG_ 959 KL_AC_Schalter 0;
BA_ "NMH-WakeupAllowed" SG_ 959 KL_AC_Schalter 0;
BA_ "GenSigAutoGenDsp" SG_ 959 KL_Zustand 1;
BA_ "GenSigAutoGenSnd" SG_ 959 KL_Zustand 1;
BA_ "GenSigEnvVarType" SG_ 959 KL_Zustand 0;
BA_ "GenSigSendType" SG_ 959 KL_Zustand 7;
BA_ "NWM-WakeupAllowed" SG_ 959 KL_Zustand 0;
BA_ "NMH-WakeupAllowed" SG_ 959 KL_Zustand 0;
BA_ "GenSigTimeoutMsg_Motor_EDC17_003" SG_ 959 KL_Zustand 959;
BA_ "GenSigTimeoutMsg_Motor_EDC17_004" SG_ 959 KL_Zustand 959;
BA_ "GenSigTimeoutMsg_Motor_MED17_B8" SG_ 959 KL_Zustand 959;
BA_ "GenSigTimeoutMsg_Motor_MED9_B8" SG_ 959 KL_Zustand 959;
BA_ "GenSigTimeoutMsg_Motor_SIMOS8_B8" SG_ 959 KL_Zustand 959;
BA_ "GenSigAutoGenDsp" SG_ 959 KL_el_Zuheizer_Stufe 1;
BA_ "GenSigAutoGenSnd" SG_ 959 KL_el_Zuheizer_Stufe 1;
BA_ "GenSigEnvVarType" SG_ 959 KL_el_Zuheizer_Stufe 0;
BA_ "GenSigSendType" SG_ 959 KL_el_Zuheizer_Stufe 7;
BA_ "NWM-WakeupAllowed" SG_ 959 KL_el_Zuheizer_Stufe 0;
BA_ "NMH-WakeupAllowed" SG_ 959 KL_el_Zuheizer_Stufe 0;
BA_ "GenSigTimeoutMsg_Motor_EDC17_003" SG_ 959 KL_el_Zuheizer_Stufe 959;
BA_ "GenSigTimeoutMsg_Motor_EDC17_004" SG_ 959 KL_el_Zuheizer_Stufe 959;
VAL_ 262 ESP_QBit_Bremsdruck 0 "gültiger Wert" 1 "Ersatz-, Init- oder Fehlerwert" ;
VAL_ 262 ESP_QBit_Fahrer_bremst 0 "gültiger Wert" 1 "Ersatz-, Init- oder Fehlerwert" ;
VAL_ 262 ESP_Schwelle_Unterdruck 0 "kein Signal" 3 "Fehler Unterdrucksensor" 1 "Unterdruck <= 450 mbar" 2 "Unterdruck > 450 mbar" ;
VAL_ 262 ESP_Bremsdruck 1023 "Fehler" ;
VAL_ 262 ESP_Fahrer_bremst 0 "Fahrer bremst nicht" 1 "Fahrer bremst" ;
VAL_ 262 ESP_Verz_TSK_aktiv 1 "TSK-Verzögerung aktiv" 0 "TSK-Verzögerung inaktiv" ;
VAL_ 262 ESP_Lenkeingriff_ADS 1 "stabilisierender Lenkeingriff" 0 "kein Lenkeingriff" ;
VAL_ 262 ESP_Konsistenz_TSK 1 "Botschaft für Verzögerungsanforderung nicht konsistent" 0 "Botschaft für Verzögerungsanforderung konsistent " ;
VAL_ 262 ESP_Konsistenz_AWV2 0 "Botschaft für AWV2 konsistent" 1 "Botschaft für AWV2 nicht konsistent" ;
VAL_ 262 ECD_Fehler 0 "ECD iO" 1 "ECD Fehler" ;
VAL_ 262 ECD_nicht_verfuegbar 0 "ECD Funktion verfügbar" 1 "ECD Funktion nicht verfügbar" ;
VAL_ 262 ESP_Status_Bremsentemp 0 "Bremse nicht überhitzt" 1 "Bremse überhitzt" ;
VAL_ 262 ESP_Autohold_Standby 0 "Autohold nicht im Standby" 1 "Autohold im Standby" ;
VAL_ 262 ESP_HDC_Standby 0 "HDC-Funktion nicht im Standby" 1 "HDC-Funktion im Standby" ;
VAL_ 262 ESP_BKV_Unterdruck 255 "Fehler" ;
VAL_ 262 ESP_Autohold_aktiv 1 "Autohold aktiv" 0 "Autohold inaktiv" ;
VAL_ 262 ESP_FStatus_Anfahrhilfe 0 "kein Fehler" 1 "Fehler" ;
VAL_ 262 ESP_Verz_EPB_aktiv 0 "nicht aktiviert" 1 "aktiviert" ;
VAL_ 262 ECD_Bremslicht 0 "Aus" 1 "Ein" ;
VAL_ 262 ESP_Verzoeg_EPB_verf 0 "nicht verfuegbar" 1 "System verfuegbar" ;
VAL_ 262 ESP_Status_Bremsdruck 0 "Bremse drucklos" 1 "mit Bremsdruck" ;
VAL_ 262 ESP_Anforderung_EPB 1 "Anforderung Öffnen" 0 "keine Anforderung" 2 "Anforderung Schliessen" 3 "reserviert" ;
VAL_ 1721 ESP_Variante_Bremse 0 "keine Variante hinterlegt" ;
VAL_ 264 FA_Hoehenwerte_kalibriert 1 "Rohwerte" 0 "kalibrierte Höhenwerte in mm" ;
VAL_ 264 FA_Hoehenwert_VL_00 254 "nicht initialisiert" 255 "Fehler" ;
VAL_ 264 FA_Hoehenwert_VL_01 254 "nicht initialisiert" 255 "Fehler" ;
VAL_ 264 FA_Hoehenwert_VR_00 254 "nicht initialisiert" 255 "Fehler" ;
VAL_ 264 FA_Hoehenwert_VR_01 254 "nicht initialisiert" 255 "Fehler" ;
VAL_ 264 FA_Hoehenwert_HL_00 254 "nicht initialisiert" 255 "Fehler" ;
VAL_ 264 FA_Hoehenwert_HL_01 254 "nicht initialisiert" 255 "Fehler" ;
VAL_ 264 FA_Hoehenwert_HR_00 254 "nicht initialisiert" 255 "Fehler" ;
VAL_ 264 FA_Hoehenwert_HR_01 254 "nicht initialisiert" 255 "Fehler" ;
VAL_ 924 BCM1_02_alt 0 "aktuell" 1 "veraltet" ;
VAL_ 924 Wischer_01_alt 0 "aktuell" 1 "veraltet" ;
VAL_ 924 Klima_02_alt 0 "aktuell" 1 "veraltet" ;
VAL_ 924 BCM1_01_alt 0 "aktuell" 1 "veraltet" ;
VAL_ 924 ESP_07_alt 0 "aktuell" 1 "veraltet" ;
VAL_ 924 Klima_Sensor_02_alt 0 "aktuell" 1 "veraltet" ;
VAL_ 924 TSG_FT_1_alt 0 "aktuell" 1 "veraltet" ;
VAL_ 924 Motor_05_alt 0 "aktuell" 1 "veraltet" ;
VAL_ 924 BCM1_MH_WIV_Schalter 0 "MH geschlossen" 1 "MH offen" ;
VAL_ 924 Wischer_vorne_aktiv 1 "Wischer vorne läuft" ;
VAL_ 924 BCM1_Rueckfahrlicht_Schalter 0 "aus" 1 "betaetigt" ;
VAL_ 924 KL_Zuheizer_Freigabe 1 "Zuheizerfreigabe" 0 "keine Freigabe Zuheizer" ;
VAL_ 924 BCM1_Vorwaertsgang_eingelegt 0 "Rueckwaertsgang bzw. restliche Gaenge eingelegt" 1 "Erster oder zweiter Gang eingelegt" ;
VAL_ 924 ESP_Codierung_ADS 3 "tbd." 1 "ESP nicht ADS codiert" 0 "Init" 2 "ADS codiert" ;
VAL_ 924 BCM1_RFahrlicht_Fzg_Anf 1 "Licht ist einzuschalten" ;
VAL_ 924 FT_Tuer_geoeffnet 1 "Tuer offen" ;
VAL_ 924 MO_Handshake_STH 0 "keine EKP-Ansteuerung durch STH-Anforderung" 1 "EKP-Ansteuerung durch STH-Anforderung" ;
VAL_ 924 BCM1_OBD_FStatus_ATemp 0 "kein Fehler" 1 "KS-" 5 "OOR- (out of range low)" 10 "KS-/KS+" 9 "KS-/OC" 3 "OC (Leitungsunterbrechung)" 11 "KS-/KS+/OC (allgemeiner Fehler)" 8 "KS+/OC" 4 "OOR+ (out of range high)" 6 "RC+ (Signal unplausibel hoch)" 7 "RC- (Signal unplausibel niedrig)" 2 "KS+" ;
VAL_ 924 BCM1_Aussen_Temp_ungef 253 "nicht verbaut" 254 "Initwert" 255 "Fehler" ;
VAL_ 924 BCM1_Oeldruck_Schalter 1 "geschlossen (p > p soll)" 0 "offen" ;
VAL_ 924 BCM1_Oeldruck_Schalter_2 0 "offen" 1 "geschlossen" ;
VAL_ 1604 SMLS_01_alt 0 "aktuell" 1 "veraltet" ;
VAL_ 1604 BCM1_01_alt 0 "aktuell" 1 "veraltet" ;
VAL_ 1604 BCM1_02_alt 0 "aktuell" 1 "veraltet" ;
VAL_ 1604 BCM2_02_alt 0 "aktuell" 1 "veraltet" ;
VAL_ 1604 BH_Blinker_li 1 "Blinkerhebel Richtung links betaetigt" ;
VAL_ 1604 BH_Blinker_re 1 "Blinkerhebel Richtung rechts betaetigt" ;
VAL_ 1604 BM_Autobahn 0 "Autobahnblinken nicht aktiv " 1 "Autobahnblinken aktiv " ;
VAL_ 1604 BCM1_Touristen_Licht_Anf 1 "Anforderung von Touristenlicht" ;
VAL_ 1604 LV_Abblendlicht_li_def 0 "OK" 1 "defekt" ;
VAL_ 1604 LV_Abblendlicht_re_def 1 "defekt" 0 "OK" ;
VAL_ 1604 LV_Abblendlicht_Anzeige 1 "aktiv" 0 "nicht aktiv" ;
VAL_ 1604 BCM2_P_verriegelt 0 "WH nicht in Stellung P" 1 "WH in Stellung P" ;
VAL_ 1138 Anhaenger_01_alt 0 "aktuell" 1 "veraltet" ;
VAL_ 1138 Kombi_01_alt 0 "aktuell" 1 "veraltet" ;
VAL_ 1138 STH_01_alt 0 "aktuell" 1 "veraltet" ;
VAL_ 1138 Licht_hinten_01_alt 0 "aktuell" 1 "veraltet" ;
VAL_ 1138 AAG_Bremsl_durch_ECD 0 "Bremslicht ist aus" 1 "Bremslicht durch ECD aktiv" ;
VAL_ 1138 AAG_Anhaenger_erkannt 1 "Anhaenger erkannt" ;
VAL_ 1138 AAG_Bremslicht_H_def 1 "Anhaenger Bremslicht defekt" ;
VAL_ 1138 KBI_Tankwarnung 1 "Lampe ein" 0 "Lampe aus" ;
VAL_ 1138 KBI_MFA_v_Einheit_01 0 "kmh" 1 "mph" ;
VAL_ 1138 KBI_Einheit_Tacho 0 "km/h" 1 "mph" ;
VAL_ 1138 STH_EKP_Anst 1 "EKP ansteuern" 0 "EKP nicht ansteuern" ;
VAL_ 1138 STH_Motorvorwaermung 0 "keine Motorvorwärmung erfolgt" 1 "Aufheizung mit Motorvorwärmung erfolgt" ;
VAL_ 1138 STH_war_aktiv 0 "war inaktiv" 1 "Standheizung war letzte halbe Stunde aktiv" ;
VAL_ 1138 BCM2_Bremsl_durch_ECD 1 "Bremslicht durch ECD aktiv" 0 "Bremslicht ist aus" ;
VAL_ 1138 LH_3_Bremsl_def 1 "hochgesetzte  Bremsleuchte defekt" 0 "OK" ;
VAL_ 1138 LH_Bremsl_li_ges_def 1 "Alle Bremslichter hinten links defekt" 0 "OK" ;
VAL_ 1138 LH_Bremsl_re_ges_def 1 "Alle Bremslichter hinten rechts defekt" 0 "OK" ;
VAL_ 130 GE_Schaltvorgang 0 "keine Schaltung" 1 "Schaltung aktiv" ;
VAL_ 130 GE_Status_Kupplung 0 "Kupplung geöffnet" 2 "Kupplung geschlossen" 1 "Kupplung geregelt" 3 "Fehler" ;
VAL_ 130 GE_MMom_Soll 1022 "kein Eingriff" 1023 "Fehler" ;
VAL_ 130 GE_MMom_Status 0 "keine Anforderung" 2 "erhöhender Getriebeeingriff" 3 "Änderung mit Sprung" 1 "reduzierender Getriebeeingriff" ;
VAL_ 130 GE_Mom_MZP 1022 "Init" ;
VAL_ 130 GE_Freig_Mom_Eingriff 1 "Momenteneingriffsanforderung Motorsollmoment/ Momenten-Ident möglich" 0 "keine Freigabe Motorsollmoment/ Momenten-Ident" ;
VAL_ 130 GE_Mom_Ident 0 "Init" 15 "Fehler" ;
VAL_ 130 GE_KD_Fehler 1 "eingetragen" 0 "nicht eingetragen" ;
VAL_ 131 GE_Synchro_Wunschdrehz 511 "Fehler" ;
VAL_ 131 GE_Synchro_Zeit 255 "Fehler" ;
VAL_ 131 GE_Mom_Begr_Gradient 255 "keine Begrenzung (Init)" ;
VAL_ 131 GE_Anheb_Solldrehz_Leerlauf 255 "Fehler" ;
VAL_ 131 GE_Vorsteuermoment 510 "Init" 511 "Fehler" ;
VAL_ 131 GE_Drehzahlmesser_Daempfung 1 "dynamische Dämpfung" 0 "normale Dämpfung" ;
VAL_ 131 GE_Schubabschalt_Unt 1 "aktiv" 0 "inaktiv" ;
VAL_ 131 GE_Freigabe_Synchro 1 "aktiv" 0 "inaktiv" ;
VAL_ 258 GE_Freig_Langfr_Schutzmom 0 "nicht freigegeben" 1 "freigegeben" ;
VAL_ 258 GE_Uefkt 1023 "Fehler" ;
VAL_ 258 GE_Zielgang 12 "Gang 9 (Empfängerseitig zu implementieren)" 11 "Gang 8 (Empfängerseitig zu implementieren)" 3 "Gang 3" 5 "Gang 5" 1 "Gang 1" 4 "Gang 4" 7 "Gang 7" 0 "Gang P/N (ausgekuppelt)" 2 "Gang 2" 6 "Gang 6" 14 "Istgang nicht definiert" 8 "Gang R" 15 "Fehler" ;
VAL_ 258 GE_Langfr_Schutzmom 1022 "Init" 1023 "Fehler" ;
VAL_ 258 GE_Waehlhebel 14 "Tippfunktion" 0 "Zwischenstellung (Darf nur für Zustandswechsel P/R, R/N, N/D ausgegeben werden, nicht für D/S oder D/Tippgasse wegen Abschaltkriterium GRA/ACC)" 9 "Position S" 7 "Position N" 5 "Position P" 6 "Position R" 8 "Position D" 1 "Init" 15 "Fehler" ;
VAL_ 258 GE_Eingangsdrehz 16382 "Init" 16383 "Fehler" ;
VAL_ 258 GE_Notlauf 1 "Getriebe im Notlauf" 0 "kein Notlauf / Init" ;
VAL_ 258 GE_Codierung_MSG 1 "Codierung niO" 0 "Codierung iO / Init" ;
VAL_ 1089 GE_Index_Fahrwid 255 "Fehler" ;
VAL_ 1089 GE_OBD_Status 1 " MIL ein" 0 "MIL aus" ;
VAL_ 1089 GE_LFR_Adaption 1 "fuer_Adaption_nicht_geeignet" 0 "fuer_Adaption_geeignet" ;
VAL_ 1089 GE_Grenzkriechmoment 62 "Init" 63 "Fehler" ;
VAL_ 1089 GE_Verlustmoment 255 "Fehler" ;
VAL_ 1089 GE_amax_moeglich 511 "Wert ist nicht definiert" ;
VAL_ 1089 GE_Sumpftemperatur 255 "Fehler" ;
VAL_ 960 ZAS_Kl_S 0 "aus" 1 " S-Kontakt ein" ;
VAL_ 960 ZAS_Kl_15 1 "ein" 0 "aus" ;
VAL_ 960 ZAS_Kl_X 1 "ein" 0 "aus" ;
VAL_ 960 ZAS_Kl_50 0 "aus" 1 " klemme 50 ein (Startwunsch Fahrer)" ;
VAL_ 959 KL_Drehz_Anh 1 "Drehzahlanhebung vom Motor angefordert" 0 "keine Anhebung " ;
VAL_ 959 KL_Vorwarn_Komp_ein 1 "Vorwarnung Kompressor ein" ;
VAL_ 959 KL_Handshake_BEM 1 "Heizleistungsaenderung wird gerade durchgeführt" 0 "keine Leistungsaenderung in den Heizsystemen aktiv" ;
VAL_ 959 KL_Komp_Moment_alt 1 "veraltet, bzw Ermittlung des Moments nicht moeglich (z.B. keine Drehzahl, kein Kaeltemitteldruck)" ;
VAL_ 959 KL_Vorwarn_HHS_ein 1 "Vorwarnung Heckscheibenheizung ein" ;
VAL_ 959 KL_Vorwarn_HFS_ein 1 "Vorwarnung Frontscheibenheizung ein" ;
VAL_ 959 KL_Vorwarn_Zuheizer_ein 1 "Vorwarnung Zuheizer ein" ;
VAL_ 959 KL_KD_Fehler 1 "min ein KD - Fehlerspeichereintrag vorhanden" ;
VAL_ 959 KL_Last_Kompr 255 "Fehler" ;
VAL_ 959 KL_Anf_KL 255 "Fehler" ;
VAL_ 959 KL_4_Zonen 0 "2_Zonen_Klimaanlage" 1 "4_Zonen_Klimaanlage" ;
VAL_ 959 KL_AC_Schalter 1 "ein" 0 "aus" ;
VAL_ 959 KL_Zustand 1 "ein" 0 "aus" ;
